VERSION ""

NS_ :

BS_:
BU_: AerodynamicControl AuxiliaryHeater1 AuxiliaryHeater2 AuxiliaryValveControl AxleDrive1 AxleDrive2 AxleSteering BodyController BrakesDriveAxle1 BrakesDriveAxle2 BrakesSteerAxle BrakesSystemController CabController1 CabController2 CabDisplay1 ChassisController1 ChassisController2 ClimateControl1 ClimateControl2 ClutchUnit CommunicationUnitCellular CommunicationUnitRadio CommunicationUnitSatellite CruiseControl ElectricalChargingSystem ElectricalSystem EnduranceBrakingSystem Engine1 Engine2 EngineValveControl ExhaustEmissionController FanDriveController FileServer FuelSystem HeadwayController HitchControl HydraulicPumpController IgnitionController1 IgnitionController2 InformationSystem1 InstrumentCluster LightingOperatorControl ManagementComputer Node_0 Node_1 Node_10 Node_11 Node_12 Node_129 Node_13 Node_130 Node_133 Node_14 Node_15 Node_16 Node_17 Node_18 Node_19 Node_2 Node_20 Node_21 Node_22 Node_23 Node_24 Node_248 Node_249 Node_25 Node_250 Node_251 Node_26 Node_27 Node_28 Node_29 Node_3 Node_30 Node_31 Node_32 Node_33 Node_34 Node_35 Node_36 Node_37 Node_38 Node_39 Node_4 Node_40 Node_41 Node_42 Node_43 Node_44 Node_45 Node_46 Node_47 Node_48 Node_49 Node_5 Node_50 Node_51 Node_52 Node_53 Node_54 Node_55 Node_56 Node_57 Node_58 Node_59 Node_6 Node_60 Node_61 Node_62 Node_63 Node_64 Node_65 Node_66 Node_67 Node_68 Node_69 Node_7 Node_70 Node_71 Node_72 Node_73 Node_74 Node_75 Node_76 Node_77 Node_78 Node_79 Node_8 Node_80 Node_9 OffBoardDiagnosticTool1 OffBoardDiagnosticTool2 OffVehicleGateway OilSensor OnBoardDataLogger OnBoardDiagnosticUnit ParkingBrakeController PneumaticSystemController PowerTakeOff PowerTakeOffFront PropulsionBatteryCharger RampControl RearAxleSteeringController RetarderDriveline RetarderEngine RetarderExhaustEngine1 RetarderExhaustEngine2 SeatControl2 SeatController1 ShiftConsolePrimary ShiftConsoleSecondary StarterSystem SteeringColumnUnit SteeringController SuspensionDriveAxle1 SuspensionDriveAxle2 SuspensionSteerAxle SuspensionSystemController1 SuspensionSystemController2 TirePressureController TractorTrailerBridge1 Transmission1 Transmission2 TransmissionDisplay1 TransmissionDisplay2 TripRecorder Turbocharger VehicleDynamicStability VehicleNavigation VehicleSecurity VirtualTerminal WaterPumpController

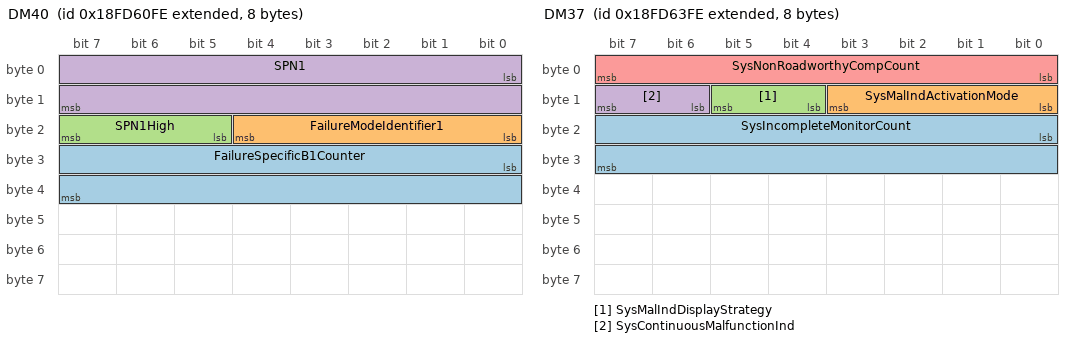
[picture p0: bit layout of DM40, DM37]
BO_ 2566742270 DM40: 8 Vector__XXX
   SG_ FailureSpecificB1Counter : 24|16@1+ (0.1,0) [0|6425.5] "hr" Vector__XXX
   SG_ FailureModeIdentifier1 : 16|5@1+ (1,0) [0|0] "" Vector__XXX
   SG_ SPN1High : 21|3@1+ (1,0) [0|7] "" Vector__XXX
   SG_ SPN1 : 0|16@1+ (1,0) [0|65536] "" Vector__XXX

BO_ 2566742526 DM39: 8 Vector__XXX
   SG_ SysGreatestB1Counter : 32|16@1+ (0.1,0) [0|6425.5] "hr" Vector__XXX
   SG_ SysCumulativeContinuousMITime : 0|32@1+ (0.05,0) [0|2.10554e+08] "hr" Vector__XXX

BO_ 2566742782 DM38: 8 Vector__XXX
   SG_ RegulationDescription : 0|8@1+ (1,0) [0|255] "" Vector__XXX

BO_ 2566743038 DM37: 8 Vector__XXX
   SG_ SysIncompleteMonitorCount : 16|16@1+ (1,0) [0|64512] "" Vector__XXX
   SG_ SysMalIndActivationMode : 8|4@1+ (1,0) [0|15] "" Vector__XXX
   SG_ SysMalIndDisplayStrategy : 12|2@1+ (1,0) [0|3] "" Vector__XXX
   SG_ SysContinuousMalfunctionInd : 14|2@1+ (1,0) [0|3] "" Vector__XXX
   SG_ SysNonRoadworthyCompCount : 0|8@1+ (1,0) [0|250] "" Vector__XXX

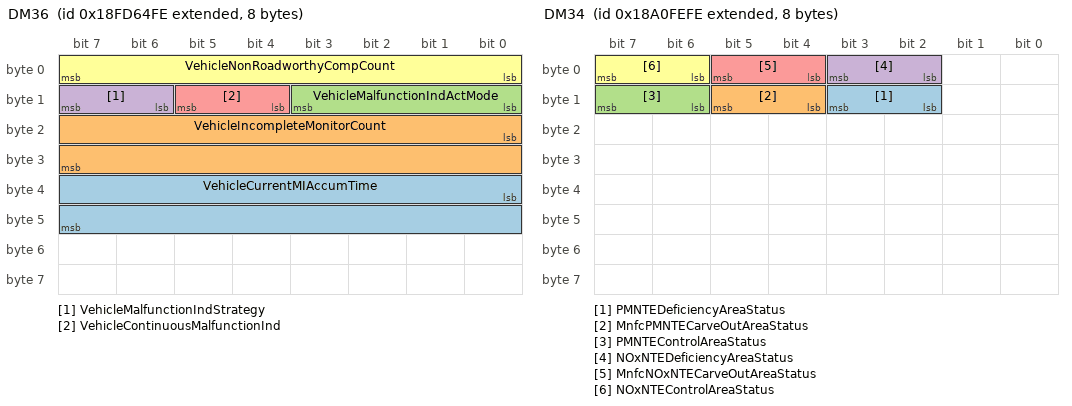
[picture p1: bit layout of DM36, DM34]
BO_ 2566743294 DM36: 8 Vector__XXX
   SG_ VehicleCurrentMIAccumTime : 32|16@1+ (1,0) [0|64255] "min" Vector__XXX
   SG_ VehicleIncompleteMonitorCount : 16|16@1+ (1,0) [0|64255] "" Vector__XXX
   SG_ VehicleMalfunctionIndActMode : 8|4@1+ (1,0) [0|15] "" Vector__XXX
   SG_ VehicleMalfunctionIndStrategy : 14|2@1+ (1,0) [0|3] "" Vector__XXX
   SG_ VehicleContinuousMalfunctionInd : 12|2@1+ (1,0) [0|3] "" Vector__XXX
   SG_ VehicleNonRoadworthyCompCount : 0|8@1+ (1,0) [0|250] "" Vector__XXX

BO_ 2560687870 DM34: 8 Vector__XXX
   SG_ PMNTEDeficiencyAreaStatus : 10|2@1+ (1,0) [0|3] "" Vector__XXX
   SG_ MnfcPMNTECarveOutAreaStatus : 12|2@1+ (1,0) [0|3] "" Vector__XXX
   SG_ PMNTEControlAreaStatus : 14|2@1+ (1,0) [0|3] "" Vector__XXX
   SG_ NOxNTEDeficiencyAreaStatus : 2|2@1+ (1,0) [0|3] "" Vector__XXX
   SG_ MnfcNOxNTECarveOutAreaStatus : 4|2@1+ (1,0) [0|3] "" Vector__XXX
   SG_ NOxNTEControlAreaStatus : 6|2@1+ (1,0) [0|3] "" Vector__XXX

BO_ 2292317950 DM33: 9 Vector__XXX
   SG_ AECDEngineHours1Timer2 : 40|32@1+ (1,0) [0|4.29497e+09] "min" Vector__XXX
   SG_ AECDEngineHours1Timer1 : 8|32@1+ (1,0) [0|4.29497e+09] "min" Vector__XXX
   SG_ AECDNumber1 : 0|8@1+ (1,0) [0|250] "" Vector__XXX

BO_ 2566809342 BM: 8 Vector__XXX
   SG_ BatteryMainSwitchHoldState : 0|2@1+ (1,0) [0|3] "" Vector__XXX

BO_ 2365446910 BJM3: 8 Vector__XXX
   SG_ Joystick3XAxisDetentPosStatus : 38|2@1+ (1,0) [0|3] "" Vector__XXX
   SG_ Joystick3Button9PressedStatus : 62|2@1+ (1,0) [0|3] "" Vector__XXX
   SG_ Joystick3Button10PressedStatus : 60|2@1+ (1,0) [0|3] "" Vector__XXX
   SG_ Joystick3Button11PressedStatus : 58|2@1+ (1,0) [0|3] "" Vector__XXX
   SG_ Joystick3Button12PressedStatus : 56|2@1+ (1,0) [0|3] "" Vector__XXX
   SG_ Joystick3YAxisDetentPosStatus : 36|2@1+ (1,0) [0|3] "" Vector__XXX
   SG_ Joystick3YAxisPos : 22|10@1+ (0.1,0) [0|102] "%" Vector__XXX
   SG_ Jystck3YAxsLvrFrwrdPstvPsStatus : 20|2@1+ (1,0) [0|3] "" Vector__XXX
   SG_ Jystck3YAxsLvrBckNgtvePosStatus : 18|2@1+ (1,0) [0|3] "" Vector__XXX
   SG_ Joystick3YAxisNeutralPosStatus : 16|2@1+ (1,0) [0|3] "" Vector__XXX
   SG_ Joystick3XAxisPos : 6|10@1+ (0.1,0) [0|102] "%" Vector__XXX
   SG_ Jystck3XAxsLvrRghtPstvPosStatus : 4|2@1+ (1,0) [0|3] "" Vector__XXX
   SG_ Jystck3XAxsLvrLftNgtvePosStatus : 2|2@1+ (1,0) [0|3] "" Vector__XXX
   SG_ Joystick3XAxisNeutralPosStatus : 0|2@1+ (1,0) [0|3] "" Vector__XXX
   SG_ Joystick3Button5PressedStatus : 54|2@1+ (1,0) [0|3] "" Vector__XXX
   SG_ Joystick3Button6PressedStatus : 52|2@1+ (1,0) [0|3] "" Vector__XXX
   SG_ Joystick3Button7PressedStatus : 50|2@1+ (1,0) [0|3] "" Vector__XXX
   SG_ Joystick3Button8PressedStatus : 48|2@1+ (1,0) [0|3] "" Vector__XXX
   SG_ Joystick3Button1PressedStatus : 46|2@1+ (1,0) [0|3] "" Vector__XXX
   SG_ Joystick3Button2PressedStatus : 44|2@1+ (1,0) [0|3] "" Vector__XXX
   SG_ Joystick3Button3PressedStatus : 42|2@1+ (1,0) [0|3] "" Vector__XXX
   SG_ Joystick3Button4PressedStatus : 40|2@1+ (1,0) [0|3] "" Vector__XXX

BO_ 2365446398 BJM2: 8 Vector__XXX
   SG_ Joystick2XAxisDetentPosStatus : 38|2@1+ (1,0) [0|3] "" Vector__XXX
   SG_ Joystick2YAxisDetentPosStatus : 36|2@1+ (1,0) [0|3] "" Vector__XXX
   SG_ Joystick2YAxisPos : 22|10@1+ (0.1,0) [0|102] "%" Vector__XXX
   SG_ Jystck2YAxsLvrFrwrdPstvPsStatus : 20|2@1+ (1,0) [0|3] "" Vector__XXX
   SG_ Jystck2YAxsLvrBckNgtvePosStatus : 18|2@1+ (1,0) [0|3] "" Vector__XXX
   SG_ Joystick2YAxisNeutralPosStatus : 16|2@1+ (1,0) [0|3] "" Vector__XXX
   SG_ Joystick2XAxisPos : 6|10@1+ (0.1,0) [0|102] "%" Vector__XXX
   SG_ Jystck2XAxsLvrRghtPstvPosStatus : 4|2@1+ (1,0) [0|3] "" Vector__XXX
   SG_ Jystck2XAxsLvrLftNgtvePosStatus : 2|2@1+ (1,0) [0|3] "" Vector__XXX
   SG_ Joystick2XAxisNeutralPosStatus : 0|2@1+ (1,0) [0|3] "" Vector__XXX
   SG_ Joystick2Button9PressedStatus : 62|2@1+ (1,0) [0|3] "" Vector__XXX
   SG_ Joystick2Button10PressedStatus : 60|2@1+ (1,0) [0|3] "" Vector__XXX
   SG_ Joystick2Button11PressedStatus : 58|2@1+ (1,0) [0|3] "" Vector__XXX
   SG_ Joystick2Button12PressedStatus : 56|2@1+ (1,0) [0|3] "" Vector__XXX
   SG_ Joystick2Button5PressedStatus : 54|2@1+ (1,0) [0|3] "" Vector__XXX
   SG_ Joystick2Button6PressedStatus : 52|2@1+ (1,0) [0|3] "" Vector__XXX
   SG_ Joystick2Button7PressedStatus : 50|2@1+ (1,0) [0|3] "" Vector__XXX
   SG_ Joystick2Button8PressedStatus : 48|2@1+ (1,0) [0|3] "" Vector__XXX
   SG_ Joystick2Button1PressedStatus : 46|2@1+ (1,0) [0|3] "" Vector__XXX
   SG_ Joystick2Button2PressedStatus : 44|2@1+ (1,0) [0|3] "" Vector__XXX
   SG_ Joystick2Button3PressedStatus : 42|2@1+ (1,0) [0|3] "" Vector__XXX
   SG_ Joystick2Button4PressedStatus : 40|2@1+ (1,0) [0|3] "" Vector__XXX

BO_ 2365445886 BJM1: 8 Vector__XXX
   SG_ Joystick1XAxisDetentPosStatus : 38|2@1+ (1,0) [0|3] "" Vector__XXX
   SG_ Joystick1YAxisDetentPosStatus : 36|2@1+ (1,0) [0|3] "" Vector__XXX
   SG_ Joystick1YAxisPos : 22|10@1+ (0.1,0) [0|102] "%" Vector__XXX
   SG_ Jystck1YAxsLvrFrwrdPstvPsStatus : 20|2@1+ (1,0) [0|3] "" Vector__XXX
   SG_ Jystck1YAxsLvrBckNgtvePosStatus : 18|2@1+ (1,0) [0|3] "" Vector__XXX
   SG_ Joystick1YAxisNeutralPosStatus : 16|2@1+ (1,0) [0|3] "" Vector__XXX
   SG_ Joystick1XAxisPos : 6|10@1+ (0.1,0) [0|102] "%" Vector__XXX
   SG_ Joystick1Button9PressedStatus : 62|2@1+ (1,0) [0|3] "" Vector__XXX
   SG_ Joystick1Button10PressedStatus : 60|2@1+ (1,0) [0|3] "" Vector__XXX
   SG_ Joystick1Button11PressedStatus : 58|2@1+ (1,0) [0|3] "" Vector__XXX
   SG_ Joystick1Button12PressedStatus : 56|2@1+ (1,0) [0|3] "" Vector__XXX
   SG_ Joystick1Button5PressedStatus : 54|2@1+ (1,0) [0|3] "" Vector__XXX
   SG_ Joystick1Button6PressedStatus : 52|2@1+ (1,0) [0|3] "" Vector__XXX
   SG_ Joystick1Button7PressedStatus : 50|2@1+ (1,0) [0|3] "" Vector__XXX
   SG_ Joystick1Button8PressedStatus : 48|2@1+ (1,0) [0|3] "" Vector__XXX
   SG_ Joystick1Button1PressedStatus : 46|2@1+ (1,0) [0|3] "" Vector__XXX
   SG_ Joystick1Button2PressedStatus : 44|2@1+ (1,0) [0|3] "" Vector__XXX
   SG_ Joystick1Button3PressedStatus : 42|2@1+ (1,0) [0|3] "" Vector__XXX
   SG_ Joystick1Button4PressedStatus : 40|2@1+ (1,0) [0|3] "" Vector__XXX
   SG_ Jystck1XAxsLvrRghtPstvPosStatus : 4|2@1+ (1,0) [0|3] "" Vector__XXX
   SG_ Jystck1XAxsLvrLftNgtvePosStatus : 2|2@1+ (1,0) [0|3] "" Vector__XXX
   SG_ Joystick1XAxisNeutralPosStatus : 0|2@1+ (1,0) [0|3] "" Vector__XXX

BO_ 2566847230 B: 8 Vector__XXX
   SG_ ParkingBrakeRedWarningSignal : 26|2@1+ (1,0) [0|3] "" Vector__XXX
   SG_ ParkBrakeReleaseInhibitStatus : 28|2@1+ (1,0) [0|3] "" Vector__XXX
   SG_ ParkingBrakeActuator : 24|2@1+ (1,0) [0|3] "" Vector__XXX
   SG_ BrakeSecondPress : 16|8@1+ (4,0) [0|1000] "kPa" Vector__XXX
   SG_ BrakePrimaryPress : 8|8@1+ (4,0) [0|1000] "kPa" Vector__XXX
   SG_ BrakeAppPress : 0|8@1+ (4,0) [0|1000] "kPa" Vector__XXX

BO_ 2566848254 AWPP: 8 Vector__XXX
   SG_ AuxPumpPress : 0|8@1+ (16,0) [0|4000] "kPa" Vector__XXX

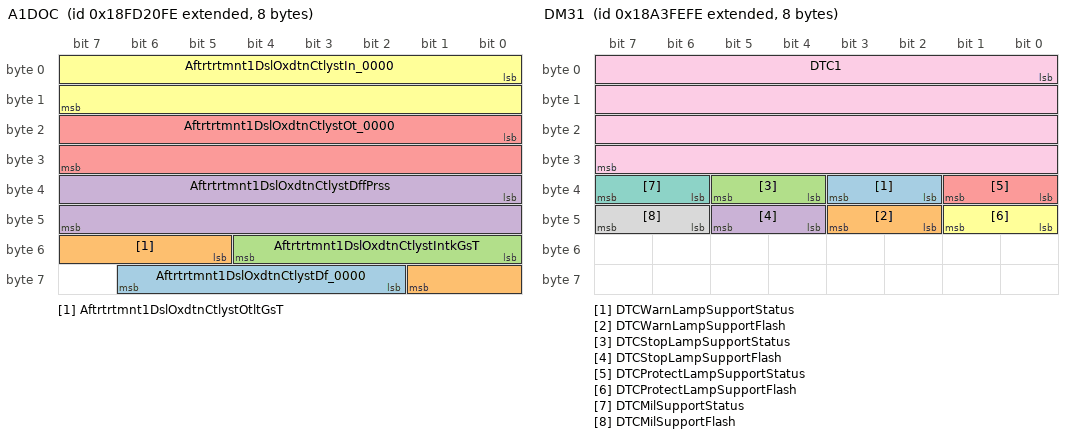
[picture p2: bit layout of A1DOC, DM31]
BO_ 2566725886 A1DOC: 8 Vector__XXX
   SG_ Aftrtrtmnt1DslOxdtnCtlystDf_0000 : 58|5@1+ (1,0) [0|31] "" Vector__XXX
   SG_ Aftrtrtmnt1DslOxdtnCtlystOtltGsT : 53|5@1+ (1,0) [0|31] "" Vector__XXX
   SG_ Aftrtrtmnt1DslOxdtnCtlystIntkGsT : 48|5@1+ (1,0) [0|31] "" Vector__XXX
   SG_ Aftrtrtmnt1DslOxdtnCtlystDffPrss : 32|16@1+ (0.1,0) [0|6425.5] "kPa" Vector__XXX
   SG_ Aftrtrtmnt1DslOxdtnCtlystOt_0000 : 16|16@1+ (0.03125,-273) [-273|1734.97] "deg C" Vector__XXX
   SG_ Aftrtrtmnt1DslOxdtnCtlystIn_0000 : 0|16@1+ (0.03125,-273) [-273|1734.97] "deg C" Vector__XXX

BO_ 2560884478 DM31: 8 Vector__XXX
   SG_ DTCWarnLampSupportStatus : 34|2@1+ (1,0) [0|3] "" Vector__XXX
   SG_ DTCWarnLampSupportFlash : 42|2@1+ (1,0) [0|3] "" Vector__XXX
   SG_ DTCStopLampSupportStatus : 36|2@1+ (1,0) [0|3] "" Vector__XXX
   SG_ DTCStopLampSupportFlash : 44|2@1+ (1,0) [0|3] "" Vector__XXX
   SG_ DTCProtectLampSupportStatus : 32|2@1+ (1,0) [0|3] "" Vector__XXX
   SG_ DTCProtectLampSupportFlash : 40|2@1+ (1,0) [0|3] "" Vector__XXX
   SG_ DTCMilSupportStatus : 38|2@1+ (1,0) [0|3] "" Vector__XXX
   SG_ DTCMilSupportFlash : 46|2@1+ (1,0) [0|3] "" Vector__XXX
   SG_ DTC1 : 0|32@1+ (1,0) [0|4.29497e+09] "" Vector__XXX

BO_ 2633844734 TML: 8 Vector__XXX

BO_ 2560360190 PMI: 8 Vector__XXX
   SG_ DataDictionaryMethod : 11|21@1+ (1,0) [0|2.09715e+06] "" Vector__XXX
   SG_ DataDictionaryManufacturerCode : 0|11@1+ (1,0) [0|2047] "" Vector__XXX

BO_ 2566736126 O2FT2: 8 Vector__XXX
   SG_ ShorttermFuelTrimBank2 : 16|16@1+ (0.1,-100) [-100|100] "%" Vector__XXX
   SG_ LongtermFuelTrimBank2 : 0|16@1+ (0.1,-100) [-100|100] "%" Vector__XXX
   SG_ EngExhstGsOxygnSnsrClsdLpOprtnBn : 32|4@1+ (1,0) [0|15] "" Vector__XXX

BO_ 2566736382 O2FT1: 8 Vector__XXX
   SG_ ShorttermFuelTrimBank1 : 16|16@1+ (0.1,-100) [-100|100] "%" Vector__XXX
   SG_ LongtermFuelTrimBank1 : 0|16@1+ (0.1,-100) [-100|100] "%" Vector__XXX
   SG_ EngExhstGsOxygnSnsrClsdLpOp_0000 : 32|4@1+ (1,0) [0|15] "" Vector__XXX

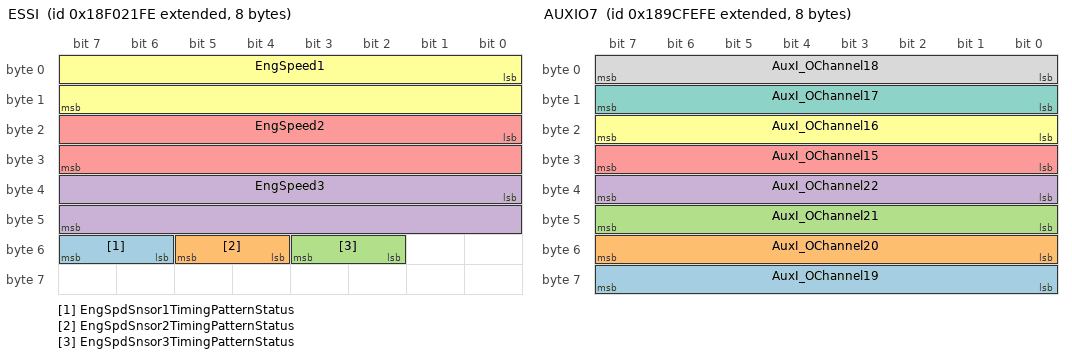
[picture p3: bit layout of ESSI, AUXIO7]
BO_ 2565874174 ESSI: 8 Vector__XXX
   SG_ EngSpdSnsor1TimingPatternStatus : 54|2@1+ (1,0) [0|3] "" Vector__XXX
   SG_ EngSpdSnsor2TimingPatternStatus : 52|2@1+ (1,0) [0|3] "" Vector__XXX
   SG_ EngSpdSnsor3TimingPatternStatus : 50|2@1+ (1,0) [0|3] "" Vector__XXX
   SG_ EngSpeed3 : 32|16@1+ (0.5,0) [0|32127.5] "rpm" Vector__XXX
   SG_ EngSpeed2 : 16|16@1+ (0.5,0) [0|32127.5] "rpm" Vector__XXX
   SG_ EngSpeed1 : 0|16@1+ (0.5,0) [0|32127.5] "rpm" Vector__XXX

BO_ 2432520958 ECCVC: 8 Vector__XXX
   SG_ DsrdEngCoolantThermostatOpening : 16|8@1+ (0.4,0) [0|100] "%" Vector__XXX
   SG_ DesiredEngCoolantPumpOutletTemp : 8|8@1+ (1,-40) [-40|210] "deg C" Vector__XXX
   SG_ EngCoolantThermostatMode : 0|2@1+ (1,0) [0|3] "" Vector__XXX

BO_ 2560425726 AUXIO7: 8 Vector__XXX
   SG_ AuxI_OChannel19 : 56|8@1+ (1,0) [0|250] "" Vector__XXX
   SG_ AuxI_OChannel20 : 48|8@1+ (1,0) [0|250] "" Vector__XXX
   SG_ AuxI_OChannel21 : 40|8@1+ (1,0) [0|250] "" Vector__XXX
   SG_ AuxI_OChannel22 : 32|8@1+ (1,0) [0|250] "" Vector__XXX
   SG_ AuxI_OChannel15 : 24|8@1+ (1,0) [0|250] "" Vector__XXX
   SG_ AuxI_OChannel16 : 16|8@1+ (1,0) [0|250] "" Vector__XXX
   SG_ AuxI_OChannel17 : 8|8@1+ (1,0) [0|250] "" Vector__XXX
   SG_ AuxI_OChannel18 : 0|8@1+ (1,0) [0|250] "" Vector__XXX

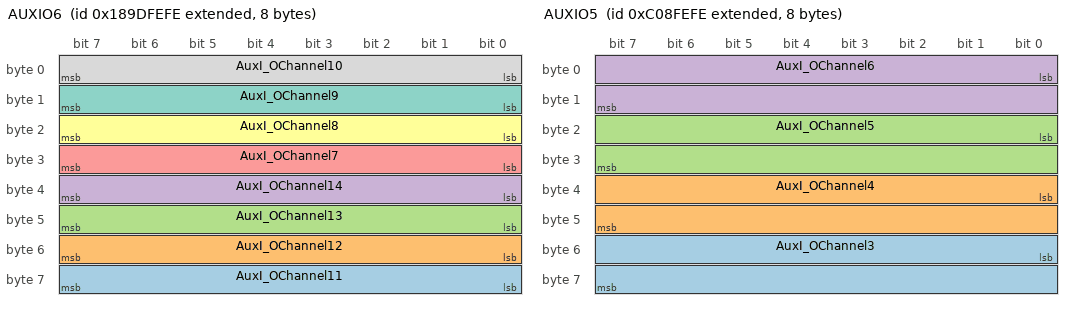
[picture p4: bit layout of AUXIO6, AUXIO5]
BO_ 2560491262 AUXIO6: 8 Vector__XXX
   SG_ AuxI_OChannel11 : 56|8@1+ (1,0) [0|250] "" Vector__XXX
   SG_ AuxI_OChannel12 : 48|8@1+ (1,0) [0|250] "" Vector__XXX
   SG_ AuxI_OChannel13 : 40|8@1+ (1,0) [0|250] "" Vector__XXX
   SG_ AuxI_OChannel14 : 32|8@1+ (1,0) [0|250] "" Vector__XXX
   SG_ AuxI_OChannel7 : 24|8@1+ (1,0) [0|250] "" Vector__XXX
   SG_ AuxI_OChannel8 : 16|8@1+ (1,0) [0|250] "" Vector__XXX
   SG_ AuxI_OChannel9 : 8|8@1+ (1,0) [0|250] "" Vector__XXX
   SG_ AuxI_OChannel10 : 0|8@1+ (1,0) [0|250] "" Vector__XXX

BO_ 2349399806 AUXIO5: 8 Vector__XXX
   SG_ AuxI_OChannel3 : 48|16@1+ (1,0) [0|64255] "counts" Vector__XXX
   SG_ AuxI_OChannel4 : 32|16@1+ (1,0) [0|64255] "counts" Vector__XXX
   SG_ AuxI_OChannel5 : 16|16@1+ (1,0) [0|64255] "counts" Vector__XXX
   SG_ AuxI_OChannel6 : 0|16@1+ (1,0) [0|64255] "counts" Vector__XXX

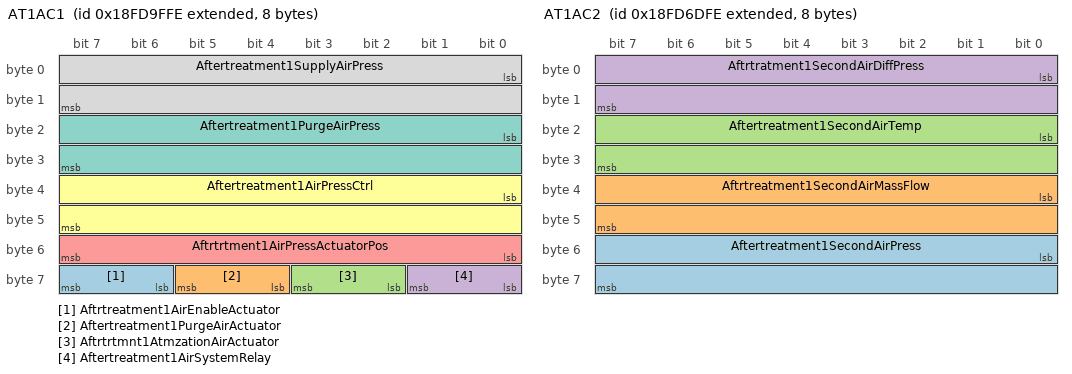
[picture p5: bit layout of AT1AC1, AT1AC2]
BO_ 2566758398 AT1AC1: 8 Vector__XXX
   SG_ Aftrtreatment1AirEnableActuator : 62|2@1+ (1,0) [0|3] "" Vector__XXX
   SG_ Aftertreatment1PurgeAirActuator : 60|2@1+ (1,0) [0|3] "" Vector__XXX
   SG_ Aftrtrtmnt1AtmzationAirActuator : 58|2@1+ (1,0) [0|3] "" Vector__XXX
   SG_ Aftertreatment1AirSystemRelay : 56|2@1+ (1,0) [0|3] "" Vector__XXX
   SG_ Aftrtrtment1AirPressActuatorPos : 48|8@1+ (0.4,0) [0|100] "%" Vector__XXX
   SG_ Aftertreatment1AirPressCtrl : 32|16@1+ (0.0025,0) [0|160.637] "%" Vector__XXX
   SG_ Aftertreatment1PurgeAirPress : 16|16@1+ (0.1,0) [0|6425.5] "kPa" Vector__XXX
   SG_ Aftertreatment1SupplyAirPress : 0|16@1+ (0.1,0) [0|6425.5] "kPa" Vector__XXX

BO_ 2566745598 AT1AC2: 8 Vector__XXX
   SG_ Aftertreatment1SecondAirPress : 48|16@1+ (0.1,0) [0|6425.5] "kPa" Vector__XXX
   SG_ Aftrtreatment1SecondAirMassFlow : 32|16@1+ (0.2,0) [0|12851] "kg/h" Vector__XXX
   SG_ Aftertreatment1SecondAirTemp : 16|16@1+ (0.03125,-273) [-273|1734.97] "deg C" Vector__XXX
   SG_ Aftrtratment1SecondAirDiffPress : 0|16@1+ (0.0078125,-250) [-250|251.99] "kPa" Vector__XXX

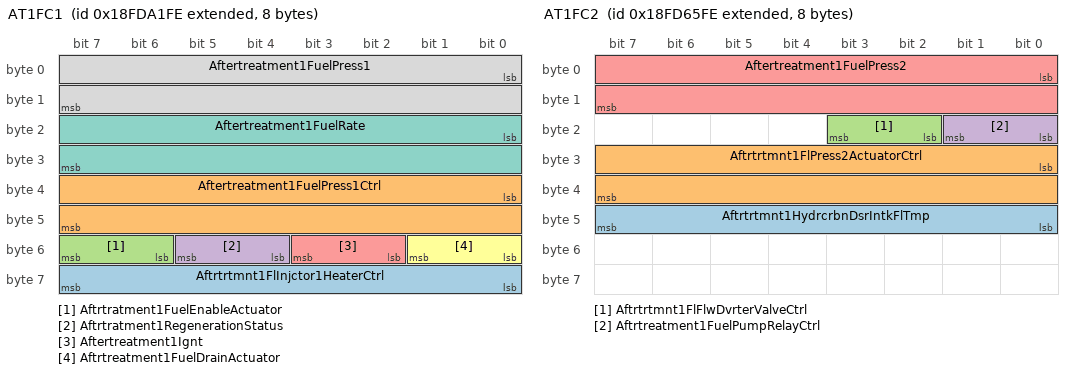
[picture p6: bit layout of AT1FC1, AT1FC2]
BO_ 2566758910 AT1FC1: 8 Vector__XXX
   SG_ Aftrtrtmnt1FlInjctor1HeaterCtrl : 56|8@1+ (0.4,0) [0|100] "%" Vector__XXX
   SG_ Aftertreatment1FuelPress1Ctrl : 32|16@1+ (0.0025,0) [0|160.637] "%" Vector__XXX
   SG_ Aftrtratment1FuelEnableActuator : 54|2@1+ (1,0) [0|3] "" Vector__XXX
   SG_ Aftrtratment1RegenerationStatus : 52|2@1+ (1,0) [0|3] "" Vector__XXX
   SG_ Aftertreatment1Ignt : 50|2@1+ (1,0) [0|3] "" Vector__XXX
   SG_ Aftrtreatment1FuelDrainActuator : 48|2@1+ (1,0) [0|3] "" Vector__XXX
   SG_ Aftertreatment1FuelRate : 16|16@1+ (0.05,0) [0|3212.75] "L/h" Vector__XXX
   SG_ Aftertreatment1FuelPress1 : 0|16@1+ (0.1,0) [0|6425.5] "kPa" Vector__XXX

BO_ 2566743550 AT1FC2: 8 Vector__XXX
   SG_ Aftrtrtmnt1HydrcrbnDsrIntkFlTmp : 40|8@1+ (1,-40) [-40|210] "deg C" Vector__XXX
   SG_ Aftrtrtmnt1FlPress2ActuatorCtrl : 24|16@1+ (0.0025,0) [0|160.637] "%" Vector__XXX
   SG_ Aftrtrtmnt1FlFlwDvrterValveCtrl : 18|2@1+ (1,0) [0|3] "" Vector__XXX
   SG_ Aftrtreatment1FuelPumpRelayCtrl : 16|2@1+ (1,0) [0|3] "" Vector__XXX
   SG_ Aftertreatment1FuelPress2 : 0|16@1+ (0.1,0) [0|6425.5] "kPa" Vector__XXX

BO_ 2566753534 AT1GP: 8 Vector__XXX
   SG_ DslPrticulateFilterOutletPress1 : 16|16@1+ (0.1,0) [0|6425.5] "kPa" Vector__XXX
   SG_ DslPrticulateFilterIntakePress1 : 0|16@1+ (0.1,0) [0|6425.5] "kPa" Vector__XXX

BO_ 2566756606 AT1HI: 36 Vector__XXX
   SG_ Aftrtrtmnt1TtlNmbrOfActvRgnrtnMn : 224|32@1+ (1,0) [0|4.29497e+09] "counts" Vector__XXX
   SG_ Aftrtrtmnt1TtlNmbrOfActvRgnrtnIn : 192|32@1+ (1,0) [0|4.29497e+09] "counts" Vector__XXX
   SG_ Aftrtrtmnt1AvrgTmBtwnActvRgnrtns : 256|32@1+ (1,0) [0|4.21108e+09] "s" Vector__XXX
   SG_ Aftrtrtmnt1TtlNmbrOfPssvRgnrtns : 160|32@1+ (1,0) [0|4.29497e+09] "counts" Vector__XXX
   SG_ Aftrtrtmnt1TtlPssvRgnrationTime : 128|32@1+ (1,0) [0|4.21108e+09] "s" Vector__XXX
   SG_ Aftrtrtmnt1TtlNmbrOfActvRgnrtns : 96|32@1+ (1,0) [0|4.29497e+09] "counts" Vector__XXX
   SG_ Aftrtreatment1TotalDisabledTime : 64|32@1+ (1,0) [0|4.21108e+09] "s" Vector__XXX
   SG_ Aftrtrtmnt1TtalRegenerationTime : 32|32@1+ (1,0) [0|4.21108e+09] "s" Vector__XXX
   SG_ Aftertreatment1TotalFuelUsed : 0|32@1+ (0.5,0) [0|2.10554e+09] "L" Vector__XXX

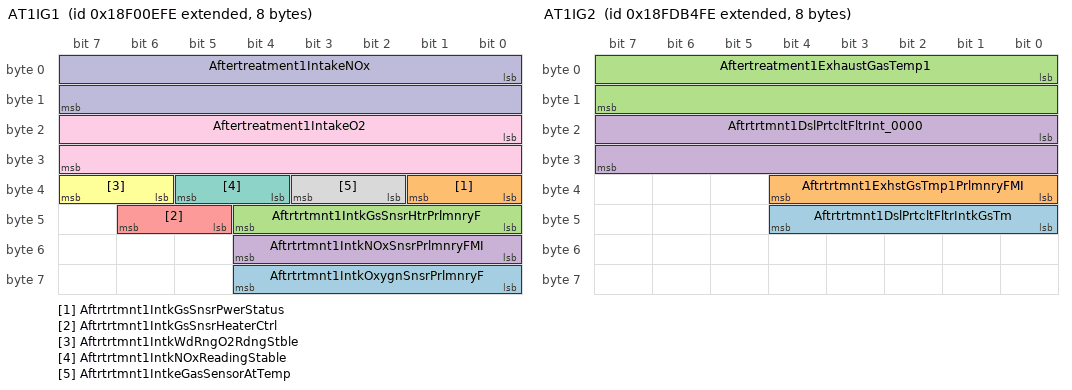
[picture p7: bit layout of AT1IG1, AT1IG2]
BO_ 2565869310 AT1IG1: 8 Vector__XXX
   SG_ Aftrtrtmnt1IntkOxygnSnsrPrlmnryF : 56|5@1+ (1,0) [0|31] "" Vector__XXX
   SG_ Aftrtrtmnt1IntkGsSnsrPwerStatus : 32|2@1+ (1,0) [0|3] "" Vector__XXX
   SG_ Aftrtrtmnt1IntkGsSnsrHtrPrlmnryF : 40|5@1+ (1,0) [0|31] "" Vector__XXX
   SG_ Aftrtrtmnt1IntkNOxSnsrPrlmnryFMI : 48|5@1+ (1,0) [0|31] "" Vector__XXX
   SG_ Aftrtrtmnt1IntkGsSnsrHeaterCtrl : 45|2@1+ (1,0) [0|3] "" Vector__XXX
   SG_ Aftrtrtmnt1IntkWdRngO2RdngStble : 38|2@1+ (1,0) [0|3] "" Vector__XXX
   SG_ Aftrtrtmnt1IntkNOxReadingStable : 36|2@1+ (1,0) [0|3] "" Vector__XXX
   SG_ Aftrtrtmnt1IntkeGasSensorAtTemp : 34|2@1+ (1,0) [0|3] "" Vector__XXX
   SG_ Aftertreatment1IntakeO2 : 16|16@1+ (0.000514,-12) [-12|21] "%" Vector__XXX
   SG_ Aftertreatment1IntakeNOx : 0|16@1+ (0.05,-200) [-200|3012.75] "ppm" Vector__XXX

BO_ 2566763774 AT1IG2: 8 Vector__XXX
   SG_ Aftrtrtmnt1DslPrtcltFltrIntkGsTm : 40|5@1+ (1,0) [0|31] "" Vector__XXX
   SG_ Aftrtrtmnt1ExhstGsTmp1PrlmnryFMI : 32|5@1+ (1,0) [0|31] "" Vector__XXX
   SG_ Aftertreatment1ExhaustGasTemp1 : 0|16@1+ (0.03125,-273) [-273|1734.97] "deg C" Vector__XXX
   SG_ Aftrtrtmnt1DslPrtcltFltrInt_0000 : 16|16@1+ (0.03125,-273) [-273|1734.97] "deg C" Vector__XXX

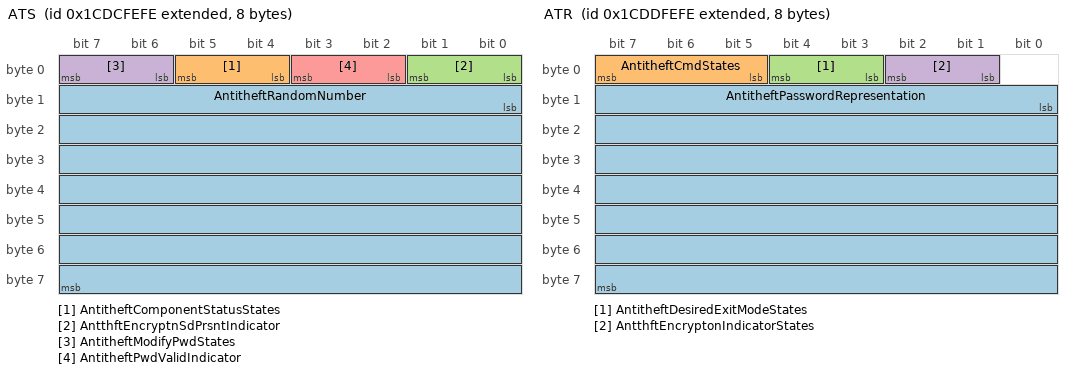
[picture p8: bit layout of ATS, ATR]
BO_ 2631728894 ATS: 8 Vector__XXX
   SG_ AntitheftRandomNumber : 8|56@1+ (1,0) [0|255] "" Vector__XXX
   SG_ AntitheftComponentStatusStates : 4|2@1+ (1,0) [0|3] "" Vector__XXX
   SG_ AntthftEncryptnSdPrsntIndicator : 0|2@1+ (1,0) [0|3] "" Vector__XXX
   SG_ AntitheftModifyPwdStates : 6|2@1+ (1,0) [0|3] "" Vector__XXX
   SG_ AntitheftPwdValidIndicator : 2|2@1+ (1,0) [0|3] "" Vector__XXX

BO_ 2631794430 ATR: 8 Vector__XXX
   SG_ AntitheftPasswordRepresentation : 8|56@1+ (1,0) [0|255] "" Vector__XXX
   SG_ AntitheftCmdStates : 5|3@1+ (1,0) [0|7] "" Vector__XXX
   SG_ AntitheftDesiredExitModeStates : 3|2@1+ (1,0) [0|3] "" Vector__XXX
   SG_ AntthftEncryptonIndicatorStates : 1|2@1+ (1,0) [0|3] "" Vector__XXX

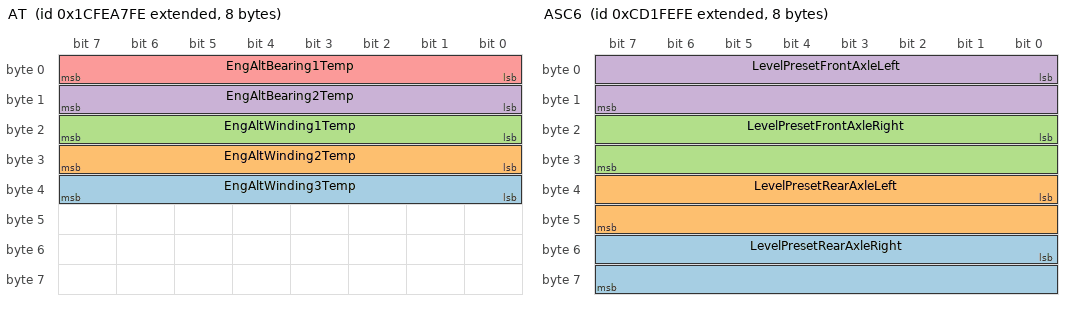
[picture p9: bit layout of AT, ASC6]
BO_ 2633934846 AT: 8 Vector__XXX
   SG_ EngAltWinding3Temp : 32|8@1+ (1,-40) [-40|210] "deg C" Vector__XXX
   SG_ EngAltWinding2Temp : 24|8@1+ (1,-40) [-40|210] "deg C" Vector__XXX
   SG_ EngAltWinding1Temp : 16|8@1+ (1,-40) [-40|210] "deg C" Vector__XXX
   SG_ EngAltBearing2Temp : 8|8@1+ (1,-40) [-40|210] "deg C" Vector__XXX
   SG_ EngAltBearing1Temp : 0|8@1+ (1,-40) [-40|210] "deg C" Vector__XXX

BO_ 2362572542 ASC6: 8 Vector__XXX
   SG_ LevelPresetRearAxleRight : 48|16@1+ (0.1,-3200) [-3200|3225.5] "mm" Vector__XXX
   SG_ LevelPresetRearAxleLeft : 32|16@1+ (0.1,-3200) [-3200|3225.5] "mm" Vector__XXX
   SG_ LevelPresetFrontAxleRight : 16|16@1+ (0.1,-3200) [-3200|3225.5] "mm" Vector__XXX
   SG_ LevelPresetFrontAxleLeft : 0|16@1+ (0.1,-3200) [-3200|3225.5] "mm" Vector__XXX

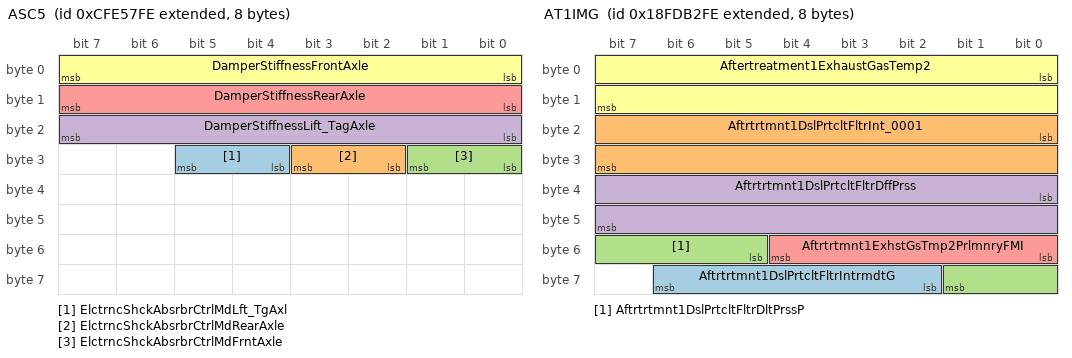
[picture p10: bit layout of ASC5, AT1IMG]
BO_ 2365478910 ASC5: 8 Vector__XXX
   SG_ ElctrncShckAbsrbrCtrlMdLft_TgAxl : 28|2@1+ (1,0) [0|3] "" Vector__XXX
   SG_ ElctrncShckAbsrbrCtrlMdRearAxle : 26|2@1+ (1,0) [0|3] "" Vector__XXX
   SG_ ElctrncShckAbsrbrCtrlMdFrntAxle : 24|2@1+ (1,0) [0|3] "" Vector__XXX
   SG_ DamperStiffnessLift_TagAxle : 16|8@1+ (0.4,0) [0|100] "%" Vector__XXX
   SG_ DamperStiffnessRearAxle : 8|8@1+ (0.4,0) [0|100] "%" Vector__XXX
   SG_ DamperStiffnessFrontAxle : 0|8@1+ (0.4,0) [0|100] "%" Vector__XXX

BO_ 2560950014 DM30: 12 Vector__XXX
   SG_ TestLimitMinimum : 80|16@1+ (1,0) [0|64255] "" Vector__XXX
   SG_ TestLimitMaximum : 64|16@1+ (1,0) [0|64255] "" Vector__XXX
   SG_ TestValue : 48|16@1+ (1,0) [0|64255] "" Vector__XXX
   SG_ SlotId : 32|16@1+ (1,0) [0|64255] "" Vector__XXX
   SG_ TestIdentifier : 0|8@1+ (1,0) [0|255] "" Vector__XXX
   SG_ FailureModeIdentifier1 : 24|5@1+ (1,0) [0|0] "" Vector__XXX
   SG_ SPN1High : 29|3@1+ (1,0) [0|7] "" Vector__XXX
   SG_ SPN1 : 8|16@1+ (1,0) [0|65536] "" Vector__XXX

BO_ 2566763262 AT1IMG: 8 Vector__XXX
   SG_ Aftrtrtmnt1DslPrtcltFltrIntrmdtG : 58|5@1+ (1,0) [0|31] "" Vector__XXX
   SG_ Aftrtrtmnt1DslPrtcltFltrInt_0001 : 16|16@1+ (0.03125,-273) [-273|1734.97] "deg C" Vector__XXX
   SG_ Aftrtrtmnt1DslPrtcltFltrDltPrssP : 53|5@1+ (1,0) [0|31] "" Vector__XXX
   SG_ Aftrtrtmnt1DslPrtcltFltrDffPrss : 32|16@1+ (0.1,0) [0|6425.5] "kPa" Vector__XXX
   SG_ Aftrtrtmnt1ExhstGsTmp2PrlmnryFMI : 48|5@1+ (1,0) [0|31] "" Vector__XXX
   SG_ Aftertreatment1ExhaustGasTemp2 : 0|16@1+ (0.03125,-273) [-273|1734.97] "deg C" Vector__XXX

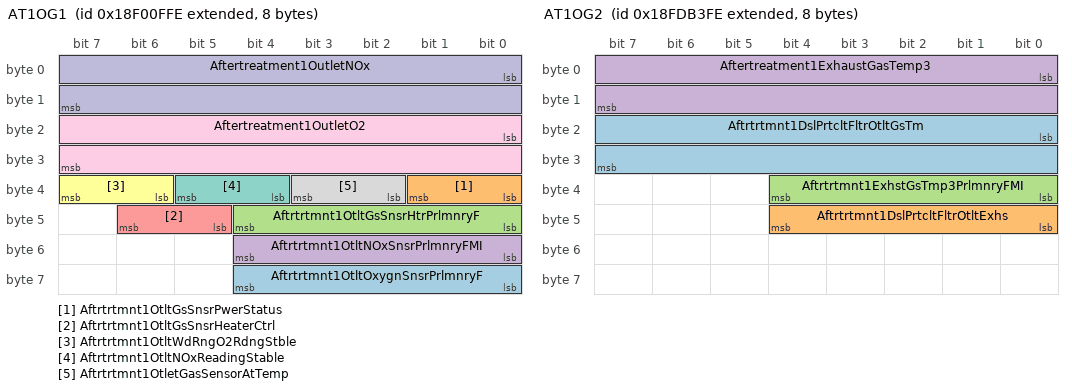
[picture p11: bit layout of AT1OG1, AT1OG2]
BO_ 2565869566 AT1OG1: 8 Vector__XXX
   SG_ Aftrtrtmnt1OtltOxygnSnsrPrlmnryF : 56|5@1+ (1,0) [0|31] "" Vector__XXX
   SG_ Aftrtrtmnt1OtltGsSnsrPwerStatus : 32|2@1+ (1,0) [0|3] "" Vector__XXX
   SG_ Aftrtrtmnt1OtltGsSnsrHtrPrlmnryF : 40|5@1+ (1,0) [0|31] "" Vector__XXX
   SG_ Aftrtrtmnt1OtltNOxSnsrPrlmnryFMI : 48|5@1+ (1,0) [0|31] "" Vector__XXX
   SG_ Aftrtrtmnt1OtltGsSnsrHeaterCtrl : 45|2@1+ (1,0) [0|3] "" Vector__XXX
   SG_ Aftrtrtmnt1OtltWdRngO2RdngStble : 38|2@1+ (1,0) [0|3] "" Vector__XXX
   SG_ Aftrtrtmnt1OtltNOxReadingStable : 36|2@1+ (1,0) [0|3] "" Vector__XXX
   SG_ Aftrtrtmnt1OtletGasSensorAtTemp : 34|2@1+ (1,0) [0|3] "" Vector__XXX
   SG_ Aftertreatment1OutletO2 : 16|16@1+ (0.000514,-12) [-12|21] "%" Vector__XXX
   SG_ Aftertreatment1OutletNOx : 0|16@1+ (0.05,-200) [-200|3012.75] "ppm" Vector__XXX

BO_ 2566763518 AT1OG2: 8 Vector__XXX
   SG_ Aftrtrtmnt1DslPrtcltFltrOtltGsTm : 16|16@1+ (0.03125,-273) [-273|1734.97] "deg C" Vector__XXX
   SG_ Aftrtrtmnt1DslPrtcltFltrOtltExhs : 40|5@1+ (1,0) [0|31] "" Vector__XXX
   SG_ Aftrtrtmnt1ExhstGsTmp3PrlmnryFMI : 32|5@1+ (1,0) [0|31] "" Vector__XXX
   SG_ Aftertreatment1ExhaustGasTemp3 : 0|16@1+ (0.03125,-273) [-273|1734.97] "deg C" Vector__XXX

BO_ 2566749182 AT1S: 8 Vector__XXX
   SG_ DslPrtclteFilter1AshLoadPercent : 8|8@1+ (1,0) [0|250] "%" Vector__XXX
   SG_ DslPrtcltFltr1TmSncLstActvRgnrtn : 16|32@1+ (1,0) [0|4.21108e+09] "s" Vector__XXX
   SG_ DslPrtcltFilter1SootLoadPercent : 0|8@1+ (1,0) [0|250] "%" Vector__XXX
   SG_ Aftrtrtmnt1DslPrtcltFltrStLdRgnr : 48|16@1+ (0.0025,0) [0|160.637] "%" Vector__XXX

BO_ 2566748670 AT1TI: 32 Vector__XXX
   SG_ Aftrtrtmnt1TrpNmbrOfActvRgnrtnMn : 224|32@1+ (1,0) [0|4.29497e+09] "counts" Vector__XXX
   SG_ Aftrtrtmnt1TrpNmbrOfActvRgnrtnIn : 192|32@1+ (1,0) [0|4.29497e+09] "counts" Vector__XXX
   SG_ Aftrtrtmnt1TrpNmbrOfPssvRgnrtns : 160|32@1+ (1,0) [0|4.29497e+09] "counts" Vector__XXX
   SG_ Aftrtrtmnt1TrpPssvRgnrationTime : 128|32@1+ (1,0) [0|4.21108e+09] "s" Vector__XXX
   SG_ Aftrtrtmnt1TrpNmbrOfActvRgnrtns : 96|32@1+ (1,0) [0|4.29497e+09] "counts" Vector__XXX
   SG_ Aftertreatment1TripDisabledTime : 64|32@1+ (1,0) [0|4.21108e+09] "s" Vector__XXX
   SG_ Aftrtrtmnt1TrpActvRgnrationTime : 32|32@1+ (1,0) [0|4.21108e+09] "s" Vector__XXX
   SG_ Aftertreatment1TripFuelUsed : 0|32@1+ (0.5,0) [0|2.10554e+09] "L" Vector__XXX

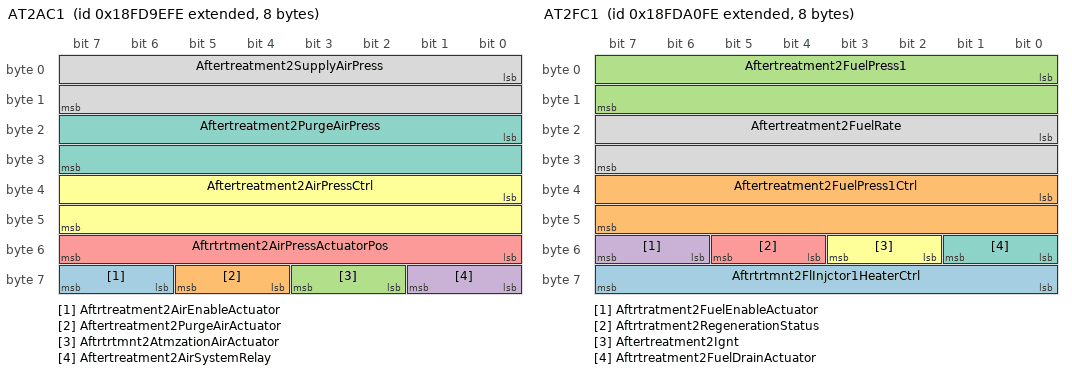
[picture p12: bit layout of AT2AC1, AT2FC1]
BO_ 2566758142 AT2AC1: 8 Vector__XXX
   SG_ Aftrtreatment2AirEnableActuator : 62|2@1+ (1,0) [0|3] "" Vector__XXX
   SG_ Aftertreatment2PurgeAirActuator : 60|2@1+ (1,0) [0|3] "" Vector__XXX
   SG_ Aftrtrtmnt2AtmzationAirActuator : 58|2@1+ (1,0) [0|3] "" Vector__XXX
   SG_ Aftertreatment2AirSystemRelay : 56|2@1+ (1,0) [0|3] "" Vector__XXX
   SG_ Aftrtrtment2AirPressActuatorPos : 48|8@1+ (0.4,0) [0|100] "%" Vector__XXX
   SG_ Aftertreatment2AirPressCtrl : 32|16@1+ (0.0025,0) [0|160.637] "%" Vector__XXX
   SG_ Aftertreatment2PurgeAirPress : 16|16@1+ (0.1,0) [0|6425.5] "kPa" Vector__XXX
   SG_ Aftertreatment2SupplyAirPress : 0|16@1+ (0.1,0) [0|6425.5] "kPa" Vector__XXX

BO_ 2566745342 AT2AC2: 8 Vector__XXX
   SG_ Aftertreatment2SecondAirPress : 48|16@1+ (0.1,0) [0|6425.5] "kPa" Vector__XXX
   SG_ Aftrtreatment2SecondAirMassFlow : 32|16@1+ (0.2,0) [0|12851] "kg/h" Vector__XXX
   SG_ Aftertreatment2SecondAirTemp : 16|16@1+ (0.03125,-273) [-273|1734.97] "deg C" Vector__XXX
   SG_ Aftrtratment2SecondAirDiffPress : 0|16@1+ (0.0078125,-250) [-250|251.99] "kPa" Vector__XXX

BO_ 2566758654 AT2FC1: 8 Vector__XXX
   SG_ Aftrtrtmnt2FlInjctor1HeaterCtrl : 56|8@1+ (0.4,0) [0|100] "%" Vector__XXX
   SG_ Aftertreatment2FuelPress1Ctrl : 32|16@1+ (0.0025,0) [0|160.637] "%" Vector__XXX
   SG_ Aftertreatment2FuelPress1 : 0|16@1+ (0.1,0) [0|6425.5] "kPa" Vector__XXX
   SG_ Aftrtratment2FuelEnableActuator : 54|2@1+ (1,0) [0|3] "" Vector__XXX
   SG_ Aftrtratment2RegenerationStatus : 52|2@1+ (1,0) [0|3] "" Vector__XXX
   SG_ Aftertreatment2Ignt : 50|2@1+ (1,0) [0|3] "" Vector__XXX
   SG_ Aftrtreatment2FuelDrainActuator : 48|2@1+ (1,0) [0|3] "" Vector__XXX
   SG_ Aftertreatment2FuelRate : 16|16@1+ (0.05,0) [0|3212.75] "L/h" Vector__XXX

BO_ 2566753278 AT2GP: 8 Vector__XXX
   SG_ DslPrticulateFilterOutletPress2 : 16|16@1+ (0.1,0) [0|6425.5] "kPa" Vector__XXX
   SG_ DslPrticulateFilterIntakePress2 : 0|16@1+ (0.1,0) [0|6425.5] "kPa" Vector__XXX

BO_ 2566756862 AT2HI: 36 Vector__XXX
   SG_ Aftrtrtmnt2TtlNmbrOfActvRgnrtnMn : 224|32@1+ (1,0) [0|4.29497e+09] "counts" Vector__XXX
   SG_ Aftrtrtmnt2TtlNmbrOfActvRgnrtnIn : 192|32@1+ (1,0) [0|4.29497e+09] "counts" Vector__XXX
   SG_ Aftrtrtmnt2AvrgTmBtwnActvRgnrtns : 256|32@1+ (1,0) [0|4.21108e+09] "s" Vector__XXX
   SG_ Aftrtrtmnt2TtlNmbrOfPssvRgnrtns : 160|32@1+ (1,0) [0|4.29497e+09] "counts" Vector__XXX
   SG_ Aftrtrtmnt2TtlPssvRgnrationTime : 128|32@1+ (1,0) [0|4.21108e+09] "s" Vector__XXX
   SG_ Aftrtrtmnt2TtlNmbrOfActvRgnrtns : 96|32@1+ (1,0) [0|4.29497e+09] "counts" Vector__XXX
   SG_ Aftrtreatment2TotalDisabledTime : 64|32@1+ (1,0) [0|4.21108e+09] "s" Vector__XXX
   SG_ Aftrtrtmnt2TtalRegenerationTime : 32|32@1+ (1,0) [0|4.21108e+09] "s" Vector__XXX
   SG_ Aftertreatment2TotalFuelUsed : 0|32@1+ (0.5,0) [0|2.10554e+09] "L" Vector__XXX

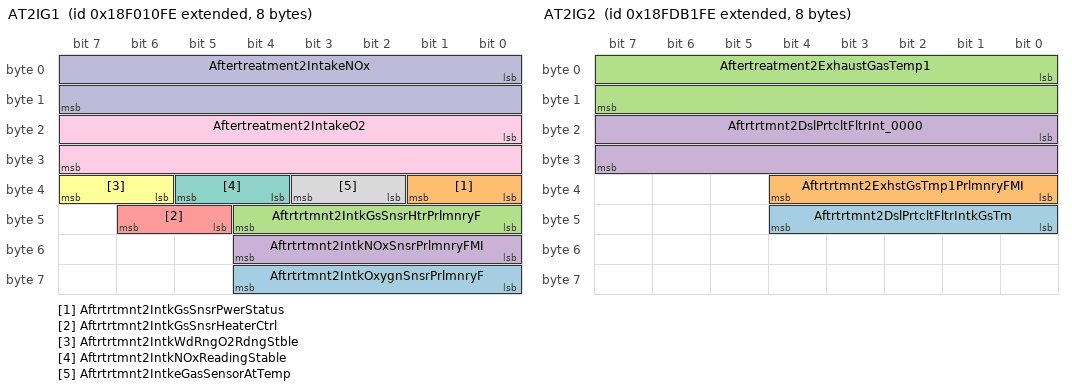
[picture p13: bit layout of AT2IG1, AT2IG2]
BO_ 2565869822 AT2IG1: 8 Vector__XXX
   SG_ Aftrtrtmnt2IntkOxygnSnsrPrlmnryF : 56|5@1+ (1,0) [0|31] "" Vector__XXX
   SG_ Aftrtrtmnt2IntkGsSnsrPwerStatus : 32|2@1+ (1,0) [0|3] "" Vector__XXX
   SG_ Aftrtrtmnt2IntkGsSnsrHtrPrlmnryF : 40|5@1+ (1,0) [0|31] "" Vector__XXX
   SG_ Aftrtrtmnt2IntkNOxSnsrPrlmnryFMI : 48|5@1+ (1,0) [0|31] "" Vector__XXX
   SG_ Aftrtrtmnt2IntkGsSnsrHeaterCtrl : 45|2@1+ (1,0) [0|3] "" Vector__XXX
   SG_ Aftrtrtmnt2IntkWdRngO2RdngStble : 38|2@1+ (1,0) [0|3] "" Vector__XXX
   SG_ Aftrtrtmnt2IntkNOxReadingStable : 36|2@1+ (1,0) [0|3] "" Vector__XXX
   SG_ Aftrtrtmnt2IntkeGasSensorAtTemp : 34|2@1+ (1,0) [0|3] "" Vector__XXX
   SG_ Aftertreatment2IntakeO2 : 16|16@1+ (0.000514,-12) [-12|21] "%" Vector__XXX
   SG_ Aftertreatment2IntakeNOx : 0|16@1+ (0.05,-200) [-200|3012.75] "ppm" Vector__XXX

BO_ 2566763006 AT2IG2: 8 Vector__XXX
   SG_ Aftrtrtmnt2DslPrtcltFltrIntkGsTm : 40|5@1+ (1,0) [0|31] "" Vector__XXX
   SG_ Aftrtrtmnt2ExhstGsTmp1PrlmnryFMI : 32|5@1+ (1,0) [0|31] "" Vector__XXX
   SG_ Aftertreatment2ExhaustGasTemp1 : 0|16@1+ (0.03125,-273) [-273|1734.97] "deg C" Vector__XXX
   SG_ Aftrtrtmnt2DslPrtcltFltrInt_0000 : 16|16@1+ (0.03125,-273) [-273|1734.97] "deg C" Vector__XXX

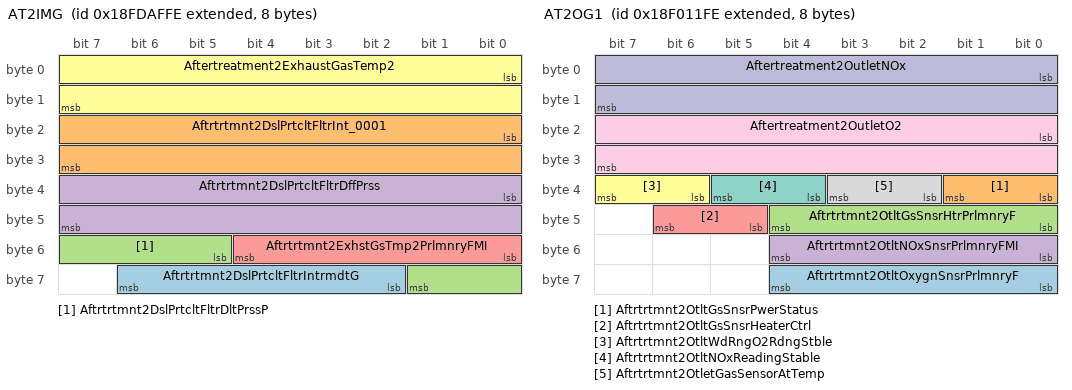
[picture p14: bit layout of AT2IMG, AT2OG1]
BO_ 2566762494 AT2IMG: 8 Vector__XXX
   SG_ Aftrtrtmnt2DslPrtcltFltrIntrmdtG : 58|5@1+ (1,0) [0|31] "" Vector__XXX
   SG_ Aftrtrtmnt2DslPrtcltFltrInt_0001 : 16|16@1+ (0.03125,-273) [-273|1734.97] "deg C" Vector__XXX
   SG_ Aftrtrtmnt2DslPrtcltFltrDltPrssP : 53|5@1+ (1,0) [0|31] "" Vector__XXX
   SG_ Aftrtrtmnt2DslPrtcltFltrDffPrss : 32|16@1+ (0.1,0) [0|6425.5] "kPa" Vector__XXX
   SG_ Aftrtrtmnt2ExhstGsTmp2PrlmnryFMI : 48|5@1+ (1,0) [0|31] "" Vector__XXX
   SG_ Aftertreatment2ExhaustGasTemp2 : 0|16@1+ (0.03125,-273) [-273|1734.97] "deg C" Vector__XXX

BO_ 2565870078 AT2OG1: 8 Vector__XXX
   SG_ Aftrtrtmnt2OtltOxygnSnsrPrlmnryF : 56|5@1+ (1,0) [0|31] "" Vector__XXX
   SG_ Aftrtrtmnt2OtltGsSnsrPwerStatus : 32|2@1+ (1,0) [0|3] "" Vector__XXX
   SG_ Aftrtrtmnt2OtltGsSnsrHtrPrlmnryF : 40|5@1+ (1,0) [0|31] "" Vector__XXX
   SG_ Aftrtrtmnt2OtltNOxSnsrPrlmnryFMI : 48|5@1+ (1,0) [0|31] "" Vector__XXX
   SG_ Aftrtrtmnt2OtltGsSnsrHeaterCtrl : 45|2@1+ (1,0) [0|3] "" Vector__XXX
   SG_ Aftrtrtmnt2OtltWdRngO2RdngStble : 38|2@1+ (1,0) [0|3] "" Vector__XXX
   SG_ Aftrtrtmnt2OtltNOxReadingStable : 36|2@1+ (1,0) [0|3] "" Vector__XXX
   SG_ Aftrtrtmnt2OtletGasSensorAtTemp : 34|2@1+ (1,0) [0|3] "" Vector__XXX
   SG_ Aftertreatment2OutletO2 : 16|16@1+ (0.000514,-12) [-12|21] "%" Vector__XXX
   SG_ Aftertreatment2OutletNOx : 0|16@1+ (0.05,-200) [-200|3012.75] "ppm" Vector__XXX

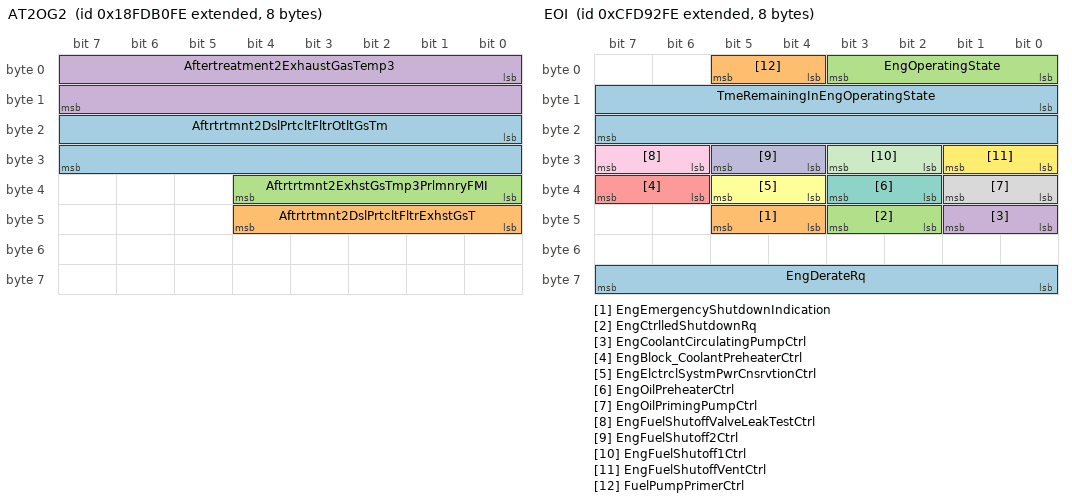
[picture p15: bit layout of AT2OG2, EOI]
BO_ 2566762750 AT2OG2: 8 Vector__XXX
   SG_ Aftrtrtmnt2DslPrtcltFltrOtltGsTm : 16|16@1+ (0.03125,-273) [-273|1734.97] "deg C" Vector__XXX
   SG_ Aftrtrtmnt2DslPrtcltFltrExhstGsT : 40|5@1+ (1,0) [0|31] "" Vector__XXX
   SG_ Aftrtrtmnt2ExhstGsTmp3PrlmnryFMI : 32|5@1+ (1,0) [0|31] "" Vector__XXX
   SG_ Aftertreatment2ExhaustGasTemp3 : 0|16@1+ (0.03125,-273) [-273|1734.97] "deg C" Vector__XXX

BO_ 2566748926 AT2S: 8 Vector__XXX
   SG_ DslPrtclteFilter2AshLoadPercent : 8|8@1+ (1,0) [0|250] "%" Vector__XXX
   SG_ DslPrtcltFltr2TmSncLstActvRgnrtn : 16|32@1+ (1,0) [0|4.21108e+09] "s" Vector__XXX
   SG_ DslPrtcltFilter2SootLoadPercent : 0|8@1+ (1,0) [0|250] "%" Vector__XXX
   SG_ Aftrtrtmnt2DslPrtcltFltrStLdRgnr : 48|16@1+ (0.0025,0) [0|160.637] "%" Vector__XXX

BO_ 2566748414 AT2TI: 32 Vector__XXX
   SG_ Aftrtrtmnt2TrpNmbrOfActvRgnrtnMn : 224|32@1+ (1,0) [0|4.29497e+09] "counts" Vector__XXX
   SG_ Aftrtrtmnt2TrpNmbrOfActvRgnrtnIn : 192|32@1+ (1,0) [0|4.29497e+09] "counts" Vector__XXX
   SG_ Aftrtrtmnt2TrpNmbrOfPssvRgnrtns : 160|32@1+ (1,0) [0|4.29497e+09] "counts" Vector__XXX
   SG_ Aftrtrtmnt2TrpPssvRgnrationTime : 128|32@1+ (1,0) [0|4.21108e+09] "s" Vector__XXX
   SG_ Aftrtrtmnt2TrpNmbrOfActvRgnrtns : 96|32@1+ (1,0) [0|4.29497e+09] "counts" Vector__XXX
   SG_ Aftertreatment2TripDisabledTime : 64|32@1+ (1,0) [0|4.21108e+09] "s" Vector__XXX
   SG_ Aftrtrtmnt2TrpActvRgnrationTime : 32|32@1+ (1,0) [0|4.21108e+09] "s" Vector__XXX
   SG_ Aftertreatment2TripFuelUsed : 0|32@1+ (0.5,0) [0|2.10554e+09] "L" Vector__XXX

BO_ 2365428478 EOI: 8 Vector__XXX
   SG_ EngDerateRq : 56|8@1+ (0.4,0) [0|100] "%" Vector__XXX
   SG_ EngEmergencyShutdownIndication : 44|2@1+ (1,0) [0|3] "" Vector__XXX
   SG_ EngCtrlledShutdownRq : 42|2@1+ (1,0) [0|3] "" Vector__XXX
   SG_ EngCoolantCirculatingPumpCtrl : 40|2@1+ (1,0) [0|3] "" Vector__XXX
   SG_ EngBlock_CoolantPreheaterCtrl : 38|2@1+ (1,0) [0|3] "" Vector__XXX
   SG_ EngElctrclSystmPwrCnsrvtionCtrl : 36|2@1+ (1,0) [0|3] "" Vector__XXX
   SG_ EngOilPreheaterCtrl : 34|2@1+ (1,0) [0|3] "" Vector__XXX
   SG_ EngOilPrimingPumpCtrl : 32|2@1+ (1,0) [0|3] "" Vector__XXX
   SG_ EngFuelShutoffValveLeakTestCtrl : 30|2@1+ (1,0) [0|3] "" Vector__XXX
   SG_ EngFuelShutoff2Ctrl : 28|2@1+ (1,0) [0|3] "" Vector__XXX
   SG_ EngFuelShutoff1Ctrl : 26|2@1+ (1,0) [0|3] "" Vector__XXX
   SG_ EngFuelShutoffVentCtrl : 24|2@1+ (1,0) [0|3] "" Vector__XXX
   SG_ TmeRemainingInEngOperatingState : 8|16@1+ (1,0) [0|64255] "s" Vector__XXX
   SG_ FuelPumpPrimerCtrl : 4|2@1+ (1,0) [0|3] "" Vector__XXX
   SG_ EngOperatingState : 0|4@1+ (1,0) [0|15] "" Vector__XXX

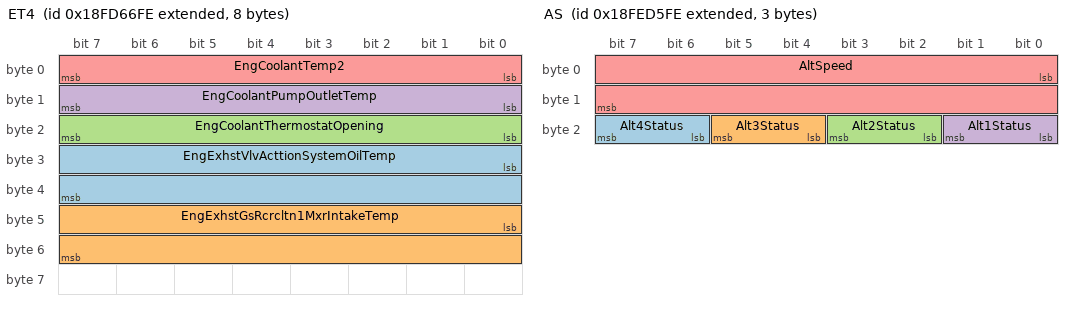
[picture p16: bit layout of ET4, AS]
BO_ 2566743806 ET4: 8 Vector__XXX
   SG_ EngExhstVlvActtionSystemOilTemp : 24|16@1+ (0.03125,-273) [-273|1734.97] "deg C" Vector__XXX
   SG_ EngExhstGsRcrcltn1MxrIntakeTemp : 40|16@1+ (0.03125,-273) [-273|1734.97] "deg C" Vector__XXX
   SG_ EngCoolantThermostatOpening : 16|8@1+ (0.4,0) [0|100] "%" Vector__XXX
   SG_ EngCoolantPumpOutletTemp : 8|8@1+ (1,-40) [-40|210] "deg C" Vector__XXX
   SG_ EngCoolantTemp2 : 0|8@1+ (1,-40) [-40|210] "deg C" Vector__XXX

BO_ 2499635454 GCVW: 8 Vector__XXX
   SG_ NetVehicleWeightChange : 24|24@1+ (2,-1.64495e+07) [-1.64495e+07|1.64495e+07] "kg" Vector__XXX
   SG_ GrossCombinationWeight : 0|24@1+ (2,0) [0|3.28991e+07] "kg" Vector__XXX

BO_ 2550660862 GPV4: 8 Vector__XXX
   SG_ ValveAssemblySupplyPress : 40|16@1+ (5,0) [0|321275] "kPa" Vector__XXX
   SG_ ValveAssemblyLoadSensePress : 24|16@1+ (5,0) [0|321275] "kPa" Vector__XXX
   SG_ ValvePilotPress : 16|8@1+ (16,0) [0|4000] "kPa" Vector__XXX
   SG_ ValveLoadSensePress : 0|16@1+ (5,0) [0|321275] "kPa" Vector__XXX

BO_ 2566805758 ASC4: 8 Vector__XXX
   SG_ BellowPressRearAxleRight : 48|16@1+ (0.1,0) [0|6425.5] "kPa" Vector__XXX
   SG_ BellowPressRearAxleLeft : 32|16@1+ (0.1,0) [0|6425.5] "kPa" Vector__XXX
   SG_ BellowPressFrontAxleRight : 16|16@1+ (0.1,0) [0|6425.5] "kPa" Vector__XXX
   SG_ BellowPressFrontAxleLeft : 0|16@1+ (0.1,0) [0|6425.5] "kPa" Vector__XXX

BO_ 2566806014 ASC3: 8 Vector__XXX
   SG_ RelativeLevelRearAxleRight : 48|16@1+ (0.1,-3200) [-3200|3225.5] "mm" Vector__XXX
   SG_ RelativeLevelRearAxleLeft : 32|16@1+ (0.1,-3200) [-3200|3225.5] "mm" Vector__XXX
   SG_ RelativeLevelFrontAxleRight : 16|16@1+ (0.1,-3200) [-3200|3225.5] "mm" Vector__XXX
   SG_ RelativeLevelFrontAxleLeft : 0|16@1+ (0.1,-3200) [-3200|3225.5] "mm" Vector__XXX

BO_ 2362638078 ASC2: 8 Vector__XXX
   SG_ SpeedDependentLevelCtrlRq : 56|2@1+ (1,0) [0|3] "" Vector__XXX
   SG_ PrhbtAutomaticAirSuspensionCtrl : 58|2@1+ (1,0) [0|3] "" Vector__XXX
   SG_ MemoryLevelRq : 60|4@1+ (1,0) [0|15] "" Vector__XXX
   SG_ AllowLevelCtrlDuringBrakingCmd : 54|2@1+ (1,0) [0|3] "" Vector__XXX
   SG_ ProhibitAirSuspensionCtrl : 52|2@1+ (1,0) [0|3] "" Vector__XXX
   SG_ KneelingCmdRearAxle : 50|2@1+ (1,0) [0|3] "" Vector__XXX
   SG_ KneelingCmdFrontAxle : 48|2@1+ (1,0) [0|3] "" Vector__XXX
   SG_ DamperStiffnessRqLift_TagAxle : 40|8@1+ (0.4,0) [0|100] "%" Vector__XXX
   SG_ DamperStiffnessRqRearAxle : 32|8@1+ (0.4,0) [0|100] "%" Vector__XXX
   SG_ DamperStiffnessRqFrontAxle : 24|8@1+ (0.4,0) [0|100] "%" Vector__XXX
   SG_ LevelCtrlModeRq : 16|4@1+ (1,0) [0|15] "" Vector__XXX
   SG_ NominalLevelRqRearAxle : 12|4@1+ (1,0) [0|15] "" Vector__XXX
   SG_ NominalLevelRqFrontAxle : 8|4@1+ (1,0) [0|15] "" Vector__XXX
   SG_ KneelingCtrlModeRq : 6|2@1+ (1,0) [0|3] "" Vector__XXX
   SG_ KneelingRqRightSide : 4|2@1+ (1,0) [0|3] "" Vector__XXX
   SG_ KneelingRqLeftSide : 2|2@1+ (1,0) [0|3] "" Vector__XXX
   SG_ AutomaticTractionHelp : 0|2@1+ (1,0) [0|3] "" Vector__XXX
   SG_ LiftAxle2PosCmd : 22|2@1+ (1,0) [0|3] "" Vector__XXX
   SG_ LiftAxle1PosCmd : 20|2@1+ (1,0) [0|3] "" Vector__XXX

BO_ 2365479678 ASC1: 8 Vector__XXX
   SG_ SpeedDependantLevelCtrlStatus : 54|2@1+ (1,0) [0|3] "" Vector__XXX
   SG_ MemoryLevel : 60|4@1+ (1,0) [0|15] "" Vector__XXX
   SG_ AllwLvelCtrlDuringBrakingStatus : 52|2@1+ (1,0) [0|3] "" Vector__XXX
   SG_ SspensionCtrlRefusalInformation : 56|4@1+ (1,0) [0|15] "" Vector__XXX
   SG_ SuspensionRemoteCtrl2 : 50|2@1+ (1,0) [0|3] "" Vector__XXX
   SG_ SuspensionRemoteCtrl1 : 48|2@1+ (1,0) [0|3] "" Vector__XXX
   SG_ RearAxleInBumperRange : 42|2@1+ (1,0) [0|3] "" Vector__XXX
   SG_ FrontAxleInBumperRange : 40|2@1+ (1,0) [0|3] "" Vector__XXX
   SG_ DoorRelease : 36|2@1+ (1,0) [0|3] "" Vector__XXX
   SG_ VehicleMotionInhibit : 34|2@1+ (1,0) [0|3] "" Vector__XXX
   SG_ SecurityDevice : 32|2@1+ (1,0) [0|3] "" Vector__XXX
   SG_ LevelCtrlMode : 28|4@1+ (1,0) [0|15] "" Vector__XXX
   SG_ KneelingInformation : 24|4@1+ (1,0) [0|15] "" Vector__XXX
   SG_ LiftingCtrlModeRearAxle : 22|2@1+ (1,0) [0|3] "" Vector__XXX
   SG_ LiftingCtrlModeFrontAxle : 20|2@1+ (1,0) [0|3] "" Vector__XXX
   SG_ LoweringCtrlModeRearAxle : 18|2@1+ (1,0) [0|3] "" Vector__XXX
   SG_ LoweringCtrlModeFrontAxle : 16|2@1+ (1,0) [0|3] "" Vector__XXX
   SG_ AboveNominalLevelRearAxle : 14|2@1+ (1,0) [0|3] "" Vector__XXX
   SG_ AboveNominalLevelFrontAxle : 12|2@1+ (1,0) [0|3] "" Vector__XXX
   SG_ BelowNominalLevelRearAxle : 10|2@1+ (1,0) [0|3] "" Vector__XXX
   SG_ BelowNominalLevelFrontAxle : 8|2@1+ (1,0) [0|3] "" Vector__XXX
   SG_ NominalLevelRearAxle : 4|4@1+ (1,0) [0|15] "" Vector__XXX
   SG_ NominalLevelFrontAxle : 0|4@1+ (1,0) [0|15] "" Vector__XXX
   SG_ LiftAxle2Pos : 46|2@1+ (1,0) [0|3] "" Vector__XXX
   SG_ LiftAxle1Pos : 38|2@1+ (1,0) [0|3] "" Vector__XXX

BO_ 2566837758 AS: 3 Vector__XXX
   SG_ Alt4Status : 22|2@1+ (1,0) [0|3] "" Vector__XXX
   SG_ Alt3Status : 20|2@1+ (1,0) [0|3] "" Vector__XXX
   SG_ Alt2Status : 18|2@1+ (1,0) [0|3] "" Vector__XXX
   SG_ Alt1Status : 16|2@1+ (1,0) [0|3] "" Vector__XXX
   SG_ AltSpeed : 0|16@1+ (0.5,0) [0|32127.5] "rpm" Vector__XXX

BO_ 2633922558 AP: 8 Vector__XXX
   SG_ AuxAbsPressReading : 32|16@1+ (0.5,0) [0|32127.5] "kPa" Vector__XXX
   SG_ AuxGagePressReading1 : 16|16@1+ (0.5,0) [0|32127.5] "kPa" Vector__XXX
   SG_ AuxVacuumPressReading : 0|16@1+ (0.5,0) [0|32127.5] "kPa" Vector__XXX

BO_ 2566775038 AMB2: 8 Vector__XXX
   SG_ SpecificHumidity : 16|16@1+ (0.01,0) [0|642.55] "g/kg" Vector__XXX
   SG_ SolarSensorMax : 8|8@1+ (0.4,0) [0|100] "mW/cm/cm" Vector__XXX
   SG_ SolarIntensityPercent : 0|8@1+ (0.4,0) [0|100] "%" Vector__XXX

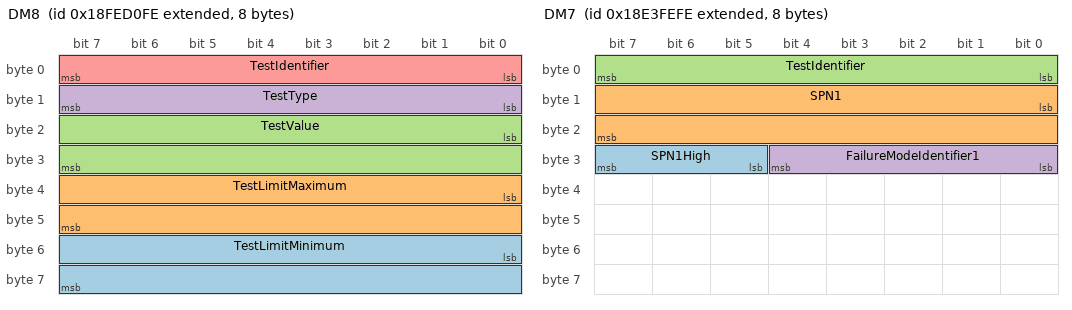
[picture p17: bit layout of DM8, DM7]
BO_ 2566836478 DM8: 8 Vector__XXX
   SG_ TestLimitMinimum : 48|16@1+ (1,0) [0|64255] "" Vector__XXX
   SG_ TestLimitMaximum : 32|16@1+ (1,0) [0|64255] "" Vector__XXX
   SG_ TestValue : 16|16@1+ (1,0) [0|64255] "" Vector__XXX
   SG_ TestType : 8|8@1+ (1,0) [1|64] "" Vector__XXX
   SG_ TestIdentifier : 0|8@1+ (1,0) [1|64] "" Vector__XXX

BO_ 2565078782 DM7: 8 Vector__XXX
   SG_ SPN1High : 29|3@1+ (1,0) [0|7] "" Vector__XXX
   SG_ SPN1 : 8|16@1+ (1,0) [0|65536] "" Vector__XXX
   SG_ TestIdentifier : 0|8@1+ (1,0) [1|64] "" Vector__XXX
   SG_ FailureModeIdentifier1 : 24|5@1+ (1,0) [0|0] "" Vector__XXX

BO_ 2566836222 DM6: 22 Vector__XXX
   SG_ FlashRedStopLamp : 12|2@1+ (1,0) [0|3] "" Vector__XXX
   SG_ FlashProtectLamp : 8|2@1+ (1,0) [0|3] "" Vector__XXX
   SG_ FlashMalfuncIndicatorLamp : 14|2@1+ (1,0) [0|3] "" Vector__XXX
   SG_ FlashAmberWarningLamp : 10|2@1+ (1,0) [0|3] "" Vector__XXX
   SG_ MalfunctionIndicatorLampStatus : 6|2@1+ (1,0) [0|3] "" Vector__XXX
   SG_ RedStopLampState : 4|2@1+ (1,0) [0|3] "" Vector__XXX
   SG_ AmberWarningLampStatus : 2|2@1+ (1,0) [0|3] "" Vector__XXX
   SG_ ProtectLampStatus : 0|2@1+ (1,0) [0|3] "" Vector__XXX
   SG_ DTC5 : 144|32@1+ (1,0) [0|4.29497e+09] "" Vector__XXX
   SG_ DTC4 : 112|32@1+ (1,0) [0|4.29497e+09] "" Vector__XXX
   SG_ DTC3 : 80|32@1+ (1,0) [0|4.29497e+09] "" Vector__XXX
   SG_ DTC2 : 48|32@1+ (1,0) [0|4.29497e+09] "" Vector__XXX
   SG_ DTC1 : 16|32@1+ (1,0) [0|4.29497e+09] "" Vector__XXX

BO_ 2566835966 DM5: 8 Vector__XXX
   SG_ BoostPressureControlSystemStatus : 57|1@1- (1,0) [0|0] "" Vector__XXX
   SG_ DieselParticulateFilterStatus : 58|1@1- (1,0) [0|0] "" Vector__XXX
   SG_ NOxConvertingCatalystAdsorberSta : 59|1@1- (1,0) [0|0] "" Vector__XXX
   SG_ NMHCConvertingCatalystStatus : 60|1@1- (1,0) [0|0] "" Vector__XXX
   SG_ BoostPressureControlSystemSuppor : 41|1@1- (1,0) [0|0] "" Vector__XXX
   SG_ DieselParticulateFilterSupport : 42|1@1- (1,0) [0|0] "" Vector__XXX
   SG_ NOxConvertingCatalystAdsorberSup : 43|1@1- (1,0) [0|0] "" Vector__XXX
   SG_ NMHCConvertingCatalystSupport : 44|1@1- (1,0) [0|0] "" Vector__XXX
   SG_ MisfireMonitoringSupport : 24|1@1+ (1,0) [0|0] "" Vector__XXX
   SG_ OBDCompliance : 16|8@1+ (1,0) [0|240] "" Vector__XXX
   SG_ PreviouslyActiveTroubleCodes : 8|8@1+ (1,0) [0|240] "" Vector__XXX
   SG_ ActiveTroubleCodes : 0|8@1+ (1,0) [0|240] "" Vector__XXX
   SG_ SecondAirSystemMonStatus : 51|1@1+ (1,0) [0|1] "" Vector__XXX
   SG_ EvaporativeSystemMonStatus : 50|1@1+ (1,0) [0|1] "" Vector__XXX
   SG_ ACSystemRefrigerantMonStatus : 52|1@1+ (1,0) [0|1] "" Vector__XXX
   SG_ OxygenSensorHeaterMonStatus : 54|1@1+ (1,0) [0|1] "" Vector__XXX
   SG_ OxygenSensorMonStatus : 53|1@1+ (1,0) [0|1] "" Vector__XXX
   SG_ EGRSystemMonitoringStatus : 55|1@1+ (1,0) [0|1] "" Vector__XXX
   SG_ CatalystMonStatus : 48|1@1+ (1,0) [0|1] "" Vector__XXX
   SG_ ColdStartAidSystemMonStatus : 56|1@1+ (1,0) [0|1] "" Vector__XXX
   SG_ HeatedCatalystMonStatus : 49|1@1+ (1,0) [0|0] "" Vector__XXX
   SG_ CatalystMonSupp : 32|1@1+ (1,0) [0|1] "" Vector__XXX
   SG_ ColdStartAidSystemMonSupp : 40|1@1+ (1,0) [0|1] "" Vector__XXX
   SG_ HeatedCatalystMonSupp : 33|1@1+ (1,0) [0|0] "" Vector__XXX
   SG_ EvaporativeSystemMonSupp : 34|1@1+ (1,0) [0|1] "" Vector__XXX
   SG_ SecondAirSystemMonSupp : 35|1@1+ (1,0) [0|1] "" Vector__XXX
   SG_ ACSystemRefrigerantMonSupp : 36|1@1+ (1,0) [0|1] "" Vector__XXX
   SG_ OxygenSensorMonSupp : 37|1@1+ (1,0) [0|1] "" Vector__XXX
   SG_ OxygenSensorHeaterMonSupp : 38|1@1+ (1,0) [0|1] "" Vector__XXX
   SG_ EGRSystemMonitoringSupp : 39|1@1+ (1,0) [0|1] "" Vector__XXX
   SG_ MisfireMonitoringStatus : 28|1@1+ (1,0) [0|0] "" Vector__XXX
   SG_ ComprehensiveCompMonStatus : 30|1@1+ (1,0) [0|1] "" Vector__XXX
   SG_ FuelSystemMonitoringStatus : 29|1@1+ (1,0) [0|1] "" Vector__XXX
   SG_ ComprehensiveComponentMonSupp : 26|1@1+ (1,0) [0|0] "" Vector__XXX
   SG_ FuelSystemMonitoringSupport : 25|1@1+ (1,0) [0|1] "" Vector__XXX

BO_ 2566835710 DM4: 13 Vector__XXX
   SG_ EngIntakeManifold1Press : 48|8@1+ (2,0) [0|500] "kPa" Vector__XXX
   SG_ FreezeFrameLength : 0|8@1+ (1,0) [0|255] "Byte" Vector__XXX
   SG_ EngSpeed : 56|16@1+ (0.125,0) [0|8031.88] "rpm" Vector__XXX
   SG_ EngTorqueMode : 40|4@1+ (1,0) [0|15] "" Vector__XXX
   SG_ WheelBasedVehicleSpeed : 88|16@1+ (0.00390625,0) [0|250.996] "km/h" Vector__XXX
   SG_ EngPercentLoadAtCurrentSpeed : 72|8@1+ (1,0) [0|250] "%" Vector__XXX
   SG_ EngineCoolantTemperature : 80|8@1+ (1,-40) [-40|210] "deg C" Vector__XXX
   SG_ DTC1 : 8|32@1+ (1,0) [0|4.29497e+09] "" Vector__XXX

BO_ 2566835454 DM3: 0 Vector__XXX

BO_ 2566764542 DM25: 13 Vector__XXX
   SG_ ExpandedFreezeFrameLength : 0|8@1+ (1,0) [0|255] "Byte" Vector__XXX
   SG_ DTC1 : 8|32@1+ (1,0) [0|4.29497e+09] "" Vector__XXX

BO_ 2566764286 DM24: 12 Vector__XXX
   SG_ SPNSupported1High : 21|3@1+ (1,0) [0|7] "" Vector__XXX
   SG_ SPNSupportTypeSTR3 : 82|1@1+ (1,0) [0|1] "" Vector__XXX
   SG_ SPNSupportTypeSTR2 : 81|1@1+ (1,0) [0|1] "" Vector__XXX
   SG_ SPNSupportTypeEFF3 : 80|1@1+ (1,0) [0|1] "" Vector__XXX
   SG_ SPNSupportTypeEFF2 : 48|1@1+ (1,0) [0|1] "" Vector__XXX
   SG_ SPNSupportTypeDS3 : 50|1@1+ (1,0) [0|1] "" Vector__XXX
   SG_ SPNSupportTypeDS2 : 49|1@1+ (1,0) [0|1] "" Vector__XXX
   SG_ SPNSupported3High : 85|3@1+ (1,0) [0|7] "" Vector__XXX
   SG_ SPNSupported2High : 53|3@1+ (1,0) [0|7] "" Vector__XXX
   SG_ SPNSupported3 : 64|16@1+ (1,0) [0|65535] "" Vector__XXX
   SG_ SPNSupported2 : 32|16@1+ (1,0) [0|65535] "" Vector__XXX
   SG_ SPNDataLength3 : 88|8@1+ (1,0) [0|240] "" Vector__XXX
   SG_ SPNSupportTypeSTR1 : 18|1@1+ (1,0) [0|1] "" Vector__XXX
   SG_ SPNSupportTypeDS1 : 17|1@1+ (1,0) [0|1] "" Vector__XXX
   SG_ SPNSupportTypeEFF1 : 16|1@1+ (1,0) [0|1] "" Vector__XXX
   SG_ SPNDataLength2 : 56|8@1+ (1,0) [0|240] "" Vector__XXX
   SG_ SPNDataLength1 : 24|8@1+ (1,0) [0|240] "" Vector__XXX
   SG_ SPNSupported1 : 0|16@1+ (1,0) [0|65535] "" Vector__XXX

BO_ 2566764030 DM23: 22 Vector__XXX
   SG_ FlashRedStopLamp : 12|2@1+ (1,0) [0|3] "" Vector__XXX
   SG_ FlashProtectLamp : 8|2@1+ (1,0) [0|3] "" Vector__XXX
   SG_ FlashMalfuncIndicatorLamp : 14|2@1+ (1,0) [0|3] "" Vector__XXX
   SG_ FlashAmberWarningLamp : 10|2@1+ (1,0) [0|3] "" Vector__XXX
   SG_ MalfunctionIndicatorLampStatus : 6|2@1+ (1,0) [0|3] "" Vector__XXX
   SG_ RedStopLampState : 4|2@1+ (1,0) [0|3] "" Vector__XXX
   SG_ AmberWarningLampStatus : 2|2@1+ (1,0) [0|3] "" Vector__XXX
   SG_ ProtectLampStatus : 0|2@1+ (1,0) [0|3] "" Vector__XXX
   SG_ DTC5 : 144|32@1+ (1,0) [0|4.29497e+09] "" Vector__XXX
   SG_ DTC4 : 112|32@1+ (1,0) [0|4.29497e+09] "" Vector__XXX
   SG_ DTC3 : 80|32@1+ (1,0) [0|4.29497e+09] "" Vector__XXX
   SG_ DTC2 : 48|32@1+ (1,0) [0|4.29497e+09] "" Vector__XXX
   SG_ DTC1 : 16|32@1+ (1,0) [0|4.29497e+09] "" Vector__XXX

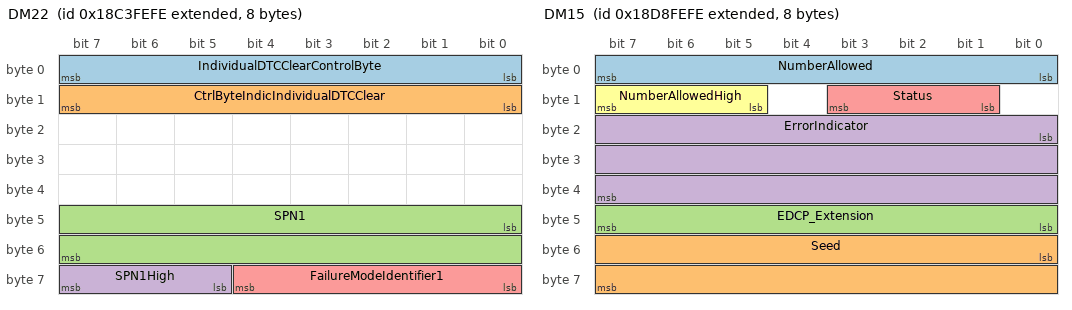
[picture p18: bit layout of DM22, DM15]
BO_ 2562981630 DM22: 8 Vector__XXX
   SG_ IndividualDTCClearControlByte : 0|8@1+ (1,0) [0|255] "" Vector__XXX
   SG_ CtrlByteIndicIndividualDTCClear : 8|8@1+ (1,0) [0|255] "" Vector__XXX
   SG_ SPN1 : 40|16@1+ (1,0) [0|65536] "" Vector__XXX
   SG_ SPN1High : 61|3@1+ (1,0) [0|7] "" Vector__XXX
   SG_ FailureModeIdentifier1 : 56|5@1+ (1,0) [0|0] "" Vector__XXX

BO_ 2562850558 DM21: 8 Vector__XXX
   SG_ TimeSinceDTCsCleared : 48|16@1+ (1,0) [0|64255] "mins" Vector__XXX
   SG_ MinutesRunByEngineMILActivated : 32|16@1+ (1,0) [0|64255] "mins" Vector__XXX
   SG_ DistanceSinceDTCsCleared : 16|16@1+ (1,0) [0|64255] "km" Vector__XXX
   SG_ DistanceWhileMILisActivated : 0|16@1+ (1,0) [0|64255] "km" Vector__XXX

BO_ 2562916094 DM20: 11 Vector__XXX
   SG_ ApplSysMonitorDenominator : 72|16@1+ (1,0) [0|65535] "" Vector__XXX
   SG_ ApplSysMonitorNumerator : 56|16@1+ (1,0) [0|65535] "" Vector__XXX
   SG_ SPNofApplSysMonitor : 32|24@1+ (1,0) [0|524287] "" Vector__XXX
   SG_ OBDMonitoringCondEncountered : 16|16@1+ (1,0) [0|65535] "" Vector__XXX
   SG_ IgnitionCycleCounter : 0|16@1+ (1,0) [0|65535] "" Vector__XXX

BO_ 2566835198 DM2: 22 Vector__XXX
   SG_ MalfunctionIndicatorLampStatus : 6|2@1+ (1,0) [0|3] "" Vector__XXX
   SG_ RedStopLampState : 4|2@1+ (1,0) [0|3] "" Vector__XXX
   SG_ AmberWarningLampStatus : 2|2@1+ (1,0) [0|3] "" Vector__XXX
   SG_ ProtectLampStatus : 0|2@1+ (1,0) [0|3] "" Vector__XXX
   SG_ FlashRedStopLamp : 12|2@1+ (1,0) [0|3] "" Vector__XXX
   SG_ FlashProtectLamp : 8|2@1+ (1,0) [0|3] "" Vector__XXX
   SG_ FlashMalfuncIndicatorLamp : 14|2@1+ (1,0) [0|3] "" Vector__XXX
   SG_ FlashAmberWarningLamp : 10|2@1+ (1,0) [0|3] "" Vector__XXX
   SG_ DTC5 : 144|32@1+ (1,0) [0|4.29497e+09] "" Vector__XXX
   SG_ DTC4 : 112|32@1+ (1,0) [0|4.29497e+09] "" Vector__XXX
   SG_ DTC3 : 80|32@1+ (1,0) [0|4.29497e+09] "" Vector__XXX
   SG_ DTC2 : 48|32@1+ (1,0) [0|4.29497e+09] "" Vector__XXX
   SG_ DTC1 : 16|32@1+ (1,0) [0|4.29497e+09] "" Vector__XXX

BO_ 2564030206 DM19: 20 Vector__XXX
   SG_ CalibrationID4 : 128|32@1+ (1,0) [0|4.29497e+09] "" Vector__XXX
   SG_ CalibrationID3 : 96|32@1+ (1,0) [0|4.29497e+09] "" Vector__XXX
   SG_ CalibrationID2 : 64|32@1+ (1,0) [0|4.29497e+09] "" Vector__XXX
   SG_ CalibrationID1 : 32|32@1+ (1,0) [0|4.29497e+09] "" Vector__XXX
   SG_ CalibrationVerificationNumber : 0|32@1+ (1,0) [0|4.29497e+09] "" Vector__XXX

BO_ 2564226814 DM17: 1 Vector__XXX
   SG_ BootLoadData : 0|8@1- (1,0) [0|0] "" Vector__XXX

BO_ 2564292350 DM16: 2 Vector__XXX
   SG_ RawBinaryData : 8|8@1- (1,0) [0|0] "" Vector__XXX
   SG_ NumberOfOccurance : 0|8@1+ (1,0) [0|0] "" Vector__XXX

BO_ 2564357886 DM15: 8 Vector__XXX
   SG_ NumberAllowed : 0|8@1+ (1,0) [0|2047] "" Vector__XXX
   SG_ Seed : 48|16@1+ (1,0) [0|65535] "" Vector__XXX
   SG_ EDCP_Extension : 40|8@1+ (1,0) [0|255] "" Vector__XXX
   SG_ ErrorIndicator : 16|24@1+ (1,0) [0|1.67772e+07] "" Vector__XXX
   SG_ Status : 9|3@1+ (1,0) [0|7] "" Vector__XXX
   SG_ NumberAllowedHigh : 13|3@1+ (1,0) [0|7] "" Vector__XXX

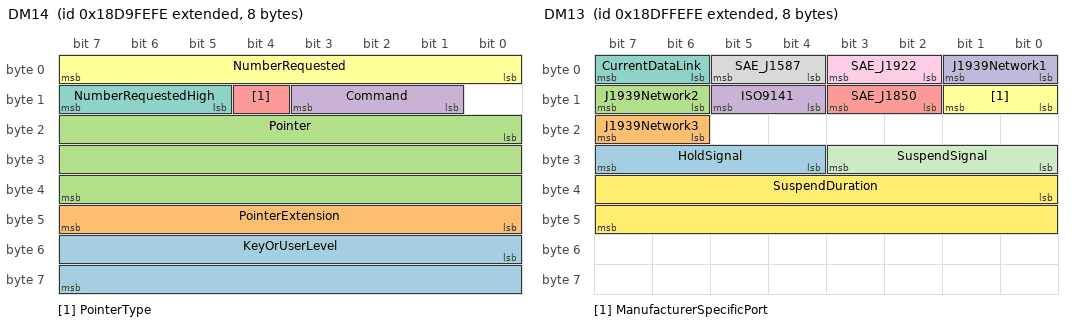
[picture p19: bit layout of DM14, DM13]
BO_ 2564423422 DM14: 8 Vector__XXX
   SG_ KeyOrUserLevel : 48|16@1+ (1,0) [0|65535] "" Vector__XXX
   SG_ PointerExtension : 40|8@1+ (1,0) [0|255] "" Vector__XXX
   SG_ Pointer : 16|24@1+ (1,0) [0|1.67772e+07] "" Vector__XXX
   SG_ Command : 9|3@1+ (1,0) [0|7] "" Vector__XXX
   SG_ PointerType : 12|1@1+ (1,0) [0|1] "" Vector__XXX
   SG_ NumberRequested : 0|8@1+ (1,0) [0|2047] "" Vector__XXX
   SG_ NumberRequestedHigh : 13|3@1+ (1,0) [0|7] "" Vector__XXX

BO_ 2564816638 DM13: 8 Vector__XXX
   SG_ HoldSignal : 28|4@1+ (1,0) [0|15] "" Vector__XXX
   SG_ J1939Network3 : 22|2@1+ (1,0) [0|3] "" Vector__XXX
   SG_ J1939Network2 : 14|2@1+ (1,0) [0|3] "" Vector__XXX
   SG_ ISO9141 : 12|2@1+ (1,0) [0|3] "" Vector__XXX
   SG_ SAE_J1850 : 10|2@1+ (1,0) [0|3] "" Vector__XXX
   SG_ ManufacturerSpecificPort : 8|2@1+ (1,0) [0|3] "" Vector__XXX
   SG_ CurrentDataLink : 6|2@1+ (1,0) [0|3] "" Vector__XXX
   SG_ SAE_J1587 : 4|2@1+ (1,0) [0|3] "" Vector__XXX
   SG_ SAE_J1922 : 2|2@1+ (1,0) [0|3] "" Vector__XXX
   SG_ J1939Network1 : 0|2@1+ (1,0) [0|3] "" Vector__XXX
   SG_ SuspendSignal : 24|4@1+ (1,0) [0|15] "" Vector__XXX
   SG_ SuspendDuration : 32|16@1+ (1,0) [0|64255] "sec" Vector__XXX

BO_ 2566837502 DM12: 22 Vector__XXX
   SG_ FlashRedStopLamp : 12|2@1+ (1,0) [0|3] "" Vector__XXX
   SG_ FlashProtectLamp : 8|2@1+ (1,0) [0|3] "" Vector__XXX
   SG_ MalfunctionIndicatorLampStatus : 6|2@1+ (1,0) [0|3] "" Vector__XXX
   SG_ RedStopLampState : 4|2@1+ (1,0) [0|3] "" Vector__XXX
   SG_ AmberWarningLampStatus : 2|2@1+ (1,0) [0|3] "" Vector__XXX
   SG_ ProtectLampStatus : 0|2@1+ (1,0) [0|3] "" Vector__XXX
   SG_ FlashMalfuncIndicatorLamp : 14|2@1+ (1,0) [0|3] "" Vector__XXX
   SG_ FlashAmberWarningLamp : 10|2@1+ (1,0) [0|3] "" Vector__XXX
   SG_ DTC5 : 144|32@1+ (1,0) [0|4.29497e+09] "" Vector__XXX
   SG_ DTC4 : 112|32@1+ (1,0) [0|4.29497e+09] "" Vector__XXX
   SG_ DTC3 : 80|32@1+ (1,0) [0|4.29497e+09] "" Vector__XXX
   SG_ DTC2 : 48|32@1+ (1,0) [0|4.29497e+09] "" Vector__XXX
   SG_ DTC1 : 16|32@1+ (1,0) [0|4.29497e+09] "" Vector__XXX

BO_ 2566837246 DM11: 0 Vector__XXX

BO_ 2566836990 DM10: 8 Vector__XXX
   SG_ TestIdentifierSupported : 0|64@1+ (1,0) [1|1.84467e+19] "" Vector__XXX

BO_ 2566834942 DM1: 22 Vector__XXX
   SG_ FlashRedStopLamp : 12|2@1+ (1,0) [0|3] "" Vector__XXX
   SG_ FlashProtectLamp : 8|2@1+ (1,0) [0|3] "" Vector__XXX
   SG_ FlashMalfuncIndicatorLamp : 14|2@1+ (1,0) [0|3] "" Vector__XXX
   SG_ FlashAmberWarningLamp : 10|2@1+ (1,0) [0|3] "" Vector__XXX
   SG_ MalfunctionIndicatorLampStatus : 6|2@1+ (1,0) [0|3] "" Vector__XXX
   SG_ AmberWarningLampStatus : 2|2@1+ (1,0) [0|3] "" Vector__XXX
   SG_ RedStopLampState : 4|2@1+ (1,0) [0|3] "" Vector__XXX
   SG_ ProtectLampStatus : 0|2@1+ (1,0) [0|3] "" Vector__XXX
   SG_ DTC5 : 144|32@1+ (1,0) [0|4.29497e+09] "" Vector__XXX
   SG_ DTC4 : 112|32@1+ (1,0) [0|4.29497e+09] "" Vector__XXX
   SG_ DTC3 : 80|32@1+ (1,0) [0|4.29497e+09] "" Vector__XXX
   SG_ DTC2 : 48|32@1+ (1,0) [0|4.29497e+09] "" Vector__XXX
   SG_ DTC1 : 16|32@1+ (1,0) [0|4.29497e+09] "" Vector__XXX

BO_ 2566780926 UTACR: 8 Vector__XXX
   SG_ UtlityOverallPowerFactorLagging : 48|2@1+ (1,0) [0|3] "" Vector__XXX
   SG_ UtilityOverallPowerFactor : 32|16@1+ (1,-1) [-1|2.92181] "" Vector__XXX
   SG_ UtilityTotalReactivePower : 0|32@1+ (1,-2e+09) [-2e+09|2.21108e+09] "VAr" Vector__XXX

BO_ 2566781182 UTACP: 8 Vector__XXX
   SG_ UtilityTotalApparentPower : 32|32@1+ (1,-2e+09) [-2e+09|2.21108e+09] "VA" Vector__XXX
   SG_ UtilityTotalRealPower : 0|32@1+ (1,-2e+09) [-2e+09|2.21108e+09] "W" Vector__XXX

BO_ 2566778366 UTACE: 8 Vector__XXX
   SG_ UtilityTotalKWHoursImport : 32|32@1+ (1,0) [0|4.21108e+09] "kWh" Vector__XXX
   SG_ UtilityTotalKWHoursExport : 0|32@1+ (1,0) [0|4.21108e+09] "kWh" Vector__XXX

BO_ 2566778622 UPCACR: 8 Vector__XXX
   SG_ UtilityPhaseCPowerFactorLagging : 48|2@1+ (1,0) [0|3] "" Vector__XXX
   SG_ UtilityPhaseCPowerFactor : 32|16@1+ (1,-1) [-1|2.92181] "" Vector__XXX
   SG_ UtilityPhaseCReactivePower : 0|32@1+ (1,-2e+09) [-2e+09|2.21108e+09] "VAr" Vector__XXX

BO_ 2566778878 UPCACP: 8 Vector__XXX
   SG_ UtilityPhaseCApparentPower : 32|32@1+ (1,-2e+09) [-2e+09|2.21108e+09] "VA" Vector__XXX
   SG_ UtilityPhaseCRealPower : 0|32@1+ (1,-2e+09) [-2e+09|2.21108e+09] "W" Vector__XXX

BO_ 2566779134 UPCAC: 8 Vector__XXX
   SG_ UtilityPhaseCACRMSCurrent : 48|16@1+ (1,0) [0|64255] "A" Vector__XXX
   SG_ UtilityPhaseCACFrequency : 32|16@1+ (1,0) [0|501.992] "Hz" Vector__XXX
   SG_ UtltyPhsCLneNeutralACRMSVoltage : 16|16@1+ (1,0) [0|64255] "V" Vector__XXX
   SG_ UtltyPhseCALineLineACRMSVoltage : 0|16@1+ (1,0) [0|64255] "V" Vector__XXX

BO_ 2566779390 UPBACR: 8 Vector__XXX
   SG_ UtilityPhaseBPowerFactorLagging : 48|2@1+ (1,0) [0|3] "" Vector__XXX
   SG_ UtilityPhaseBPowerFactor : 32|16@1+ (1,-1) [-1|2.92181] "" Vector__XXX
   SG_ UtilityPhaseBReactivePower : 0|32@1+ (1,-2e+09) [-2e+09|2.21108e+09] "VAr" Vector__XXX

BO_ 2566779646 UPBACP: 8 Vector__XXX
   SG_ UtilityPhaseBApparentPower : 32|32@1+ (1,-2e+09) [-2e+09|2.21108e+09] "VA" Vector__XXX
   SG_ UtilityPhaseBRealPower : 0|32@1+ (1,-2e+09) [-2e+09|2.21108e+09] "W" Vector__XXX

BO_ 2566779902 UPBAC: 8 Vector__XXX
   SG_ UtilityPhaseBACRMSCurrent : 48|16@1+ (1,0) [0|64255] "A" Vector__XXX
   SG_ UtilityPhaseBACFrequency : 32|16@1+ (1,0) [0|501.992] "Hz" Vector__XXX
   SG_ UtltyPhsBLneNeutralACRMSVoltage : 16|16@1+ (1,0) [0|64255] "V" Vector__XXX
   SG_ UtltyPhseBCLineLineACRMSVoltage : 0|16@1+ (1,0) [0|64255] "V" Vector__XXX

BO_ 2566780158 UPACCR: 8 Vector__XXX
   SG_ UtilityPhaseAPowerFactorLagging : 48|2@1+ (1,0) [0|3] "" Vector__XXX
   SG_ UtilityPhaseAPowerFactor : 32|16@1+ (1,-1) [-1|2.92181] "" Vector__XXX
   SG_ UtilityPhaseAReactivePower : 0|32@1+ (1,-2e+09) [-2e+09|2.21108e+09] "VAr" Vector__XXX

BO_ 2566780414 UPAACP: 8 Vector__XXX
   SG_ UtilityPhaseAApparentPower : 32|32@1+ (1,-2e+09) [-2e+09|2.21108e+09] "VA" Vector__XXX
   SG_ UtilityPhaseARealPower : 0|32@1+ (1,-2e+09) [-2e+09|2.21108e+09] "W" Vector__XXX

BO_ 2566780670 UPAAC: 8 Vector__XXX
   SG_ UtilityPhaseAACRMSCurrent : 48|16@1+ (1,0) [0|64255] "A" Vector__XXX
   SG_ UtilityPhaseAACFrequency : 32|16@1+ (1,0) [0|501.992] "Hz" Vector__XXX
   SG_ UtltyPhsALneNeutralACRMSVoltage : 16|16@1+ (1,0) [0|64255] "V" Vector__XXX
   SG_ UtltyPhseABLineLineACRMSVoltage : 0|16@1+ (1,0) [0|64255] "V" Vector__XXX

BO_ 2566781438 UAAC: 8 Vector__XXX
   SG_ UtilityAverageACRMSCurrent : 48|16@1+ (1,0) [0|64255] "A" Vector__XXX
   SG_ UtilityAverageACFrequency : 32|16@1+ (1,0) [0|501.992] "Hz" Vector__XXX
   SG_ UtltyAvrgLneNeutralACRMSVoltage : 16|16@1+ (1,0) [0|64255] "V" Vector__XXX
   SG_ UtltyAvrageLineLineACRMSVoltage : 0|16@1+ (1,0) [0|64255] "V" Vector__XXX

BO_ 2566784254 GTACR: 8 Vector__XXX
   SG_ GnrtorOverallPowerFactorLagging : 48|2@1+ (1,0) [0|3] "" Vector__XXX
   SG_ GeneratorOverallPowerFactor : 32|16@1+ (1,-1) [-1|2.92181] "" Vector__XXX
   SG_ GeneratorTotalReactivePower : 0|32@1+ (1,-2e+09) [-2e+09|2.21108e+09] "VAr" Vector__XXX

BO_ 2566784510 GTACP: 8 Vector__XXX
   SG_ GeneratorTotalApparentPower : 32|32@1+ (1,-2e+09) [-2e+09|2.21108e+09] "VA" Vector__XXX
   SG_ GeneratorTotalRealPower : 0|32@1+ (1,-2e+09) [-2e+09|2.21108e+09] "W" Vector__XXX

BO_ 2566781694 GTACE: 8 Vector__XXX
   SG_ GeneratorTotalKWHoursImport : 32|32@1+ (1,0) [0|4.21108e+09] "kWh" Vector__XXX
   SG_ GeneratorTotalKWHoursExport : 0|32@1+ (1,0) [0|4.21108e+09] "kWh" Vector__XXX

BO_ 2566781950 GPCACR: 8 Vector__XXX
   SG_ GnratorPhaseCPowerFactorLagging : 48|2@1+ (1,0) [0|3] "" Vector__XXX
   SG_ GeneratorPhaseCPowerFactor : 32|16@1+ (1,-1) [-1|2.92181] "" Vector__XXX
   SG_ GeneratorPhaseCReactivePower : 0|32@1+ (1,-2e+09) [-2e+09|2.21108e+09] "VAr" Vector__XXX

BO_ 2566782206 GPCACP: 8 Vector__XXX
   SG_ GeneratorPhaseCApparentPower : 32|32@1+ (1,-2e+09) [-2e+09|2.21108e+09] "VA" Vector__XXX
   SG_ GeneratorPhaseCRealPower : 0|32@1+ (1,-2e+09) [-2e+09|2.21108e+09] "W" Vector__XXX

BO_ 2566782462 GPCAC: 8 Vector__XXX
   SG_ GeneratorPhaseCACRMSCurrent : 48|16@1+ (1,0) [0|64255] "A" Vector__XXX
   SG_ GeneratorPhaseCACFrequency : 32|16@1+ (1,0) [0|501.992] "Hz" Vector__XXX
   SG_ GnrtrPhsCLneNeutralACRMSVoltage : 16|16@1+ (1,0) [0|64255] "V" Vector__XXX
   SG_ GnrtrPhseCALineLineACRMSVoltage : 0|16@1+ (1,0) [0|64255] "V" Vector__XXX

BO_ 2566782718 GPBACRP: 8 Vector__XXX
   SG_ GnratorPhaseBPowerFactorLagging : 48|2@1+ (1,0) [0|3] "" Vector__XXX
   SG_ GeneratorPhaseBPowerFactor : 32|16@1+ (1,-1) [-1|2.92181] "" Vector__XXX
   SG_ GeneratorPhaseBReactivePower : 0|32@1+ (1,-2e+09) [-2e+09|2.21108e+09] "VAr" Vector__XXX

BO_ 2566782974 GPBACP: 8 Vector__XXX
   SG_ GeneratorPhaseBApparentPower : 32|32@1+ (1,-2e+09) [-2e+09|2.21108e+09] "VA" Vector__XXX
   SG_ GeneratorPhaseBRealPower : 0|32@1+ (1,-2e+09) [-2e+09|2.21108e+09] "W" Vector__XXX

BO_ 2566783230 GPBAC: 8 Vector__XXX
   SG_ GeneratorPhaseBACRMSCurrent : 48|16@1+ (1,0) [0|64255] "A" Vector__XXX
   SG_ GeneratorPhaseBACFrequency : 32|16@1+ (1,0) [0|501.992] "Hz" Vector__XXX
   SG_ GnrtrPhsBLneNeutralACRMSVoltage : 16|16@1+ (1,0) [0|64255] "V" Vector__XXX
   SG_ GnrtrPhseBCLineLineACRMSVoltage : 0|16@1+ (1,0) [0|64255] "V" Vector__XXX

CM_ BO_ 2566742270 "HB1C provides the system specific individual B1 failure counters";
CM_ SG_ 2566742270 FailureSpecificB1Counter "The Failure Specific B1 Counter provides an individual B1 counter";
CM_ SG_ 2566742270 FailureModeIdentifier1 "The FMI defines the type of failure detected in the subsystem identified by an SPN.";
CM_ SG_ 2566742270 SPN1High "SPN #1 (Conversion Version 4)";
CM_ SG_ 2566742270 SPN1 "SPN #1 (Conversion Version 4)";
CM_ BO_ 2566742526 "Cumulative Continuous MI-System";
CM_ SG_ 2566742526 SysGreatestB1Counter "System Greatest B1 Counter";
CM_ SG_ 2566742526 SysCumulativeContinuousMITime "System Cumulative Continuous MI Time";
CM_ BO_ 2566742782 "Harmonized Global Regulation Description";
CM_ SG_ 2566742782 RegulationDescription "Global Technical Regulation Description";
CM_ BO_ 2566743038 "Harmonized Roadworthiness";
CM_ SG_ 2566743038 SysIncompleteMonitorCount "System Incomplete Monitor Count";
CM_ SG_ 2566743038 SysMalIndActivationMode "System Malfunction Indicator Status";
CM_ SG_ 2566743038 SysMalIndDisplayStrategy "System Malfunction Indicator Display";
CM_ SG_ 2566743038 SysContinuousMalfunctionInd "System Continuous Malfunction Indicator";
CM_ SG_ 2566743038 SysNonRoadworthyCompCount "System Non-Roadworthy Component Count";
CM_ BO_ 2566743294 "Harmonized Roadworthiness ";
CM_ SG_ 2566743294 VehicleCurrentMIAccumTime "Vehicle Current MI Accumulated Time";
CM_ SG_ 2566743294 VehicleIncompleteMonitorCount "Vehicle Incomplete Monitor Count";
CM_ SG_ 2566743294 VehicleMalfunctionIndActMode "Vehicle Malfunction Indicator Status ";
CM_ SG_ 2566743294 VehicleMalfunctionIndStrategy "Vehicle Malfunction Indicator Display Strategy ";
CM_ SG_ 2566743294 VehicleContinuousMalfunctionInd "Vehicle Continuous Malfunction Indicator";
CM_ SG_ 2566743294 VehicleNonRoadworthyCompCount "Vehicle Non-Roadworthy Component Count";
CM_ BO_ 2560687870 "The status of engine operating in the NTE control areas for given pollutants, such as NOx and PM";
CM_ SG_ 2560687870 PMNTEDeficiencyAreaStatus "Status of engine operation within the PM NTE Deficiency Area";
CM_ SG_ 2560687870 MnfcPMNTECarveOutAreaStatus "Status of engine operation within the manufacturer specific PM NTE carve out area";
CM_ SG_ 2560687870 PMNTEControlAreaStatus "Status of engine operation within the bounded region of the engine's torque and speed map.";
CM_ SG_ 2560687870 NOxNTEDeficiencyAreaStatus "Status of engine operation within the NOx NTE Deficiency Area";
CM_ SG_ 2560687870 MnfcNOxNTECarveOutAreaStatus "Status of engine operation within the bounded region of the engine's torque and speed map.";
CM_ SG_ 2560687870 NOxNTEControlAreaStatus "Status of engine operation within the bounded region of the engine's torque and speed map.";
CM_ BO_ 2292317950 "The total engine run time while each of the Emission Increasing Auxiliary Emission Control Devices is active";
CM_ SG_ 2292317950 AECDEngineHours1Timer2 "The total engine running hours recorded in the second timer for the EI-AECD";
CM_ SG_ 2292317950 AECDEngineHours1Timer1 "The total engine running hours recorded in the first timer for the EI-AECD";
CM_ SG_ 2292317950 AECDNumber1 "The manufacturer assigned number for the specific EI-AECD";
CM_ BO_ 2566809342 "Battery Main Switch Information";
CM_ SG_ 2566809342 BatteryMainSwitchHoldState "Parameter indicating whether the battery main switch is held due to an external request or not.";
CM_ BO_ 2365446910 "Basic Joystick Message 3";
CM_ SG_ 2365446910 Joystick3XAxisDetentPosStatus "Reports when the current joystick position is in the detent position for that axis of travel.";
CM_ SG_ 2365446910 Joystick3Button9PressedStatus "Reports when the joystick button has been pressed.";
CM_ SG_ 2365446910 Joystick3Button10PressedStatus "Reports when the joystick button has been pressed.";
CM_ SG_ 2365446910 Joystick3Button11PressedStatus "Reports when the joystick button has been pressed.";
CM_ SG_ 2365446910 Joystick3Button12PressedStatus "Reports when the joystick button has been pressed.";
CM_ SG_ 2365446910 Joystick3YAxisDetentPosStatus "Reports when the current joystick position is in the detent position for that axis of travel.";
CM_ SG_ 2365446910 Joystick3YAxisPos "The position of the joystick in the relative motion of travel from the neutral position.";
CM_ SG_ 2365446910 Jystck3YAxsLvrFrwrdPstvPsStatus "Reports when the current joystick position is on the positive travel side (forward, right, clockwise, up) relative to the";
CM_ SG_ 2365446910 Jystck3YAxsLvrBckNgtvePosStatus "Reports when the current joystick position is on the negative travel side (back, left, counterclockwise, down) relative to the";
CM_ SG_ 2365446910 Joystick3YAxisNeutralPosStatus "Reports when the current joystick position is in the neutral position for that axis of travel.";
CM_ SG_ 2365446910 Joystick3XAxisPos "The position of the joystick in the relative motion of travel from the neutral position.";
CM_ SG_ 2365446910 Jystck3XAxsLvrRghtPstvPosStatus "Reports when the current joystick position is on the positive travel side (forward, right, clockwise, up) relative to the";
CM_ SG_ 2365446910 Jystck3XAxsLvrLftNgtvePosStatus "Reports when the current joystick position is on the negative travel side (back, left, counterclockwise, down) relative to the";
CM_ SG_ 2365446910 Joystick3XAxisNeutralPosStatus "Reports when the current joystick position is in the neutral position for that axis of travel.";
CM_ SG_ 2365446910 Joystick3Button5PressedStatus "Reports when the joystick button has been pressed.";
CM_ SG_ 2365446910 Joystick3Button6PressedStatus "Reports when the joystick button has been pressed.";
CM_ SG_ 2365446910 Joystick3Button7PressedStatus "Reports when the joystick button has been pressed.";
CM_ SG_ 2365446910 Joystick3Button8PressedStatus "Reports when the joystick button has been pressed.";
CM_ SG_ 2365446910 Joystick3Button1PressedStatus "Reports when the joystick button has been pressed.";
CM_ SG_ 2365446910 Joystick3Button2PressedStatus "Reports when the joystick button has been pressed.";
CM_ SG_ 2365446910 Joystick3Button3PressedStatus "Reports when the joystick button has been pressed.";
CM_ SG_ 2365446910 Joystick3Button4PressedStatus "Reports when the joystick button has been pressed.";
CM_ BO_ 2365446398 "Basic Joystick Message 2";
CM_ SG_ 2365446398 Joystick2XAxisDetentPosStatus "Reports when the current joystick position is in the detent position for that axis of travel.";
CM_ SG_ 2365446398 Joystick2YAxisDetentPosStatus "Reports when the current joystick position is in the detent position for that axis of travel.";
CM_ SG_ 2365446398 Joystick2YAxisPos "The position of the joystick in the relative motion of travel from the neutral position.";
CM_ SG_ 2365446398 Jystck2YAxsLvrFrwrdPstvPsStatus "Reports when the current joystick position is on the positive travel side (forward, right, clockwise, up) relative to the";
CM_ SG_ 2365446398 Jystck2YAxsLvrBckNgtvePosStatus "Reports when the current joystick position is on the negative travel side (back, left, counterclockwise, down) relative to the";
CM_ SG_ 2365446398 Joystick2YAxisNeutralPosStatus "Reports when the current joystick position is in the neutral position for that axis of travel.";
CM_ SG_ 2365446398 Joystick2XAxisPos "The position of the joystick in the relative motion of travel from the neutral position.";
CM_ SG_ 2365446398 Jystck2XAxsLvrRghtPstvPosStatus "Reports when the current joystick position is on the positive travel side (forward, right, clockwise, up) relative to the";
CM_ SG_ 2365446398 Jystck2XAxsLvrLftNgtvePosStatus "Reports when the current joystick position is on the negative travel side (back, left, counterclockwise, down) relative to the";
CM_ SG_ 2365446398 Joystick2XAxisNeutralPosStatus "Reports when the current joystick position is in the neutral position for that axis of travel.";
CM_ SG_ 2365446398 Joystick2Button9PressedStatus "Reports when the joystick button has been pressed.";
CM_ SG_ 2365446398 Joystick2Button10PressedStatus "Reports when the joystick button has been pressed.";
CM_ SG_ 2365446398 Joystick2Button11PressedStatus "Reports when the joystick button has been pressed.";
CM_ SG_ 2365446398 Joystick2Button12PressedStatus "Reports when the joystick button has been pressed.";
CM_ SG_ 2365446398 Joystick2Button5PressedStatus "Reports when the joystick button has been pressed.";
CM_ SG_ 2365446398 Joystick2Button6PressedStatus "Reports when the joystick button has been pressed.";
CM_ SG_ 2365446398 Joystick2Button7PressedStatus "Reports when the joystick button has been pressed.";
CM_ SG_ 2365446398 Joystick2Button8PressedStatus "Reports when the joystick button has been pressed.";
CM_ SG_ 2365446398 Joystick2Button1PressedStatus "Reports when the joystick button has been pressed.";
CM_ SG_ 2365446398 Joystick2Button2PressedStatus "Reports when the joystick button has been pressed.";
CM_ SG_ 2365446398 Joystick2Button3PressedStatus "Reports when the joystick button has been pressed.";
CM_ SG_ 2365446398 Joystick2Button4PressedStatus "Reports when the joystick button has been pressed.";
CM_ BO_ 2365445886 "Basic Joystick Message 1";
CM_ SG_ 2365445886 Joystick1XAxisDetentPosStatus "Reports when the current joystick position is in the detent position for that axis of travel.";
CM_ SG_ 2365445886 Joystick1YAxisDetentPosStatus "Reports when the current joystick position is in the detent position for that axis of travel.";
CM_ SG_ 2365445886 Joystick1YAxisPos "The position of the joystick in the relative motion of travel from the neutral position.";
CM_ SG_ 2365445886 Jystck1YAxsLvrFrwrdPstvPsStatus "Reports when the current joystick position is on the positive travel side (forward, right, clockwise, up) relative to the";
CM_ SG_ 2365445886 Jystck1YAxsLvrBckNgtvePosStatus "Reports when the current joystick position is on the negative travel side (back, left, counterclockwise, down) relative to the";
CM_ SG_ 2365445886 Joystick1YAxisNeutralPosStatus "Reports when the current joystick position is in the neutral position for that axis of travel.";
CM_ SG_ 2365445886 Joystick1XAxisPos "The position of the joystick in the relative motion of travel from the neutral position.";
CM_ SG_ 2365445886 Joystick1Button9PressedStatus "Reports when the joystick button has been pressed.";
CM_ SG_ 2365445886 Joystick1Button10PressedStatus "Reports when the joystick button has been pressed.";
CM_ SG_ 2365445886 Joystick1Button11PressedStatus "Reports when the joystick button has been pressed.";
CM_ SG_ 2365445886 Joystick1Button12PressedStatus "Reports when the joystick button has been pressed.";
CM_ SG_ 2365445886 Joystick1Button5PressedStatus "Reports when the joystick button has been pressed.";
CM_ SG_ 2365445886 Joystick1Button6PressedStatus "Reports when the joystick button has been pressed.";
CM_ SG_ 2365445886 Joystick1Button7PressedStatus "Reports when the joystick button has been pressed.";
CM_ SG_ 2365445886 Joystick1Button8PressedStatus "Reports when the joystick button has been pressed.";
CM_ SG_ 2365445886 Joystick1Button1PressedStatus "Reports when the joystick button has been pressed.";
CM_ SG_ 2365445886 Joystick1Button2PressedStatus "Reports when the joystick button has been pressed.";
CM_ SG_ 2365445886 Joystick1Button3PressedStatus "Reports when the joystick button has been pressed.";
CM_ SG_ 2365445886 Joystick1Button4PressedStatus "Reports when the joystick button has been pressed.";
CM_ SG_ 2365445886 Jystck1XAxsLvrRghtPstvPosStatus "Reports when the current joystick position is on the positive travel side (forward, right, clockwise, up) relative to the";
CM_ SG_ 2365445886 Jystck1XAxsLvrLftNgtvePosStatus "Reports when the current joystick position is on the negative travel side (back, left, counterclockwise, down) relative to the";
CM_ SG_ 2365445886 Joystick1XAxisNeutralPosStatus "Reports when the current joystick position is in the neutral position for that axis of travel.";
CM_ BO_ 2566847230 "Brakes";
CM_ SG_ 2566847230 ParkingBrakeRedWarningSignal "This parameter commands the Parking Brake red optical warning signal.";
CM_ SG_ 2566847230 ParkBrakeReleaseInhibitStatus "This parameter provides reports on the status of the Park Brake Release Inhibit function.";
CM_ SG_ 2566847230 ParkingBrakeActuator "Signal which indicates the current state of the actuator(s) that control the parking brake (see also SPN 70).";
CM_ SG_ 2566847230 BrakeSecondPress "Gage pressure of air in the secondary, or service side, of the air brake system.";
CM_ SG_ 2566847230 BrakePrimaryPress "Gage pressure of air in the primary, or supply side, of the air brake system.";
CM_ SG_ 2566847230 BrakeAppPress "Gage pressure of compressed air or fluid in vehicle braking system measured at the brake chamber when brake shoe (or";
CM_ BO_ 2566848254 "Auxiliary Water Pump Pressure";
CM_ SG_ 2566848254 AuxPumpPress "Gage pressure of auxiliary water pump driven as a PTO device.";
CM_ BO_ 2566725886 "Aftertreatment 1 Diesel Oxidation Catalyst";
CM_ SG_ 2566725886 Aftrtrtmnt1DslOxdtnCtlystDf_0000 "Used to identify the applicable J1939-73 FMI detected in the diesel oxidation catalyst differential pressure sensor by the";
CM_ SG_ 2566725886 Aftrtrtmnt1DslOxdtnCtlystOtltGsT "Used to identify the applicable J1939-73 FMI detected in the diesel oxidation catalyst outlet gas temperature sensor by";
CM_ SG_ 2566725886 Aftrtrtmnt1DslOxdtnCtlystIntkGsT "Used to identify the applicable J1939-73 FMI detected in the diesel oxidation catalyst intake gas temperature sensor by";
CM_ SG_ 2566725886 Aftrtrtmnt1DslOxdtnCtlystDffPrss "Exhaust differential pressure measured between the intake and exhaust of a diesel oxidation catalyst in exhaust bank 1.";
CM_ SG_ 2566725886 Aftrtrtmnt1DslOxdtnCtlystOt_0000 "Temperature of engine combustion byproducts leaving the diesel oxidation catalyst exhaust in exhaust bank 1.";
CM_ SG_ 2566725886 Aftrtrtmnt1DslOxdtnCtlystIn_0000 "Temperature of engine combustion byproducts entering the diesel oxidation catalyst in exhaust bank 1.";
CM_ BO_ 2560884478 "This message shall provide the applicable lamp for each individual DTC";
CM_ SG_ 2560884478 DTCWarnLampSupportStatus "Lamp support status";
CM_ SG_ 2560884478 DTCWarnLampSupportFlash "Lamp support status";
CM_ SG_ 2560884478 DTCStopLampSupportStatus "Lamp support status";
CM_ SG_ 2560884478 DTCStopLampSupportFlash "Lamp support status";
CM_ SG_ 2560884478 DTCProtectLampSupportStatus "Lamp support status";
CM_ SG_ 2560884478 DTCProtectLampSupportFlash "Lamp support status";
CM_ SG_ 2560884478 DTCMilSupportStatus "Lamp support status";
CM_ SG_ 2560884478 DTCMilSupportFlash "Lamp support status";
CM_ SG_ 2560884478 DTC1 "Diagnostic Trouble Code";
CM_ BO_ 2633844734 "Transmission Mode Labels";
CM_ BO_ 2560360190 "Proprietary Method Identification";
CM_ SG_ 2560360190 DataDictionaryMethod "A manufacturer defined code to define the proprietary communications method.";
CM_ SG_ 2560360190 DataDictionaryManufacturerCode "The J1939 Manufacturer Code (see J1939 Table B10) associated with the manufacturer who defined the proprietary";
CM_ BO_ 2566736126 "Engine Exhaust Bank 2 O2 Fuel Trim";
CM_ SG_ 2566736126 ShorttermFuelTrimBank2 "This parameter is the short-term percent change in fueling based on the O2 sensor feedback for cylinder bank 2, based";
CM_ SG_ 2566736126 LongtermFuelTrimBank2 "This parameter is the long-term percent change in fueling based on the O2 sensor feedback for cylinder bank 2, based on";
CM_ SG_ 2566736126 EngExhstGsOxygnSnsrClsdLpOprtnBn "This parameter indicates the status of the bank 2 O2 sensor feedback closed loop operation";
CM_ BO_ 2566736382 "Engine Exhaust Bank 1 O2 Fuel Trim";
CM_ SG_ 2566736382 ShorttermFuelTrimBank1 "This parameter is the short-term percent change in fueling based on the O2 sensor feedback for cylinder bank 1, based";
CM_ SG_ 2566736382 LongtermFuelTrimBank1 "This parameter is the long-term percent change in fueling based on the O2 sensor feedback for cylinder bank 1, based on";
CM_ SG_ 2566736382 EngExhstGsOxygnSnsrClsdLpOp_0000 "This parameter indicates the status of the bank 1 O2 sensor feedback closed loop operation";
CM_ BO_ 2565874174 "Engine Speed Sensor Information";
CM_ SG_ 2565874174 EngSpdSnsor1TimingPatternStatus "This is the timing pattern status of the engine speed sensor signal for sensor 1.";
CM_ SG_ 2565874174 EngSpdSnsor2TimingPatternStatus "This is the timing pattern status of the engine speed sensor signal for sensor 2.";
CM_ SG_ 2565874174 EngSpdSnsor3TimingPatternStatus "This is the timing pattern status of the engine speed sensor signal for sensor 3.";
CM_ SG_ 2565874174 EngSpeed3 "The engine speed as measured by speed sensor 3.";
CM_ SG_ 2565874174 EngSpeed2 "The engine speed as measured by speed sensor 2";
CM_ SG_ 2565874174 EngSpeed1 "The engine speed as measured by speed sensor 1.";
CM_ BO_ 2432520958 "Engine Coolant Control Valve Command";
CM_ SG_ 2432520958 DsrdEngCoolantThermostatOpening "Indicates the desired position of the engine coolant control valve.";
CM_ SG_ 2432520958 DesiredEngCoolantPumpOutletTemp "Desired engine coolant temperature of the engine to an electronic thermostat.";
CM_ SG_ 2432520958 EngCoolantThermostatMode "Specifies if the engine coolant thermostat valve will operate in temperature control mode or position control mode.";
CM_ BO_ 2560425726 "Auxiliary Input/Output Status 7";
CM_ SG_ 2560425726 AuxI_OChannel19 "Identifies the current value of auxiliary input/output channels that are configured uniquely per application.";
CM_ SG_ 2560425726 AuxI_OChannel20 "Identifies the current value of auxiliary input/output channels that are configured uniquely per application.";
CM_ SG_ 2560425726 AuxI_OChannel21 "Identifies the current value of auxiliary input/output channels that are configured uniquely per application.";
CM_ SG_ 2560425726 AuxI_OChannel22 "Identifies the current value of auxiliary input/output channels that are configured uniquely per application.";
CM_ SG_ 2560425726 AuxI_OChannel15 "Identifies the current value of auxiliary input/output channels that are configured uniquely per application.";
CM_ SG_ 2560425726 AuxI_OChannel16 "Identifies the current value of auxiliary input/output channels that are configured uniquely per application.";
CM_ SG_ 2560425726 AuxI_OChannel17 "Identifies the current value of auxiliary input/output channels that are configured uniquely per application.";
CM_ SG_ 2560425726 AuxI_OChannel18 "Identifies the current value of auxiliary input/output channels that are configured uniquely per application.";
CM_ BO_ 2560491262 "Auxiliary Input/Output Status 6";
CM_ SG_ 2560491262 AuxI_OChannel11 "Identifies the current value of auxiliary input/output channels that are configured uniquely per application.";
CM_ SG_ 2560491262 AuxI_OChannel12 "Identifies the current value of auxiliary input/output channels that are configured uniquely per application.";
CM_ SG_ 2560491262 AuxI_OChannel13 "Identifies the current value of auxiliary input/output channels that are configured uniquely per application.";
CM_ SG_ 2560491262 AuxI_OChannel14 "Identifies the current value of auxiliary input/output channels that are configured uniquely per application.";
CM_ SG_ 2560491262 AuxI_OChannel7 "Identifies the current value of auxiliary input/output channels that are configured uniquely per application.";
CM_ SG_ 2560491262 AuxI_OChannel8 "Identifies the current value of auxiliary input/output channels that are configured uniquely per application.";
CM_ SG_ 2560491262 AuxI_OChannel9 "Identifies the current value of auxiliary input/output channels that are configured uniquely per application.";
CM_ SG_ 2560491262 AuxI_OChannel10 "Identifies the current value of auxiliary input/output channels that are configured uniquely per application.";
CM_ BO_ 2349399806 "Auxiliary Input/Output Status 5";
CM_ SG_ 2349399806 AuxI_OChannel3 "Identifies the current value of auxiliary input/output channels that are configured uniquely per application.";
CM_ SG_ 2349399806 AuxI_OChannel4 "Identifies the current value of auxiliary input/output channels that are configured uniquely per application.";
CM_ SG_ 2349399806 AuxI_OChannel5 "Identifies the current value of auxiliary input/output channels that are configured uniquely per application.";
CM_ SG_ 2349399806 AuxI_OChannel6 "Identifies the current value of auxiliary input/output channels that are configured uniquely per application.";
CM_ BO_ 2566758398 "Aftertreatment 1 Air Control 1";
CM_ SG_ 2566758398 Aftrtreatment1AirEnableActuator "Indicates whether aftertreatment 1 air enable actuator is on or off";
CM_ SG_ 2566758398 Aftertreatment1PurgeAirActuator "Indicates whether aftertreatment 1 purge air actuator is on or off";
CM_ SG_ 2566758398 Aftrtrtmnt1AtmzationAirActuator "Indicates whether aftertreatment 1 atomization air actuator is on or off";
CM_ SG_ 2566758398 Aftertreatment1AirSystemRelay "Indicates whether aftertreatment 1 air system relay is on or off";
CM_ SG_ 2566758398 Aftrtrtment1AirPressActuatorPos "Position of the aftertreatment 1 air pressure actuator as measured by a position feedback sensor.";
CM_ SG_ 2566758398 Aftertreatment1AirPressCtrl "Position that the controller is commanding the aftertreatment 1 air pressure control to maintain.";
CM_ SG_ 2566758398 Aftertreatment1PurgeAirPress "Pressure of the purge air supply for aftertreatment 1";
CM_ SG_ 2566758398 Aftertreatment1SupplyAirPress "Pressure of the supply air for aftertreatment 1.";
CM_ BO_ 2566745598 "Aftertreatment 1 Air Control 2";
CM_ SG_ 2566745598 Aftertreatment1SecondAirPress "Pressure of the secondary air for aftertreatment 1.";
CM_ SG_ 2566745598 Aftrtreatment1SecondAirMassFlow "Indicates the secondary air mass flow for aftertreatment 1.";
CM_ SG_ 2566745598 Aftertreatment1SecondAirTemp "Indicates the secondary air temperature for aftertreatment 1.";
CM_ SG_ 2566745598 Aftrtratment1SecondAirDiffPress "Indicates the secondary air differential pressure for aftertreatment 1.";
CM_ BO_ 2566758910 "Aftertreatment 1 Fuel Control 1";
CM_ SG_ 2566758910 Aftrtrtmnt1FlInjctor1HeaterCtrl "Heating level that the controller is commanding the aftertreatment 1 fuel injector 1 heater control to maintain.";
CM_ SG_ 2566758910 Aftertreatment1FuelPress1Ctrl "Position that the controller is commanding the aftertreatment 1 fuel pressure control to maintain.";
CM_ SG_ 2566758910 Aftrtratment1FuelEnableActuator "Indicates whether aftertreatment 1 fuel enable actuator is on or off";
CM_ SG_ 2566758910 Aftrtratment1RegenerationStatus "Indicates whether regeneration is active or inactive in aftertreatment 1.";
CM_ SG_ 2566758910 Aftertreatment1Ignt "Indicates whether aftertreatment 1 ignition circuit is energized by the ECM.";
CM_ SG_ 2566758910 Aftrtreatment1FuelDrainActuator "Indicates whether aftertreatment 1 fuel drain actuator is on or off";
CM_ SG_ 2566758910 Aftertreatment1FuelRate "Rate of fuel being delivered to aftertreatment 1 for regeneration";
CM_ SG_ 2566758910 Aftertreatment1FuelPress1 "First fuel pressure measurement for the aftertreatment 1 system";
CM_ BO_ 2566743550 "Aftertreatment 1 Fuel Control 2";
CM_ SG_ 2566743550 Aftrtrtmnt1HydrcrbnDsrIntkFlTmp "Measured temperature of the intake fuel to the hydrocarbon dosing device";
CM_ SG_ 2566743550 Aftrtrtmnt1FlPress2ActuatorCtrl "Indicates how the device is controlling the aftertreatment 1 fuel pressure 2 regulating control valve.";
CM_ SG_ 2566743550 Aftrtrtmnt1FlFlwDvrterValveCtrl "Indicates how the device is controlling the aftertreatment 1 fuel flow diverter valve.";
CM_ SG_ 2566743550 Aftrtreatment1FuelPumpRelayCtrl "Indicates how the device is controlling the aftertreatment 1 fuel pump relay.";
CM_ SG_ 2566743550 Aftertreatment1FuelPress2 "Second fuel pressure measurement for the aftertreatment 1 system";
CM_ BO_ 2566753534 "Aftertreatment 1 Gas Parameters";
CM_ SG_ 2566753534 DslPrticulateFilterOutletPress1 "This parameter indicates the diesel particulate filter outlet gage pressure 1 (bank 1).";
CM_ SG_ 2566753534 DslPrticulateFilterIntakePress1 "This parameter indicates the diesel particulate filter intake gage pressure 1 (bank 1).";
CM_ BO_ 2566756606 "Aftertreatment 1 Historical Information";
CM_ SG_ 2566756606 Aftrtrtmnt1TtlNmbrOfActvRgnrtnMn "Total number of aftertreatment device 1 active regeneration manual requests by the operator over the lifetime of the";
CM_ SG_ 2566756606 Aftrtrtmnt1TtlNmbrOfActvRgnrtnIn "Total number of aftertreatment device 1 active regeneration inhibit requests by the operator over the lifetime of the device.";
CM_ SG_ 2566756606 Aftrtrtmnt1AvrgTmBtwnActvRgnrtns "Indicates the average time since last reset between active regenerations, that have not been forced to occur by manual";
CM_ SG_ 2566756606 Aftrtrtmnt1TtlNmbrOfPssvRgnrtns "Total number of passive regenerations by aftertreatment device 1 over the lifetime of the device.";
CM_ SG_ 2566756606 Aftrtrtmnt1TtlPssvRgnrationTime "Total amount of time that aftertreatment device 1 has been in passive regeneration over the lifetime of the device.";
CM_ SG_ 2566756606 Aftrtrtmnt1TtlNmbrOfActvRgnrtns "Total number of active regenerations by aftertreatment device 1 over the lifetime of the device.";
CM_ SG_ 2566756606 Aftrtreatment1TotalDisabledTime "Total amount of time that aftertreatment 1 regeneration has been manually disabled.";
CM_ SG_ 2566756606 Aftrtrtmnt1TtalRegenerationTime "Total amount of time that aftertreatment device 1 has been regenerating over the lifetime of the device.";
CM_ SG_ 2566756606 Aftertreatment1TotalFuelUsed "Total amount of fuel used by aftertreatment device 1 over the lifetime of the device.";
CM_ BO_ 2565869310 "Aftertreatment 1 Intake Gas 1";
CM_ SG_ 2565869310 Aftrtrtmnt1IntkOxygnSnsrPrlmnryF "Used to identify the applicable J1939-73 FMI detected in the aftertreatment intake oxygen sensor by the manufacturer's";
CM_ SG_ 2565869310 Aftrtrtmnt1IntkGsSnsrPwerStatus "Indicates that the power supplied to the aftertreatment intake gas sensor, either NOx or O2, is within the manufacturer's";
CM_ SG_ 2565869310 Aftrtrtmnt1IntkGsSnsrHtrPrlmnryF "Used to identify the applicable J1939-73 FMI detected in the heater of the intake exhaust gas sensor, either NOx or O2,";
CM_ SG_ 2565869310 Aftrtrtmnt1IntkNOxSnsrPrlmnryFMI "Used to identify the applicable J1939-73 FMI detected in the aftertreatment intake NOx sensor by the manufacturer's";
CM_ SG_ 2565869310 Aftrtrtmnt1IntkGsSnsrHeaterCtrl "Indicates the heater status in the warm-up process.";
CM_ SG_ 2565869310 Aftrtrtmnt1IntkWdRngO2RdngStble "Indicates that the %O2 reading of the aftertreatment intake gas sensor, either NOx or O2, is stable as determined by the";
CM_ SG_ 2565869310 Aftrtrtmnt1IntkNOxReadingStable "Indicates that the NOx reading of the aftertreatment intake NOx sensor is stable as determined by the manufacturer's";
CM_ SG_ 2565869310 Aftrtrtmnt1IntkeGasSensorAtTemp "Indicates that the heater element of the aftertreatment intake gas sensor, either NOx or O2, is within the manufacturer's";
CM_ SG_ 2565869310 Aftertreatment1IntakeO2 "The actual oxidation factor (%O2) of the gas within the exhaust stream.";
CM_ SG_ 2565869310 Aftertreatment1IntakeNOx "The amount of combined NO and NO2 in the exhaust entering the aftertreatment system measured by a NOx sensor at";
CM_ BO_ 2566763774 "Aftertreatment 1 Intake Gas 2";
CM_ SG_ 2566763774 Aftrtrtmnt1DslPrtcltFltrIntkGsTm "Used to identify the applicable J1939-73 FMI detected in the diesel particulate filter intake gas temperature sensor by the";
CM_ SG_ 2566763774 Aftrtrtmnt1ExhstGsTmp1PrlmnryFMI "Used to identify the applicable J1939-73 FMI detected in the exhaust gas temperature 1 sensor by the manufacturer's";
CM_ SG_ 2566763774 Aftertreatment1ExhaustGasTemp1 "The reading from the exhaust gas temperature sensor located farthest upstream in the aftertreatment system in exhaust bank 1.";
CM_ SG_ 2566763774 Aftrtrtmnt1DslPrtcltFltrInt_0000 "Temperature of engine combustion byproducts entering the diesel particulate filter in exhaust bank 1.";
CM_ BO_ 2631728894 "Anti-theft Status";
CM_ SG_ 2631728894 AntitheftRandomNumber "A seven byte random numeric code provided by the component in response to an anti-theft request.";
CM_ SG_ 2631728894 AntitheftComponentStatusStates "Indicates whether or not the component can be started.";
CM_ SG_ 2631728894 AntthftEncryptnSdPrsntIndicator "Indicates the presence of the encryption seed random number.";
CM_ SG_ 2631728894 AntitheftModifyPwdStates "This parameter is used to indicate whether a password request was successfully performed, or if the request could not be";
CM_ SG_ 2631728894 AntitheftPwdValidIndicator "Indicates the presence of a validated password.";
CM_ BO_ 2631794430 "Anti-theft Request";
CM_ SG_ 2631794430 AntitheftPasswordRepresentation "This parameter is the seven byte numeric code (i.";
CM_ SG_ 2631794430 AntitheftCmdStates "This parameter is used to identify the specific requests being sent to the component.";
CM_ SG_ 2631794430 AntitheftDesiredExitModeStates "This parameter is used to specify the desired triggers that are to be used by the component in deciding when to transition";
CM_ SG_ 2631794430 AntthftEncryptonIndicatorStates "This parameter is used to indicate if a random number seed is being requested, or if an encrypted password is being";
CM_ BO_ 2633934846 "Alternator Temperature";
CM_ SG_ 2633934846 EngAltWinding3Temp "Temperature of the windings inside the alternator.";
CM_ SG_ 2633934846 EngAltWinding2Temp "Temperature of the windings inside the alternator.";
CM_ SG_ 2633934846 EngAltWinding1Temp "Temperature of the windings inside the alternator.";
CM_ SG_ 2633934846 EngAltBearing2Temp "Temperature of the bearing inside the alternator.";
CM_ SG_ 2633934846 EngAltBearing1Temp "Temperature of the bearing inside the alternator.";
CM_ BO_ 2362572542 "Air Suspension Control 6";
CM_ SG_ 2362572542 LevelPresetRearAxleRight "Set value for nominal level 'preset level' at the right side of the rear axle.";
CM_ SG_ 2362572542 LevelPresetRearAxleLeft "Set value for nominal level 'preset level' at the left side of the rear axle.";
CM_ SG_ 2362572542 LevelPresetFrontAxleRight "Set value for nominal level 'preset level' at the right side of the front axle.";
CM_ SG_ 2362572542 LevelPresetFrontAxleLeft "Set value for nominal level 'preset level' at the left side of the front axle.";
CM_ BO_ 2365478910 "Air Suspension Control 5";
CM_ SG_ 2365478910 ElctrncShckAbsrbrCtrlMdLft_TgAxl "Signal which indicates the current mode of operation of the electronic shock absorber control at the lift/tag axle.";
CM_ SG_ 2365478910 ElctrncShckAbsrbrCtrlMdRearAxle "Signal which indicates the current mode of operation of the electronic shock absorber control at the rear axle.";
CM_ SG_ 2365478910 ElctrncShckAbsrbrCtrlMdFrntAxle "Signal which indicates the current mode of operation of the electronic shock absorber control at the front axle.";
CM_ SG_ 2365478910 DamperStiffnessLift_TagAxle "Damper stiffness information of the shock absorber control at the lift of tag axle";
CM_ SG_ 2365478910 DamperStiffnessRearAxle "Damper stiffness information of the shock absorber control at the rear axle";
CM_ SG_ 2365478910 DamperStiffnessFrontAxle "Damper stiffness information of the shock absorber control at the front axle";
CM_ BO_ 2560950014 "This message conveys the scaled test results for the applicable test requested in DM7.";
CM_ SG_ 2560950014 TestLimitMinimum "The test value must be greater than or equal to Test Limit Minimum in order for the test to pass";
CM_ SG_ 2560950014 TestLimitMaximum "The test value must be less than or equal to Test Limit Maximum in order for the test to pass.";
CM_ SG_ 2560950014 TestValue "The test value collected during the test.";
CM_ SG_ 2560950014 SlotId "The SLOT Identifer is used to determine the multiplier and offset to be used to scale the test value.";
CM_ SG_ 2560950014 TestIdentifier "Test Identifier";
CM_ SG_ 2560950014 FailureModeIdentifier1 "The FMI defines the type of failure detected in the subsystem identified by an SPN.";
CM_ SG_ 2560950014 SPN1High "SPN #1 (Conversion Version 4)";
CM_ SG_ 2560950014 SPN1 "SPN #1 (Conversion Version 4)";
CM_ BO_ 2566763262 "Aftertreatment 1 Intermediate Gas";
CM_ SG_ 2566763262 Aftrtrtmnt1DslPrtcltFltrIntrmdtG "Used to identify the applicable J1939-73 FMI detected in the diesel particulate filter intermediate gas temperature sensor";
CM_ SG_ 2566763262 Aftrtrtmnt1DslPrtcltFltrInt_0001 "Temperature of engine combustion byproducts at a mid-point in the diesel particulate filter in exhaust bank 1.";
CM_ SG_ 2566763262 Aftrtrtmnt1DslPrtcltFltrDltPrssP "Used to identify the applicable J1939-73 FMI detected in the diesel particulate filter differential pressure sensor by the";
CM_ SG_ 2566763262 Aftrtrtmnt1DslPrtcltFltrDffPrss "Exhaust differential pressure measured between the intake and exhaust of a diesel particulate filter in exhaust bank 1.";
CM_ SG_ 2566763262 Aftrtrtmnt1ExhstGsTmp2PrlmnryFMI "Used to identify the applicable J1939-73 FMI detected in the exhaust gas temperature 2 sensor by the manufacturer's sensor";
CM_ SG_ 2566763262 Aftertreatment1ExhaustGasTemp2 "The reading from the exhaust gas temperature sensor located midstream of the other two temperature sensors in the";
CM_ BO_ 2565869566 "Aftertreatment 1 Outlet Gas 1";
CM_ SG_ 2565869566 Aftrtrtmnt1OtltOxygnSnsrPrlmnryF "Used to identify the applicable J1939-73 FMI detected in the aftertreatment outlet oxygen sensor by the manufacturer's";
CM_ SG_ 2565869566 Aftrtrtmnt1OtltGsSnsrPwerStatus "Indicates that the power supplied to the aftertreatment outlet gas sensor, either NOx or O2, is within the manufacturer's";
CM_ SG_ 2565869566 Aftrtrtmnt1OtltGsSnsrHtrPrlmnryF "Used to identify the applicable J1939-73 FMI detected in the heater of the outlet exhaust gas sensor, either NOx or O2, by";
CM_ SG_ 2565869566 Aftrtrtmnt1OtltNOxSnsrPrlmnryFMI "Used to identify the applicable J1939-73 FMI detected in the aftertreatment outlet NOx sensor by the manufacturer's";
CM_ SG_ 2565869566 Aftrtrtmnt1OtltGsSnsrHeaterCtrl "Indicates the heater status in the warm-up process.";
CM_ SG_ 2565869566 Aftrtrtmnt1OtltWdRngO2RdngStble "Indicates that the %O2 reading of the aftertreatment outlet gas sensor, either NOx or O2, is stable as determined by the";
CM_ SG_ 2565869566 Aftrtrtmnt1OtltNOxReadingStable "Indicates that the NOx reading of the aftertreatment outlet NOx sensor is stable as determined by the manufacturer's";
CM_ SG_ 2565869566 Aftrtrtmnt1OtletGasSensorAtTemp "Indicates that the heater element of the aftertreatment outlet gas sensor, either NOx or O2, is within the manufacturer's";
CM_ SG_ 2565869566 Aftertreatment1OutletO2 "The actual oxidation factor (%O2) of the gas within the exhaust stream.";
CM_ SG_ 2565869566 Aftertreatment1OutletNOx "The amount of combined NO and NO2 in the exhaust entering the aftertreatment system measured by a NOx sensor at";
CM_ BO_ 2566763518 "Aftertreatment 1 Outlet Gas 2";
CM_ SG_ 2566763518 Aftrtrtmnt1DslPrtcltFltrOtltGsTm "Temperature of engine combustion byproducts leaving the diesel particulate filter exhaust in exhaust bank 1.";
CM_ SG_ 2566763518 Aftrtrtmnt1DslPrtcltFltrOtltExhs "Used to identify the applicable J1939-73 FMI detected in the diesel particulate filter outlet gas temperature sensor by the";
CM_ SG_ 2566763518 Aftrtrtmnt1ExhstGsTmp3PrlmnryFMI "Used to identify the applicable J1939-73 FMI detected in the exhaust gas temperature 3 sensor by the manufacturer's";
CM_ SG_ 2566763518 Aftertreatment1ExhaustGasTemp3 "The reading from the exhaust gas temperature sensor located farthest downstream in the aftertreatment system in";
CM_ BO_ 2566749182 "Aftertreatment 1 Service";
CM_ SG_ 2566749182 DslPrtclteFilter1AshLoadPercent "Indicates the ash load percent of diesel particulate filter 1.";
CM_ SG_ 2566749182 DslPrtcltFltr1TmSncLstActvRgnrtn "Indicates the time since the last active regeneration event of diesel particulate filter 1.";
CM_ SG_ 2566749182 DslPrtcltFilter1SootLoadPercent "Indicates the soot load percent of diesel particulate filter 1.";
CM_ SG_ 2566749182 Aftrtrtmnt1DslPrtcltFltrStLdRgnr "This parameter indicates the value that will first cause DPF regeneration in aftertreatment 1.";
CM_ BO_ 2566748670 "Aftertreatment 1 Trip Information";
CM_ SG_ 2566748670 Aftrtrtmnt1TrpNmbrOfActvRgnrtnMn "Total number of Aftertreatment device 1 active regeneration manual requests by the operator during the current trip";
CM_ SG_ 2566748670 Aftrtrtmnt1TrpNmbrOfActvRgnrtnIn "Total number of aftertreatment device 1 active regeneration inhibit requests by the operator during the current trip period.";
CM_ SG_ 2566748670 Aftrtrtmnt1TrpNmbrOfPssvRgnrtns "Total number of passive regenerations by Aftertreatment device 1 during the current trip period.";
CM_ SG_ 2566748670 Aftrtrtmnt1TrpPssvRgnrationTime "Total amount of time that aftertreatment device 1 has been in passive regeneration during the current trip period.";
CM_ SG_ 2566748670 Aftrtrtmnt1TrpNmbrOfActvRgnrtns "Total number of active regenerations by Aftertreatment device 1 during the current trip period.";
CM_ SG_ 2566748670 Aftertreatment1TripDisabledTime "Total amount of time that aftertreatment 1 regeneration has been manually disabled during the current trip period.";
CM_ SG_ 2566748670 Aftrtrtmnt1TrpActvRgnrationTime "Total amount of time that aftertreatment device 1 has been in active regeneration during the current trip period.";
CM_ SG_ 2566748670 Aftertreatment1TripFuelUsed "Total amount of fuel used by aftertreatment device 1 during the current trip period.";
CM_ BO_ 2566758142 "Aftertreatment 2 Air Control 1";
CM_ SG_ 2566758142 Aftrtreatment2AirEnableActuator "Indicates whether aftertreatment 2 air enable actuator is on or off";
CM_ SG_ 2566758142 Aftertreatment2PurgeAirActuator "Indicates whether aftertreatment 2 purge air actuator is on or off";
CM_ SG_ 2566758142 Aftrtrtmnt2AtmzationAirActuator "Indicates whether aftertreatment 2 atomization air actuator is on or off";
CM_ SG_ 2566758142 Aftertreatment2AirSystemRelay "Indicates whether aftertreatment 2 air system relay is on or off";
CM_ SG_ 2566758142 Aftrtrtment2AirPressActuatorPos "Position of the aftertreatment 2 air pressure actuator as measured by a position feedback sensor.";
CM_ SG_ 2566758142 Aftertreatment2AirPressCtrl "Position that the controller is commanding the aftertreatment 2 air pressure control to maintain.";
CM_ SG_ 2566758142 Aftertreatment2PurgeAirPress "Pressure of the purge air supply for aftertreatment 2";
CM_ SG_ 2566758142 Aftertreatment2SupplyAirPress "Pressure of the supply air for aftertreatment 2.";
CM_ BO_ 2566745342 "Aftertreatment 2 Air Control 2";
CM_ SG_ 2566745342 Aftertreatment2SecondAirPress "Pressure of the secondary air for aftertreatment 2.";
CM_ SG_ 2566745342 Aftrtreatment2SecondAirMassFlow "Indicates the secondary air mass flow for aftertreatment 2.";
CM_ SG_ 2566745342 Aftertreatment2SecondAirTemp "Indicates the secondary air temperature for aftertreatment 2.";
CM_ SG_ 2566745342 Aftrtratment2SecondAirDiffPress "Indicates the secondary air differential pressure for aftertreatment 2.";
CM_ BO_ 2566758654 "Aftertreatment 2 Fuel Control 1";
CM_ SG_ 2566758654 Aftrtrtmnt2FlInjctor1HeaterCtrl "Heating level that the controller is commanding the aftertreatment 2 fuel injector 1 heater control to maintain.";
CM_ SG_ 2566758654 Aftertreatment2FuelPress1Ctrl "Position that the controller is commanding the aftertreatment 2 fuel pressure control to maintain.";
CM_ SG_ 2566758654 Aftertreatment2FuelPress1 "Pressure of the fuel for Aftertreatment 2.";
CM_ SG_ 2566758654 Aftrtratment2FuelEnableActuator "Indicates whether aftertreatment 2 fuel enable actuator is on or off";
CM_ SG_ 2566758654 Aftrtratment2RegenerationStatus "Indicates whether regeneration is active or inactive in aftertreatment 2.";
CM_ SG_ 2566758654 Aftertreatment2Ignt "Indicates whether aftertreatment 2 ignition circuit is energized by the ECM.";
CM_ SG_ 2566758654 Aftrtreatment2FuelDrainActuator "Indicates whether aftertreatment 2 fuel drain actuator is on or off";
CM_ SG_ 2566758654 Aftertreatment2FuelRate "Rate of fuel being delivered to aftertreatment 2 for regeneration";
CM_ BO_ 2566753278 "Aftertreatment 2 Gas Parameters";
CM_ SG_ 2566753278 DslPrticulateFilterOutletPress2 "This parameter indicates the diesel particulate filter outlet gage pressure 2 (bank 2).";
CM_ SG_ 2566753278 DslPrticulateFilterIntakePress2 "This parameter indicates the diesel particulate filter intake gage pressure 2 (bank 2).";
CM_ BO_ 2566756862 "Aftertreatment 2 Historical information";
CM_ SG_ 2566756862 Aftrtrtmnt2TtlNmbrOfActvRgnrtnMn "Total number of Aftertreatment device 2 active regeneration manual requests by the operator over the lifetime of the";
CM_ SG_ 2566756862 Aftrtrtmnt2TtlNmbrOfActvRgnrtnIn "Total number of Aftertreatment device 2 active regeneration inhibit requests by the operator over the lifetime of the";
CM_ SG_ 2566756862 Aftrtrtmnt2AvrgTmBtwnActvRgnrtns "Indicates the average time since last reset between active regenerations, that have not been forced to occur by manual";
CM_ SG_ 2566756862 Aftrtrtmnt2TtlNmbrOfPssvRgnrtns "Total number of passive regenerations by Aftertreatment device 2 over the lifetime of the device.";
CM_ SG_ 2566756862 Aftrtrtmnt2TtlPssvRgnrationTime "Total amount of time that Aftertreatment device 2 has been in passive regeneration over the lifetime of the device.";
CM_ SG_ 2566756862 Aftrtrtmnt2TtlNmbrOfActvRgnrtns "Total number of active regenerations by aftertreatment device 2 over the lifetime of the device.";
CM_ SG_ 2566756862 Aftrtreatment2TotalDisabledTime "Total amount of time that aftertreatment 2 regeneration has been manually disabled.";
CM_ SG_ 2566756862 Aftrtrtmnt2TtalRegenerationTime "Total amount of time that aftertreatment device 2 has been regenerating over the lifetime of the device.";
CM_ SG_ 2566756862 Aftertreatment2TotalFuelUsed "Total amount of fuel used by aftertreatment device 2 over the lifetime of the device.";
CM_ BO_ 2565869822 "Aftertreatment 2 Intake Gas 1";
CM_ SG_ 2565869822 Aftrtrtmnt2IntkOxygnSnsrPrlmnryF "Used to identify the applicable J1939-73 FMI detected in the aftertreatment intake oxygen sensor by the manufacturer's";
CM_ SG_ 2565869822 Aftrtrtmnt2IntkGsSnsrPwerStatus "Indicates that the power supplied to the aftertreatment intake gas sensor, either NOx or O2, is within the manufacturer's";
CM_ SG_ 2565869822 Aftrtrtmnt2IntkGsSnsrHtrPrlmnryF "Used to identify the applicable J1939-73 FMI detected in the heater of the intake exhaust gas sensor, either NOx or O2,";
CM_ SG_ 2565869822 Aftrtrtmnt2IntkNOxSnsrPrlmnryFMI "Used to identify the applicable J1939-73 FMI detected in the aftertreatment intake NOx sensor by the manufacturer's";
CM_ SG_ 2565869822 Aftrtrtmnt2IntkGsSnsrHeaterCtrl "Indicates the heater status in the warm-up process.";
CM_ SG_ 2565869822 Aftrtrtmnt2IntkWdRngO2RdngStble "Indicates that the %O2 reading of the aftertreatment intake gas sensor, either NOx or O2, is stable as determined by the";
CM_ SG_ 2565869822 Aftrtrtmnt2IntkNOxReadingStable "Indicates that the NOx reading of the aftertreatment intake NOx sensor is stable as determined by the manufacturer's";
CM_ SG_ 2565869822 Aftrtrtmnt2IntkeGasSensorAtTemp "Indicates that the heater element of the aftertreatment intake gas sensor, either NOx or O2, is within the manufacturer's";
CM_ SG_ 2565869822 Aftertreatment2IntakeO2 "The actual oxidation factor (%O2) of the gas within the exhaust stream.";
CM_ SG_ 2565869822 Aftertreatment2IntakeNOx "The amount of combined NO and NO2 in the exhaust entering the aftertreatment system measured by a NOx sensor at";
CM_ BO_ 2566763006 "Aftertreatment 2 Intake Gas 2";
CM_ SG_ 2566763006 Aftrtrtmnt2DslPrtcltFltrIntkGsTm "Used to identify the applicable J1939-73 FMI detected in the diesel particulate filter intake gas temperature sensor by the";
CM_ SG_ 2566763006 Aftrtrtmnt2ExhstGsTmp1PrlmnryFMI "Used to identify the applicable J1939-73 FMI detected in the exhaust gas temperature 1 sensor by the manufacturer's";
CM_ SG_ 2566763006 Aftertreatment2ExhaustGasTemp1 "The reading from the exhaust gas temperature sensor located farthest upstream in the aftertreatment system in exhaust bank 2.";
CM_ SG_ 2566763006 Aftrtrtmnt2DslPrtcltFltrInt_0000 "Temperature of engine combustion byproducts entering the diesel particulate filter in exhaust bank 2.";
CM_ BO_ 2566762494 "Aftertreatment 2 Intermediate Gas";
CM_ SG_ 2566762494 Aftrtrtmnt2DslPrtcltFltrIntrmdtG "Used to identify the applicable J1939-73 FMI detected in the diesel particulate filter intermediate gas temperature sensor";
CM_ SG_ 2566762494 Aftrtrtmnt2DslPrtcltFltrInt_0001 "Temperature of engine combustion byproducts at a mid-point in the diesel particulate filter in exhaust bank 2.";
CM_ SG_ 2566762494 Aftrtrtmnt2DslPrtcltFltrDltPrssP "Used to identify the applicable J1939-73 FMI detected in the diesel particulate filter differential pressure sensor by the";
CM_ SG_ 2566762494 Aftrtrtmnt2DslPrtcltFltrDffPrss "Exhaust differential pressure measured between the intake and exhaust of a diesel particulate filter in exhaust bank 2.";
CM_ SG_ 2566762494 Aftrtrtmnt2ExhstGsTmp2PrlmnryFMI "Used to identify the applicable J1939-73 FMI detected in the exhaust gas temperature 2 sensor by the manufacturer's";
CM_ SG_ 2566762494 Aftertreatment2ExhaustGasTemp2 "The reading from the exhaust gas temperature sensor located midstream of the other two temperature sensors in the";
CM_ BO_ 2565870078 "Aftertreatment 2 Outlet Gas 1";
CM_ SG_ 2565870078 Aftrtrtmnt2OtltOxygnSnsrPrlmnryF "Used to identify the applicable J1939-73 FMI detected in the aftertreatment outlet oxygen sensor by the manufacturer's";
CM_ SG_ 2565870078 Aftrtrtmnt2OtltGsSnsrPwerStatus "Indicates that the power supplied to the aftertreatment outlet gas sensor, either NOx or O2, is within the manufacturer's";
CM_ SG_ 2565870078 Aftrtrtmnt2OtltGsSnsrHtrPrlmnryF "Used to identify the applicable J1939-73 FMI detected in the heater of the outlet exhaust gas sensor, either NOx or O2, by";
CM_ SG_ 2565870078 Aftrtrtmnt2OtltNOxSnsrPrlmnryFMI "Used to identify the applicable J1939-73 FMI detected in the aftertreatment outlet NOx sensor by the manufacturer's";
CM_ SG_ 2565870078 Aftrtrtmnt2OtltGsSnsrHeaterCtrl "Indicates the heater status in the warm-up process.";
CM_ SG_ 2565870078 Aftrtrtmnt2OtltWdRngO2RdngStble "Indicates that the %O2 reading of the aftertreatment outlet gas sensor, either NOx or O2, is stable as determined by the";
CM_ SG_ 2565870078 Aftrtrtmnt2OtltNOxReadingStable "Indicates that the NOx reading of the aftertreatment outlet NOx sensor is stable as determined by the manufacturer's";
CM_ SG_ 2565870078 Aftrtrtmnt2OtletGasSensorAtTemp "Indicates that the heater element of the aftertreatment outlet gas sensor, either NOx or O2, is within the manufacturer's";
CM_ SG_ 2565870078 Aftertreatment2OutletO2 "The actual oxidation factor (%O2) of the gas within the exhaust stream.";
CM_ SG_ 2565870078 Aftertreatment2OutletNOx "The amount of combined NO and NO2 in the exhaust entering the aftertreatment system measured by a NOx sensor at";
CM_ BO_ 2566762750 "Aftertreatment 2 Outlet Gas 2";
CM_ SG_ 2566762750 Aftrtrtmnt2DslPrtcltFltrOtltGsTm "Temperature of engine combustion byproducts leaving the diesel particulate filter exhaust in exhaust bank 2.";
CM_ SG_ 2566762750 Aftrtrtmnt2DslPrtcltFltrExhstGsT "Used to identify the applicable J1939-73 FMI detected in the diesel particulate filter outlet gas temperature sensor by the";
CM_ SG_ 2566762750 Aftrtrtmnt2ExhstGsTmp3PrlmnryFMI "Used to identify the applicable J1939-73 FMI detected in the exhaust gas temperature 3 sensor by the manufacturer's";
CM_ SG_ 2566762750 Aftertreatment2ExhaustGasTemp3 "The reading from the exhaust gas temperature sensor located farthest downstream in the aftertreatment system in";
CM_ BO_ 2566748926 "Aftertreatment 2 Service";
CM_ SG_ 2566748926 DslPrtclteFilter2AshLoadPercent "Indicates the ash load percent of diesel particulate filter 2.";
CM_ SG_ 2566748926 DslPrtcltFltr2TmSncLstActvRgnrtn "Indicates the time since the last active regeneration event of diesel particulate filter 2.";
CM_ SG_ 2566748926 DslPrtcltFilter2SootLoadPercent "Indicates the soot load percent of diesel particulate filter 2.";
CM_ SG_ 2566748926 Aftrtrtmnt2DslPrtcltFltrStLdRgnr "This parameter indicates the value that will first cause DPF regeneration in aftertreatment 2.";
CM_ BO_ 2566748414 "Aftertreatment 2 Trip Information";
CM_ SG_ 2566748414 Aftrtrtmnt2TrpNmbrOfActvRgnrtnMn "Total number of aftertreatment device 2 active regeneration manual requests by the operator during the current trip";
CM_ SG_ 2566748414 Aftrtrtmnt2TrpNmbrOfActvRgnrtnIn "Total number of aftertreatment device 2 active regeneration inhibit requests by the operator during the current trip period.";
CM_ SG_ 2566748414 Aftrtrtmnt2TrpNmbrOfPssvRgnrtns "Total number of passive regenerations by aftertreatment device 2 during the current trip period.";
CM_ SG_ 2566748414 Aftrtrtmnt2TrpPssvRgnrationTime "Total amount of time that aftertreatment device 2 has been in passive regeneration during the current trip period.";
CM_ SG_ 2566748414 Aftrtrtmnt2TrpNmbrOfActvRgnrtns "Total number of active regenerations by aftertreatment device 2 during the current trip period.";
CM_ SG_ 2566748414 Aftertreatment2TripDisabledTime "Total amount of time that aftertreatment 2 regeneration has been manually disabled during the current trip period.";
CM_ SG_ 2566748414 Aftrtrtmnt2TrpActvRgnrationTime "Total amount of time that aftertreatment device 2 has been in active regeneration during the current trip period.";
CM_ SG_ 2566748414 Aftertreatment2TripFuelUsed "Total amount of fuel used by aftertreatment device 2 during the current trip period.";
CM_ BO_ 2365428478 "Engine Operating Information";
CM_ SG_ 2365428478 EngDerateRq "This parameter is a derate request made from the engine control system to an external system, where the engine is";
CM_ SG_ 2365428478 EngEmergencyShutdownIndication "A signal issued by the engine control system to a user or external system indicating that it is immediately shutting the engine";
CM_ SG_ 2365428478 EngCtrlledShutdownRq "A signal issued by the engine control system to a user or external system requesting for a controlled shutdown.";
CM_ SG_ 2365428478 EngCoolantCirculatingPumpCtrl "Control setting for an electrically actuated engine coolant circulating pump.";
CM_ SG_ 2365428478 EngBlock_CoolantPreheaterCtrl "Control setting for an electrically actuated engine block or coolant pre-heating device.";
CM_ SG_ 2365428478 EngElctrclSystmPwrCnsrvtionCtrl "Control setting for cutting power to various devices when the engine is not in use.";
CM_ SG_ 2365428478 EngOilPreheaterCtrl "Control setting for an electrically actuated oil pre-heating device.";
CM_ SG_ 2365428478 EngOilPrimingPumpCtrl "This control is used to activate a pump that lubricates the engine, particularly prior to initial engine startup.";
CM_ SG_ 2365428478 EngFuelShutoffValveLeakTestCtrl "Control setting for fuel shutoff valve proving system test.";
CM_ SG_ 2365428478 EngFuelShutoff2Ctrl "Control setting for fuel shutoff 2.";
CM_ SG_ 2365428478 EngFuelShutoff1Ctrl "Control setting for fuel shutoff 1.";
CM_ SG_ 2365428478 EngFuelShutoffVentCtrl "Control setting for a fuel shutoff vent.";
CM_ SG_ 2365428478 TmeRemainingInEngOperatingState "This parameter is used to indicate the time remaining in the current engine operating state, based on the state defined in";
CM_ SG_ 2365428478 FuelPumpPrimerCtrl "Parameter used to activate or deactivate a priming system on the fuel transfer system.";
CM_ SG_ 2365428478 EngOperatingState "This parameter is used to indicate the current state, or mode, of operation by the engine.";
CM_ BO_ 2566743806 "Engine Temperature 4";
CM_ SG_ 2566743806 EngExhstVlvActtionSystemOilTemp "The temperature of the oil in the hydraulic system that powers the engine exhaust valve actuation system";
CM_ SG_ 2566743806 EngExhstGsRcrcltn1MxrIntakeTemp "The temperature of the EGR gas entering the intake mixer, measured after the intake throttle when provided.";
CM_ SG_ 2566743806 EngCoolantThermostatOpening "The current position of the Thermostat used to regulate the temperature of the engine coolant.";
CM_ SG_ 2566743806 EngCoolantPumpOutletTemp "The actual value of engine coolant temperature at the coolant pump outlet";
CM_ SG_ 2566743806 EngCoolantTemp2 "Second temperature of liquid found in the engine cooling system.";
CM_ BO_ 2499635454 "Gross Combination Vehicle Weight";
CM_ SG_ 2499635454 NetVehicleWeightChange "Identifies the net vehicle weight change from the time of last vehicle net weight zeroing.";
CM_ SG_ 2499635454 GrossCombinationWeight "Total weight of the truck and all the trailers with on-board scales.";
CM_ BO_ 2550660862 "General Purpose Valve Pressure";
CM_ SG_ 2550660862 ValveAssemblySupplyPress "Pressure of the hydraulic supply port to a valve assembly.";
CM_ SG_ 2550660862 ValveAssemblyLoadSensePress "The maximum pressure of a valve assembly's current collective load sense pressures where a valve assembly can";
CM_ SG_ 2550660862 ValvePilotPress "Pressure of a valve's pilot supply port.";
CM_ SG_ 2550660862 ValveLoadSensePress "The maximum of the currently measured pressures of a valve's work port A and work port B.";
CM_ BO_ 2566805758 "Air Suspension Control 4";
CM_ SG_ 2566805758 BellowPressRearAxleRight "Information of the pressure of the air suspension bellow at the right side of the rear axle";
CM_ SG_ 2566805758 BellowPressRearAxleLeft "Information of the pressure of the air suspension bellow at the left side of the rear axle";
CM_ SG_ 2566805758 BellowPressFrontAxleRight "Information of the pressure of the air suspension bellow at the right side of the front axle";
CM_ SG_ 2566805758 BellowPressFrontAxleLeft "Information of the pressure of the air suspension bellow at the left side of the front axle";
CM_ BO_ 2566806014 "Air Suspension Control 3";
CM_ SG_ 2566806014 RelativeLevelRearAxleRight "Information of the height at the left side of the rear axle referred to normal level 1.";
CM_ SG_ 2566806014 RelativeLevelRearAxleLeft "Information of the height at the left side of the rear axle referred to normal level 1.";
CM_ SG_ 2566806014 RelativeLevelFrontAxleRight "Information of the height at the right side of the front axle referred to normal level 1.";
CM_ SG_ 2566806014 RelativeLevelFrontAxleLeft "Information of the height at the left side of the front axle referred to normal level 1.";
CM_ BO_ 2362638078 "Air Suspension Control 2";
CM_ SG_ 2362638078 SpeedDependentLevelCtrlRq "This parameter activates speed dependent level control in suspension system.";
CM_ SG_ 2362638078 PrhbtAutomaticAirSuspensionCtrl "[Ed note - description needs to be reviewed and adjusted as necessary]";
CM_ SG_ 2362638078 MemoryLevelRq "Signal which indicates that the air suspension control requests a memory level or a memory level shall be stored.";
CM_ SG_ 2362638078 AllowLevelCtrlDuringBrakingCmd "This parameter overides the inhibit of level control during braking.";
CM_ SG_ 2362638078 ProhibitAirSuspensionCtrl "This parameter is an external request to the air suspension control system to prohibit all air suspension control.";
CM_ SG_ 2362638078 KneelingCmdRearAxle "Command signal to activate the kneeling functionality at the rear axle of the vehicle.";
CM_ SG_ 2362638078 KneelingCmdFrontAxle "Command signal to activate the kneeling functionality at the front axle of the vehicle";
CM_ SG_ 2362638078 DamperStiffnessRqLift_TagAxle "Demand value for the shock absorber control at the lift or tag axle";
CM_ SG_ 2362638078 DamperStiffnessRqRearAxle "Demand value for the shock absorber control at the rear axle.";
CM_ SG_ 2362638078 DamperStiffnessRqFrontAxle "Demand value for the shock absorber control at the front axle.";
CM_ SG_ 2362638078 LevelCtrlModeRq "Command signal to activate a level control mode";
CM_ SG_ 2362638078 NominalLevelRqRearAxle "Command signal to activate a level of the rear axle programmed and/or memorized in the ECU.";
CM_ SG_ 2362638078 NominalLevelRqFrontAxle "Command signal to activate a level of the front axle programmed and/or memorized in the ECU For explanations of";
CM_ SG_ 2362638078 KneelingCtrlModeRq "Command signal to select the kneeling functionality";
CM_ SG_ 2362638078 KneelingRqRightSide "Command signal to activate the kneeling functionality on the right side of the vehicle";
CM_ SG_ 2362638078 KneelingRqLeftSide "Command signal to activate the kneeling functionality on the left side of the vehicle";
CM_ SG_ 2362638078 AutomaticTractionHelp "This signal enables the traction help (load transfer) in case of an active ASR function";
CM_ SG_ 2362638078 LiftAxle2PosCmd "Signal to command the position / load condition of lift / tag axle #2.";
CM_ SG_ 2362638078 LiftAxle1PosCmd "Signal to command the position/load condition of lift/tag axle #1.";
CM_ BO_ 2365479678 "Air Suspension Control 1";
CM_ SG_ 2365479678 SpeedDependantLevelCtrlStatus "This parameter indicates if the function Speed Dependant Level Control is active.";
CM_ SG_ 2365479678 MemoryLevel "Signal which indicates that the air suspension control has memory levels selected or stored.";
CM_ SG_ 2365479678 AllwLvelCtrlDuringBrakingStatus "This parameter indicates if the function Allow Level Control During Braking is active.";
CM_ SG_ 2365479678 SspensionCtrlRefusalInformation "Signal which indicates that the air suspension control cannot perform a request due to the operating conditions.";
CM_ SG_ 2365479678 SuspensionRemoteCtrl2 "Signal which indicates that the suspension system is controlled by remote control #2.";
CM_ SG_ 2365479678 SuspensionRemoteCtrl1 "Signal which indicates that the suspension system is controlled by remote control #1.";
CM_ SG_ 2365479678 RearAxleInBumperRange "Signal which indicates that the vehicle height at the rear axle (SPNs 1723 and 1724) is within the bumper range.";
CM_ SG_ 2365479678 FrontAxleInBumperRange "Signal which indicates that the vehicle height at the front axle (SPNs 1721 and 1722) is within the bumper range.";
CM_ SG_ 2365479678 DoorRelease "Signal which indicates that the doors may be opened.";
CM_ SG_ 2365479678 VehicleMotionInhibit "Signal which indicates whether vehicle motion is inhibited.";
CM_ SG_ 2365479678 SecurityDevice "The signal which indicates the status of the security device.";
CM_ SG_ 2365479678 LevelCtrlMode "Signal which indicates the actual control mode of the air suspension system";
CM_ SG_ 2365479678 KneelingInformation "Signal which indicates the actual level change in case of kneeling function";
CM_ SG_ 2365479678 LiftingCtrlModeRearAxle "Signal which indicates the actual lifting level change at the rear axle";
CM_ SG_ 2365479678 LiftingCtrlModeFrontAxle "Signal which indicates the actual lifting level change at the front axle";
CM_ SG_ 2365479678 LoweringCtrlModeRearAxle "Signal which indicates the actual lowering level change at the rear axle";
CM_ SG_ 2365479678 LoweringCtrlModeFrontAxle "Signal which indicates the actual lowering level change at the front axle";
CM_ SG_ 2365479678 AboveNominalLevelRearAxle "Signal which indicates whether the actual height of the rear axle is above the nominal (desired) level of the rear axle.";
CM_ SG_ 2365479678 AboveNominalLevelFrontAxle "Signal which indicates whether the actual height of the front axle is above the nominal (desired) level of the front axle.";
CM_ SG_ 2365479678 BelowNominalLevelRearAxle "Signal which indicates whether the actual height of the rear axle is below the nominal (desired) level for the rear axle.";
CM_ SG_ 2365479678 BelowNominalLevelFrontAxle "Signal which indicates whether the actual height of the front axle is below the nominal (desired) level for the front axle.";
CM_ SG_ 2365479678 NominalLevelRearAxle "Signal which indicates the nominal (desired) height of the rear axle to be controlled by the suspension system.";
CM_ SG_ 2365479678 NominalLevelFrontAxle "Signal which indicates the nominal (desired) height of the front axle to be controlled by the suspension system.";
CM_ SG_ 2365479678 LiftAxle2Pos "Signal which indicates the position / load condition of lift axle / tag axle #2.";
CM_ SG_ 2365479678 LiftAxle1Pos "Signal which indicates the position / load condition of lift axle / tag axle #1.";
CM_ BO_ 2566837758 "Alternator Information";
CM_ SG_ 2566837758 Alt4Status "Alternator 4 operating status.";
CM_ SG_ 2566837758 Alt3Status "Alternator 3 operating status.";
CM_ SG_ 2566837758 Alt2Status "Alternator 2 operating status.";
CM_ SG_ 2566837758 Alt1Status "Alternator 1 operating status.";
CM_ SG_ 2566837758 AltSpeed "Actual rotation speed of the alternator.";
CM_ BO_ 2633922558 "Auxiliary Pressures";
CM_ SG_ 2633922558 AuxAbsPressReading "Identifies the current absolute pressure (relative to 0 pressure) that is configured uniquely per application.";
CM_ SG_ 2633922558 AuxGagePressReading1 "Identifies the current gage pressure (relative to atmosphere) that is configured uniquely per application.";
CM_ SG_ 2633922558 AuxVacuumPressReading "Identifies the current vacuum pressure (relative to atmosphere) that is configured uniquely per application.";
CM_ BO_ 2566775038 "Ambient Conditions 2";
CM_ SG_ 2566775038 SpecificHumidity "Specific humidity of the ambient intake air.";
CM_ SG_ 2566775038 SolarSensorMax "This is the maximum value which can be reported by the sensor for the solar intensity.";
CM_ SG_ 2566775038 SolarIntensityPercent "This is the solar radiation (power density) falling on the vehicle in percent of the maximum sensor value (SPN 2611).";
CM_ BO_ 2566836478 "Test results for non-continously monitored systems.";
CM_ SG_ 2566836478 TestLimitMinimum "The threshold which the test value must be above to pass the test.";
CM_ SG_ 2566836478 TestLimitMaximum "The threshold which the test value must be below to pass the test.";
CM_ SG_ 2566836478 TestValue "The test value collected during the test.";
CM_ SG_ 2566836478 TestType "Identifies the non-continously monitored component identifier that was tested.";
CM_ SG_ 2566836478 TestIdentifier "Designates the test to be run.";
CM_ BO_ 2565078782 "Command non-continously monitored test";
CM_ SG_ 2565078782 SPN1High "SPN #1 (Conversion Version 4)";
CM_ SG_ 2565078782 SPN1 "SPN #1 (Conversion Version 4)";
CM_ SG_ 2565078782 TestIdentifier "Designates the test to be run.";
CM_ SG_ 2565078782 FailureModeIdentifier1 "The FMI defines the type of failure detected in the subsystem identified by an SPN.";
CM_ BO_ 2566836222 "Pending DTCs";
CM_ SG_ 2566836222 FlashRedStopLamp "This parameter provides the capability to flash the RSL (SPN 3039).";
CM_ SG_ 2566836222 FlashProtectLamp "This parameter provides the capability to flash the engine protect lamp (SPN 3041).";
CM_ SG_ 2566836222 FlashMalfuncIndicatorLamp "This parameter provides the capability to flash the MIL (SPN 3038).";
CM_ SG_ 2566836222 FlashAmberWarningLamp "This parameter provides the capability to flash the AWL (SPN 3040). ";
CM_ SG_ 2566836222 MalfunctionIndicatorLampStatus "A lamp used to relay only emissions-related trouble code information.";
CM_ SG_ 2566836222 RedStopLampState "This lamp is uesed to relay trouble code information that is of a severe enought condition that it warrants stopping the vehicle.";
CM_ SG_ 2566836222 DTC5 "Diagnostic Trouble Code";
CM_ SG_ 2566836222 DTC4 "Diagnostic Trouble Code";
CM_ SG_ 2566836222 DTC3 "Diagnostic Trouble Code";
CM_ SG_ 2566836222 DTC2 "Diagnostic Trouble Code";
CM_ SG_ 2566836222 DTC1 "Diagnostic Trouble Code";
CM_ BO_ 2566835966 "Diagnostic readiness 1";
CM_ SG_ 2566835966 OBDCompliance "Identifies the OBD compliance capabilityof the responding controller.";
CM_ SG_ 2566835966 PreviouslyActiveTroubleCodes "Identifies the number of previously active trouble codes that are present in a specific controller.";
CM_ SG_ 2566835966 ActiveTroubleCodes "Identifies the number of active trouble codes that are present in a specific controller.";
CM_ BO_ 2566835710 "Freeze frame parameters";
CM_ SG_ 2566835710 EngIntakeManifold1Press "The gage pressure measurement of the air intake manifold.";
CM_ SG_ 2566835710 EngSpeed "Actual engine speed which is calculated over a minimum crankshaft angle of 720 degrees divided by the number of cylinders.";
CM_ SG_ 2566835710 EngTorqueMode "State signal which indicates which engine torque mode is currently generating, limiting, or controlling the torque.";
CM_ SG_ 2566835710 WheelBasedVehicleSpeed "Speed of the vehicle as calculated from wheel or tailshaft speed.";
CM_ SG_ 2566835710 EngPercentLoadAtCurrentSpeed "The ratio of actual engine percent torque (indicated) to maximum indicated torque available at the current engine speed,";
CM_ SG_ 2566835710 DTC1 "Diagnostic Trouble Code";
CM_ BO_ 2566835454 "Diagnostic data clear/reset of previously active DTCs.";
CM_ BO_ 2566764542 "Expanded freeze frame.";
CM_ SG_ 2566764542 DTC1 "Diagnostic Trouble Code";
CM_ BO_ 2566764286 "SPN Support. This message is used to identify those SPNs supported by the product for freeze frames and data stream messages.";
CM_ SG_ 2566764286 SPNSupported1High "This parameter defines the SPN(s) that is/are supported for the freeze frame and/or data stream information.";
CM_ SG_ 2566764286 SPNSupportTypeSTR3 "This parameter defines whether the applicable parameter (that is the SPN) is supported in the freeze frame, the data stream or both the freeze frame and data stream.";
CM_ SG_ 2566764286 SPNSupportTypeSTR2 "This parameter defines whether the applicable parameter (that is the SPN) is supported in the freeze frame, the data stream or both the freeze frame and data stream.";
CM_ SG_ 2566764286 SPNSupportTypeEFF3 "This parameter defines whether the applicable parameter (that is the SPN) is supported in the freeze frame, the data stream or both the freeze frame and data stream.";
CM_ SG_ 2566764286 SPNSupportTypeEFF2 "This parameter defines whether the applicable parameter (that is the SPN) is supported in the freeze frame, the data stream or both the freeze frame and data stream.";
CM_ SG_ 2566764286 SPNSupportTypeDS3 "This parameter defines whether the applicable parameter (that is the SPN) is supported in the freeze frame, the data stream or both the freeze frame and data stream.";
CM_ SG_ 2566764286 SPNSupportTypeDS2 "This parameter defines whether the applicable parameter (that is the SPN) is supported in the freeze frame, the data stream or both the freeze frame and data stream.";
CM_ SG_ 2566764286 SPNSupported3High "This parameter defines the SPN(s) that is/are supported for the freeze frame and/or data stream information.";
CM_ SG_ 2566764286 SPNSupported2High "This parameter defines the SPN(s) that is/are supported for the freeze frame and/or data stream information.";
CM_ SG_ 2566764286 SPNSupported3 "This parameter defines the SPN(s) that is/are supported for the freeze frame and/or data stream information.";
CM_ SG_ 2566764286 SPNSupported2 "This parameter defines the SPN(s) that is/are supported for the freeze frame and/or data stream information.";
CM_ SG_ 2566764286 SPNDataLength3 "The number of data bytes associated with the SPN in the Freeze Frame.";
CM_ SG_ 2566764286 SPNSupportTypeSTR1 "This parameter defines whether the applicable parameter (that is the SPN) is supported in the freeze frame, the data stream or both the freeze frame and data stream.";
CM_ SG_ 2566764286 SPNSupportTypeDS1 "This parameter defines whether the applicable parameter (that is the SPN) is supported in the freeze frame, the data stream or both the freeze frame and data stream.";
CM_ SG_ 2566764286 SPNSupportTypeEFF1 "This parameter defines whether the applicable parameter (that is the SPN) is supported in the freeze frame, the data stream or both the freeze frame and data stream.";
CM_ SG_ 2566764286 SPNDataLength2 "The number of data bytes associated with the SPN in the Freeze Frame.";
CM_ SG_ 2566764286 SPNDataLength1 "The number of data bytes associated with the SPN in the Freeze Frame.";
CM_ SG_ 2566764286 SPNSupported1 "This parameter defines the SPN(s) that is/are supported for the freeze frame and/or data stream information.";
CM_ BO_ 2566764030 "Previously active emission related faults.";
CM_ SG_ 2566764030 FlashRedStopLamp "This parameter provides the capability to flash the RSL (SPN 3039).";
CM_ SG_ 2566764030 FlashProtectLamp "This parameter provides the capability to flash the engine protect lamp (SPN 3041).";
CM_ SG_ 2566764030 FlashMalfuncIndicatorLamp "This parameter provides the capability to flash the MIL (SPN 3038).";
CM_ SG_ 2566764030 FlashAmberWarningLamp "This parameter provides the capability to flash the AWL (SPN 3040). ";
CM_ SG_ 2566764030 MalfunctionIndicatorLampStatus "A lamp used to relay only emissions-related trouble code information.";
CM_ SG_ 2566764030 RedStopLampState "This lamp is uesed to relay trouble code information that is of a severe enought condition that it warrants stopping the vehicle.";
CM_ SG_ 2566764030 DTC5 "Diagnostic Trouble Code";
CM_ SG_ 2566764030 DTC4 "Diagnostic Trouble Code";
CM_ SG_ 2566764030 DTC3 "Diagnostic Trouble Code";
CM_ SG_ 2566764030 DTC2 "Diagnostic Trouble Code";
CM_ SG_ 2566764030 DTC1 "Diagnostic Trouble Code";
CM_ BO_ 2562981630 "Individual Clear/Reset of active and previously active DTC.";
CM_ SG_ 2562981630 SPN1 "SPN #1 (Conversion Version 4)";
CM_ SG_ 2562981630 SPN1High "SPN #1 (Conversion Version 4)";
CM_ SG_ 2562981630 FailureModeIdentifier1 "The FMI defines the type of failure detected in the subsystem identified by an SPN.";
CM_ BO_ 2562850558 "Diagnostic readiness 2";
CM_ SG_ 2562850558 TimeSinceDTCsCleared "Time accumulated since DTCs were cleared (via an external test equipment or possibly, a battery disconnect) (SPN=?).";
CM_ SG_ 2562850558 MinutesRunByEngineMILActivated "Accumulated count (in minutes) while the MIL is activated (on) (SPN=?).";
CM_ SG_ 2562850558 DistanceSinceDTCsCleared "Distance accumulated since DTCs were cleared (SPN=?).";
CM_ SG_ 2562850558 DistanceWhileMILisActivated "The kilometers accumulated while the MIL is activated (SPN 3060).";
CM_ BO_ 2562916094 "Monitor Performance Ratio";
CM_ SG_ 2562916094 ApplSysMonitorDenominator "The number of times a vehicle has been operated that constitutes a driving cycle where this Applicable System Monitor could be operated per regulatory requirements (SPN 3068).";
CM_ SG_ 2562916094 ApplSysMonitorNumerator "The number of times a vehicle has been operated such that all conditions necessary for the Applicable System Monitor to detect a malfunction have been encountered (SPN 3067).";
CM_ SG_ 2562916094 SPNofApplSysMonitor "Contain the SPN of the system monitor for which Monitor ratio is being reported (SPN 3066).";
CM_ SG_ 2562916094 OBDMonitoringCondEncountered "Displays the number of times that the vehicle has been operated in the specified OBD monitoring conditions (SPN 3049).";
CM_ SG_ 2562916094 IgnitionCycleCounter "A single counter that defines the number of ignition cycles (SPN 3048).";
CM_ BO_ 2566835198 "Previously active diagnostic trouble codes";
CM_ SG_ 2566835198 MalfunctionIndicatorLampStatus "A lamp used to relay only emissions-related trouble code information.";
CM_ SG_ 2566835198 RedStopLampState "This lamp is uesed to relay trouble code information that is of a severe enought condition that it warrants stopping the vehicle.";
CM_ SG_ 2566835198 FlashRedStopLamp "This parameter provides the capability to flash the RSL (SPN 3039).";
CM_ SG_ 2566835198 FlashProtectLamp "This parameter provides the capability to flash the engine protect lamp (SPN 3041).";
CM_ SG_ 2566835198 FlashMalfuncIndicatorLamp "This parameter provides the capability to flash the MIL (SPN 3038).";
CM_ SG_ 2566835198 FlashAmberWarningLamp "This parameter provides the capability to flash the AWL (SPN 3040). ";
CM_ SG_ 2566835198 DTC5 "Diagnostic Trouble Code";
CM_ SG_ 2566835198 DTC4 "Diagnostic Trouble Code";
CM_ SG_ 2566835198 DTC3 "Diagnostic Trouble Code";
CM_ SG_ 2566835198 DTC2 "Diagnostic Trouble Code";
CM_ SG_ 2566835198 DTC1 "Diagnostic Trouble Code";
CM_ BO_ 2564030206 "Calibration Information";
CM_ BO_ 2564226814 "Boot Load Data";
CM_ BO_ 2564292350 "Binary Data Transfer";
CM_ SG_ 2564292350 NumberOfOccurance "Number of occurance of raw binary data";
CM_ BO_ 2564357886 "Memory Access Response";
CM_ SG_ 2564357886 ErrorIndicator "Error Indicator/EDC Parameter";
CM_ BO_ 2564423422 "Memory Access Request";
CM_ SG_ 2564423422 KeyOrUserLevel "Key/User Level";
CM_ SG_ 2564423422 NumberRequested "Length/Number Requested";
CM_ SG_ 2564423422 NumberRequestedHigh "Length/Number Requested";
CM_ BO_ 2564816638 "Stop start broadcast";
CM_ SG_ 2564816638 J1939Network3 "Identifies the action to be performed on the SAE J1939 Network #3.";
CM_ SG_ 2564816638 J1939Network2 "Identifies the action to be performed on the SAE J1939 Network #2.";
CM_ SG_ 2564816638 ISO9141 "Identifies the action to be performed on the ISO9141 communications port.";
CM_ SG_ 2564816638 SAE_J1850 "Identifies the action to be performed on the SAE J1850 communications port.";
CM_ SG_ 2564816638 ManufacturerSpecificPort "Identifies the action to be performed on 'Other, manufacturer specific port' communications port.";
CM_ SG_ 2564816638 CurrentDataLink "Identifies the action to be performed on the communications port that this parameter was received.";
CM_ SG_ 2564816638 SAE_J1587 "Identifies the action to be performed on the SAE J1587 communications port.";
CM_ SG_ 2564816638 SAE_J1922 "Identifies the action to be performed on the SAE J1922 communications port.";
CM_ SG_ 2564816638 J1939Network1 "Identifies the action to be performed on the SAE J1939 Network #1, Primary vehicle communications port.";
CM_ BO_ 2566837502 "Emissions-related active diagnostic trouble codes.";
CM_ SG_ 2566837502 FlashRedStopLamp "This parameter provides the capability to flash the RSL (SPN 3039).";
CM_ SG_ 2566837502 FlashProtectLamp "This parameter provides the capability to flash the engine protect lamp (SPN 3041).";
CM_ SG_ 2566837502 MalfunctionIndicatorLampStatus "A lamp used to relay only emissions-related trouble code information.";
CM_ SG_ 2566837502 RedStopLampState "This lamp is uesed to relay trouble code information that is of a severe enought condition that it warrants stopping the vehicle.";
CM_ SG_ 2566837502 FlashMalfuncIndicatorLamp "This parameter provides the capability to flash the MIL (SPN 3038).";
CM_ SG_ 2566837502 FlashAmberWarningLamp "This parameter provides the capability to flash the AWL (SPN 3040). ";
CM_ SG_ 2566837502 DTC5 "Diagnostic Trouble Code";
CM_ SG_ 2566837502 DTC4 "Diagnostic Trouble Code";
CM_ SG_ 2566837502 DTC3 "Diagnostic Trouble Code";
CM_ SG_ 2566837502 DTC2 "Diagnostic Trouble Code";
CM_ SG_ 2566837502 DTC1 "Diagnostic Trouble Code";
CM_ BO_ 2566837246 "Diagnostic data clear/Reset for active DTCs";
CM_ BO_ 2566836990 "Non-continously monitored systems test identifiers support";
CM_ SG_ 2566836990 TestIdentifierSupported "Indicates the test identifiers that the controller supports.";
CM_ BO_ 2566834942 "Active diagnostic trouble codes";
CM_ SG_ 2566834942 FlashRedStopLamp "This parameter provides the capability to flash the RSL (SPN 3039).";
CM_ SG_ 2566834942 FlashProtectLamp "This parameter provides the capability to flash the engine protect lamp (SPN 3041).";
CM_ SG_ 2566834942 FlashMalfuncIndicatorLamp "This parameter provides the capability to flash the MIL (SPN 3038).";
CM_ SG_ 2566834942 FlashAmberWarningLamp "This parameter provides the capability to flash the AWL (SPN 3040). ";
CM_ SG_ 2566834942 MalfunctionIndicatorLampStatus "A lamp used to relay only emissions-related trouble code information.";
CM_ SG_ 2566834942 RedStopLampState "This lamp is uesed to relay trouble code information that is of a severe enought condition that it warrants stopping the vehicle.";
CM_ SG_ 2566834942 DTC5 "Diagnostic Trouble Code";
CM_ SG_ 2566834942 DTC4 "Diagnostic Trouble Code";
CM_ SG_ 2566834942 DTC3 "Diagnostic Trouble Code";
CM_ SG_ 2566834942 DTC2 "Diagnostic Trouble Code";
CM_ SG_ 2566834942 DTC1 "Diagnostic Trouble Code";
CM_ BO_ 2566780926 "Utility Total AC Reactive Power";
CM_ SG_ 2566780926 UtlityOverallPowerFactorLagging "Lead/lag status for utility incomer average power factor.";
CM_ SG_ 2566780926 UtilityOverallPowerFactor "The average power factor of the utility incomer.";
CM_ SG_ 2566780926 UtilityTotalReactivePower "The total reactive power delivered by the utility incomer";
CM_ BO_ 2566781182 "Utility Total AC Power";
CM_ SG_ 2566781182 UtilityTotalApparentPower "The total apparent power delivered by the utility incomer.";
CM_ SG_ 2566781182 UtilityTotalRealPower "Total real power delivered by the utility incomer.";
CM_ BO_ 2566778366 "Utility Total AC Energy";
CM_ SG_ 2566778366 UtilityTotalKWHoursImport "The total kilowatt-hours that have been imported by the utility incomer.";
CM_ SG_ 2566778366 UtilityTotalKWHoursExport "The total kilowatt-hours that have been exported by the utility incomer.";
CM_ BO_ 2566778622 "Utility Phase C AC Reactive Power";
CM_ SG_ 2566778622 UtilityPhaseCPowerFactorLagging "Lead/lag status for utility incomer phase C power factor.";
CM_ SG_ 2566778622 UtilityPhaseCPowerFactor "The power factor of phases C of the utility incomer.";
CM_ SG_ 2566778622 UtilityPhaseCReactivePower "The reactive power delivered by phase C of the utility incomer";
CM_ BO_ 2566778878 "Utility Phase C AC Power";
CM_ SG_ 2566778878 UtilityPhaseCApparentPower "The apparent power delivered by phase C of the utility incomer.";
CM_ SG_ 2566778878 UtilityPhaseCRealPower "The real power delivered by phase C of the utility incomer.";
CM_ BO_ 2566779134 "Utility Phase C AC Basic Quantities";
CM_ SG_ 2566779134 UtilityPhaseCACRMSCurrent "RMS current measured at the utility incomer phase C.";
CM_ SG_ 2566779134 UtilityPhaseCACFrequency "AC frequency measured at the utility incomer phase C.";
CM_ SG_ 2566779134 UtltyPhsCLneNeutralACRMSVoltage "Line to Neutral RMS voltage measured at the utility incomer phase C.";
CM_ SG_ 2566779134 UtltyPhseCALineLineACRMSVoltage "Line to Line RMS voltage measured at the utility incomer phase CA.";
CM_ BO_ 2566779390 "Utility Phase B AC Reactive Power";
CM_ SG_ 2566779390 UtilityPhaseBPowerFactorLagging "Lead/lag status for utility incomer phase B power factor.";
CM_ SG_ 2566779390 UtilityPhaseBPowerFactor "The power factor of phases B of the utility incomer.";
CM_ SG_ 2566779390 UtilityPhaseBReactivePower "The reactive power delivered by phase B of the utility incomer";
CM_ BO_ 2566779646 "Utility Phase B AC Power";
CM_ SG_ 2566779646 UtilityPhaseBApparentPower "The apparent power delivered by phase B of the utility incomer.";
CM_ SG_ 2566779646 UtilityPhaseBRealPower "The real power delivered by phase B of the utility incomer.";
CM_ BO_ 2566779902 "Utility Phase B AC Basic Quantities";
CM_ SG_ 2566779902 UtilityPhaseBACRMSCurrent "RMS current measured at the utility incomer phase B.";
CM_ SG_ 2566779902 UtilityPhaseBACFrequency "AC frequency measured at the utility incomer phase B.";
CM_ SG_ 2566779902 UtltyPhsBLneNeutralACRMSVoltage "Line to Neutral RMS voltage measured at the utility incomer phase B.";
CM_ SG_ 2566779902 UtltyPhseBCLineLineACRMSVoltage "Line to Line RMS voltage measured at the utility incomer phase BC.";
CM_ BO_ 2566780158 "Utility Phase A AC Reactive Power";
CM_ SG_ 2566780158 UtilityPhaseAPowerFactorLagging "Lead/lag status for utility incomer phase A power factor.";
CM_ SG_ 2566780158 UtilityPhaseAPowerFactor "The power factor of phase A of the utility incomer.";
CM_ SG_ 2566780158 UtilityPhaseAReactivePower "The reactive power delivered by phase A of the utility incomer";
CM_ BO_ 2566780414 "Utility Phase A AC Power";
CM_ SG_ 2566780414 UtilityPhaseAApparentPower "The apparent power delivered by phase A of the utility incomer.";
CM_ SG_ 2566780414 UtilityPhaseARealPower "The real power delivered by phase A of the utility incomer.";
CM_ BO_ 2566780670 "Utility Phase A Basic AC Quantities";
CM_ SG_ 2566780670 UtilityPhaseAACRMSCurrent "RMS current measured at the utility incomer phase A.";
CM_ SG_ 2566780670 UtilityPhaseAACFrequency "AC frequency measured at the utility incomer phase A.";
CM_ SG_ 2566780670 UtltyPhsALneNeutralACRMSVoltage "Line to Neutral RMS voltage measured at the utility incomer phase A.";
CM_ SG_ 2566780670 UtltyPhseABLineLineACRMSVoltage "Line to Line RMS voltage measured at the utility incomer phase AB.";
CM_ BO_ 2566781438 "Utility Average Basic AC Quantities";
CM_ SG_ 2566781438 UtilityAverageACRMSCurrent "Average RMS current measured at the utility incomer.";
CM_ SG_ 2566781438 UtilityAverageACFrequency "Average AC frequency measured at the utility incomer.";
CM_ SG_ 2566781438 UtltyAvrgLneNeutralACRMSVoltage "The average Line to Neutral AC RMS voltage measured at the utility incomer .";
CM_ SG_ 2566781438 UtltyAvrageLineLineACRMSVoltage "Average Line to Line RMS voltage measured at the utility incomer .";
CM_ BO_ 2566784254 "Generator Total AC Reactive Power";
CM_ SG_ 2566784254 GnrtorOverallPowerFactorLagging "Lead/lag status for generator average power factor.";
CM_ SG_ 2566784254 GeneratorOverallPowerFactor "The average power factor of the generator.";
CM_ SG_ 2566784254 GeneratorTotalReactivePower "The total reactive power delivered by the generator";
CM_ BO_ 2566784510 "Generator Total AC Power";
CM_ SG_ 2566784510 GeneratorTotalApparentPower "The total apparent power delivered by the generator.";
CM_ SG_ 2566784510 GeneratorTotalRealPower "Total real power delivered by the generator.";
CM_ BO_ 2566781694 "Generator Total AC Energy";
CM_ SG_ 2566781694 GeneratorTotalKWHoursImport "The total kilowatt-hours that have been imported by the generator.";
CM_ SG_ 2566781694 GeneratorTotalKWHoursExport "The total kilowatt-hours that have been exported by the generator.";
CM_ BO_ 2566781950 "Generator Phase C AC Reactive Power";
CM_ SG_ 2566781950 GnratorPhaseCPowerFactorLagging "Lead/lag status for generator phase C power factor.";
CM_ SG_ 2566781950 GeneratorPhaseCPowerFactor "The power factor of phases C of the generator.";
CM_ SG_ 2566781950 GeneratorPhaseCReactivePower "The reactive power delivered by phase C of the generator";
CM_ BO_ 2566782206 "Generator Phase C AC Power";
CM_ SG_ 2566782206 GeneratorPhaseCApparentPower "The apparent power delivered by phase C of the generator.";
CM_ SG_ 2566782206 GeneratorPhaseCRealPower "The real power delivered by phase C of the generator.";
CM_ BO_ 2566782462 "Generator Phase C Basic AC Quantities";
CM_ SG_ 2566782462 GeneratorPhaseCACRMSCurrent "RMS current measured at the generator phase C output.";
CM_ SG_ 2566782462 GeneratorPhaseCACFrequency "AC frequency measured at the generator phase C output.";
CM_ SG_ 2566782462 GnrtrPhsCLneNeutralACRMSVoltage "Line to Neutral RMS voltage measured at the generator phase C output.";
CM_ SG_ 2566782462 GnrtrPhseCALineLineACRMSVoltage "Line to Line RMS voltage measured at the generator phase CA output.";
CM_ BO_ 2566782718 "Generator Phase B AC Reactive Power";
CM_ SG_ 2566782718 GnratorPhaseBPowerFactorLagging "Lead/lag status for generator phase B power factor.";
CM_ SG_ 2566782718 GeneratorPhaseBPowerFactor "The power factor of phases B of the generator.";
CM_ SG_ 2566782718 GeneratorPhaseBReactivePower "The reactive power delivered by phase B of the generator";
CM_ BO_ 2566782974 "Generator Phase B AC Power";
CM_ SG_ 2566782974 GeneratorPhaseBApparentPower "The apparent power delivered by phase B of the generator.";
CM_ SG_ 2566782974 GeneratorPhaseBRealPower "The real power delivered by phase B of the generator.";
CM_ BO_ 2566783230 "Generator Phase B Basic AC Quantities";
CM_ SG_ 2566783230 GeneratorPhaseBACRMSCurrent "RMS current measured at the generator phase B output.";
CM_ SG_ 2566783230 GeneratorPhaseBACFrequency "AC frequency measured at the generator phase B output.";
CM_ SG_ 2566783230 GnrtrPhsBLneNeutralACRMSVoltage "Line to Neutral RMS voltage measured at the generator phase B output.";
CM_ SG_ 2566783230 GnrtrPhseBCLineLineACRMSVoltage "Line to Line RMS voltage measured at the generator phase BC output.";
BA_DEF_ SG_ "SigType" ENUM "Default","Range","RangeSigned","ASCII","Discrete","Control","ReferencePGN","DTC","StringDelimiter","StringLength","StringLengthControl";
BA_DEF_ SG_ "GenSigStartValue" INT 0 10000;
BA_DEF_ SG_ "GenSigSendType" ENUM "Default","Range","RangeSigned","ASCII","Discrete","Control","ReferencePGN","DTC","StringDelimiter","StringLength","StringLengthControl","Cyclic","OnWrite","reserved","OnChange","reserved","reserved","reserved","NoSigSendType";
BA_DEF_ SG_ "GenSigILSupport" ENUM "Default","Range","RangeSigned","ASCII","Discrete","Control","ReferencePGN","DTC","StringDelimiter","StringLength","StringLengthControl","Cyclic","OnWrite","reserved","OnChange","reserved","reserved","reserved","NoSigSendType","Yes","No";
BA_DEF_ SG_ "GenSigEVName" STRING ;
BA_DEF_ SG_ "SPN" INT 0 524287;
BA_DEF_ BO_ "GenMsgStartDelayTime" INT 0 100000;
BA_DEF_ BO_ "GenMsgILSupport" ENUM "Default","Range","RangeSigned","ASCII","Discrete","Control","ReferencePGN","DTC","StringDelimiter","StringLength","StringLengthControl","Cyclic","OnWrite","reserved","OnChange","reserved","reserved","reserved","NoSigSendType","Yes","No","Yes","No";
BA_DEF_ BO_ "GenMsgRequestable" INT 0 1;
BA_DEF_ BO_ "GenMsgSendType" ENUM "Default","Range","RangeSigned","ASCII","Discrete","Control","ReferencePGN","DTC","StringDelimiter","StringLength","StringLengthControl","Cyclic","OnWrite","reserved","OnChange","reserved","reserved","reserved","NoSigSendType","Yes","No","Yes","No","cyclic","reserved","cyclicIfActive","reserved","reserved","reserved","reserved","reserved","noMsgSendType";
BA_DEF_ BO_ "VFrameFormat" ENUM "Default","Range","RangeSigned","ASCII","Discrete","Control","ReferencePGN","DTC","StringDelimiter","StringLength","StringLengthControl","Cyclic","OnWrite","reserved","OnChange","reserved","reserved","reserved","NoSigSendType","Yes","No","Yes","No","cyclic","reserved","cyclicIfActive","reserved","reserved","reserved","reserved","reserved","noMsgSendType","StandardCAN","ExtendedCAN","reserved","J1939PG";
BA_DEF_ BO_ "GenMsgCycleTime" INT 0 3.6e+06;
BA_DEF_ SG_ "SystemSignalLongSymbol" STRING ;
BA_DEF_ BO_ "GenMsgBackgroundColor" STRING ;
BA_DEF_ BO_ "GenMsgForegroundColor" STRING ;
BA_DEF_ BO_ "matchingcriteria" INT 0 0;
BA_DEF_ BO_ "filterlabeling" INT 0 0;
BA_DEF_DEF_ "SigType" "Default";
BA_DEF_DEF_ "GenSigStartValue" 0;
BA_DEF_DEF_ "GenSigSendType" "NoSigSendType";
BA_DEF_DEF_ "GenSigILSupport" "Yes";
BA_DEF_DEF_ "GenSigEVName" "Env";
BA_DEF_DEF_ "SPN" 0;
BA_DEF_DEF_ "GenMsgStartDelayTime" 0;
BA_DEF_DEF_ "GenMsgILSupport" "Yes";
BA_DEF_DEF_ "GenMsgRequestable" 1;
BA_DEF_DEF_ "GenMsgSendType" "noMsgSendType";
BA_DEF_DEF_ "VFrameFormat" "J1939PG";
BA_DEF_DEF_ "GenMsgCycleTime" 0;
BA_DEF_DEF_ "SystemSignalLongSymbol" "";
BA_DEF_DEF_ "GenMsgBackgroundColor" "#ffffff";
BA_DEF_DEF_ "GenMsgForegroundColor" "#000000";
BA_DEF_DEF_ "matchingcriteria" 1;
BA_DEF_DEF_ "filterlabeling" 1;
BA_ "VFrameFormat" BO_ 2566742270 3;
BA_ "VFrameFormat" BO_ 2566742526 3;
BA_ "VFrameFormat" BO_ 2566742782 3;
BA_ "VFrameFormat" BO_ 2566743038 3;
BA_ "VFrameFormat" BO_ 2566743294 3;
BA_ "VFrameFormat" BO_ 2560687870 3;
BA_ "VFrameFormat" BO_ 2292317950 3;
BA_ "GenMsgCycleTime" BO_ 2566809342 1000;
BA_ "GenMsgSendType" BO_ 2566809342 0;
BA_ "VFrameFormat" BO_ 2566809342 3;
BA_ "GenMsgCycleTime" BO_ 2365446910 100;
BA_ "GenMsgSendType" BO_ 2365446910 0;
BA_ "VFrameFormat" BO_ 2365446910 3;
BA_ "GenMsgCycleTime" BO_ 2365446398 100;
BA_ "GenMsgSendType" BO_ 2365446398 0;
BA_ "VFrameFormat" BO_ 2365446398 3;
BA_ "GenMsgCycleTime" BO_ 2365445886 100;
BA_ "GenMsgSendType" BO_ 2365445886 0;
BA_ "VFrameFormat" BO_ 2365445886 3;
BA_ "GenMsgCycleTime" BO_ 2566847230 1000;
BA_ "GenMsgSendType" BO_ 2566847230 0;
BA_ "VFrameFormat" BO_ 2566847230 3;
BA_ "GenMsgCycleTime" BO_ 2566848254 1000;
BA_ "GenMsgSendType" BO_ 2566848254 0;
BA_ "VFrameFormat" BO_ 2566848254 3;
BA_ "GenMsgCycleTime" BO_ 2566725886 500;
BA_ "GenMsgSendType" BO_ 2566725886 0;
BA_ "VFrameFormat" BO_ 2566725886 3;
BA_ "SystemSignalLongSymbol" SG_ 2566725886 Aftrtrtmnt1DslOxdtnCtlystDf_0000 "Aftrtrtmnt1DslOxdtnCtlystDf_0000";
BA_ "SystemSignalLongSymbol" SG_ 2566725886 Aftrtrtmnt1DslOxdtnCtlystOtltGsT "Aftrtrtmnt1DslOxdtnCtlystOtltGsT";
BA_ "SystemSignalLongSymbol" SG_ 2566725886 Aftrtrtmnt1DslOxdtnCtlystIntkGsT "Aftrtrtmnt1DslOxdtnCtlystIntkGsT";
BA_ "SystemSignalLongSymbol" SG_ 2566725886 Aftrtrtmnt1DslOxdtnCtlystOt_0000 "Aftrtrtmnt1DslOxdtnCtlystOt_0000";
BA_ "SystemSignalLongSymbol" SG_ 2566725886 Aftrtrtmnt1DslOxdtnCtlystIn_0000 "Aftrtrtmnt1DslOxdtnCtlystIn_0000";
BA_ "VFrameFormat" BO_ 2560884478 3;
BA_ "VFrameFormat" BO_ 2633844734 3;
BA_ "VFrameFormat" BO_ 2560360190 3;
BA_ "VFrameFormat" BO_ 2566736126 3;
BA_ "SystemSignalLongSymbol" SG_ 2566736126 EngExhstGsOxygnSnsrClsdLpOprtnBn "EngExhstGsOxygnSnsrClsdLpOprtnBn";
BA_ "VFrameFormat" BO_ 2566736382 3;
BA_ "SystemSignalLongSymbol" SG_ 2566736382 EngExhstGsOxygnSnsrClsdLpOp_0000 "EngExhstGsOxygnSnsrClsdLpOp_0000";
BA_ "VFrameFormat" BO_ 2565874174 3;
BA_ "GenMsgCycleTime" BO_ 2432520958 1000;
BA_ "VFrameFormat" BO_ 2432520958 3;
BA_ "VFrameFormat" BO_ 2560425726 3;
BA_ "VFrameFormat" BO_ 2560491262 3;
BA_ "VFrameFormat" BO_ 2349399806 3;
BA_ "GenMsgCycleTime" BO_ 2566758398 500;
BA_ "GenMsgSendType" BO_ 2566758398 0;
BA_ "VFrameFormat" BO_ 2566758398 3;
BA_ "GenMsgCycleTime" BO_ 2566745598 500;
BA_ "GenMsgSendType" BO_ 2566745598 0;
BA_ "VFrameFormat" BO_ 2566745598 3;
BA_ "GenMsgCycleTime" BO_ 2566758910 500;
BA_ "GenMsgSendType" BO_ 2566758910 0;
BA_ "VFrameFormat" BO_ 2566758910 3;
BA_ "GenMsgCycleTime" BO_ 2566743550 500;
BA_ "GenMsgSendType" BO_ 2566743550 0;
BA_ "VFrameFormat" BO_ 2566743550 3;
BA_ "GenMsgCycleTime" BO_ 2566753534 500;
BA_ "GenMsgSendType" BO_ 2566753534 0;
BA_ "VFrameFormat" BO_ 2566753534 3;
BA_ "VFrameFormat" BO_ 2566756606 3;
BA_ "SystemSignalLongSymbol" SG_ 2566756606 Aftrtrtmnt1TtlNmbrOfActvRgnrtnMn "Aftrtrtmnt1TtlNmbrOfActvRgnrtnMn";
BA_ "SystemSignalLongSymbol" SG_ 2566756606 Aftrtrtmnt1TtlNmbrOfActvRgnrtnIn "Aftrtrtmnt1TtlNmbrOfActvRgnrtnIn";
BA_ "GenMsgCycleTime" BO_ 2565869310 50;
BA_ "GenMsgSendType" BO_ 2565869310 0;
BA_ "VFrameFormat" BO_ 2565869310 3;
BA_ "SystemSignalLongSymbol" SG_ 2565869310 Aftrtrtmnt1IntkOxygnSnsrPrlmnryF "Aftrtrtmnt1IntkOxygnSnsrPrlmnryF";
BA_ "SystemSignalLongSymbol" SG_ 2565869310 Aftrtrtmnt1IntkGsSnsrHtrPrlmnryF "Aftrtrtmnt1IntkGsSnsrHtrPrlmnryF";
BA_ "GenMsgCycleTime" BO_ 2566763774 500;
BA_ "GenMsgSendType" BO_ 2566763774 0;
BA_ "VFrameFormat" BO_ 2566763774 3;
BA_ "SystemSignalLongSymbol" SG_ 2566763774 Aftrtrtmnt1DslPrtcltFltrIntkGsTm "Aftrtrtmnt1DslPrtcltFltrIntkGsTm";
BA_ "SystemSignalLongSymbol" SG_ 2566763774 Aftrtrtmnt1DslPrtcltFltrInt_0000 "Aftrtrtmnt1DslPrtcltFltrInt_0000";
BA_ "GenMsgSendType" BO_ 2631728894 8;
BA_ "VFrameFormat" BO_ 2631728894 3;
BA_ "GenMsgSendType" BO_ 2631794430 8;
BA_ "VFrameFormat" BO_ 2631794430 3;
BA_ "GenMsgCycleTime" BO_ 2633934846 1000;
BA_ "GenMsgSendType" BO_ 2633934846 0;
BA_ "VFrameFormat" BO_ 2633934846 3;
BA_ "GenMsgCycleTime" BO_ 2362572542 100;
BA_ "GenMsgSendType" BO_ 2362572542 2;
BA_ "VFrameFormat" BO_ 2362572542 3;
BA_ "GenMsgCycleTime" BO_ 2365478910 100;
BA_ "GenMsgSendType" BO_ 2365478910 0;
BA_ "VFrameFormat" BO_ 2365478910 3;
BA_ "VFrameFormat" BO_ 2560950014 3;
BA_ "GenMsgCycleTime" BO_ 2566763262 500;
BA_ "GenMsgSendType" BO_ 2566763262 0;
BA_ "VFrameFormat" BO_ 2566763262 3;
BA_ "SystemSignalLongSymbol" SG_ 2566763262 Aftrtrtmnt1DslPrtcltFltrIntrmdtG "Aftrtrtmnt1DslPrtcltFltrIntrmdtG";
BA_ "SystemSignalLongSymbol" SG_ 2566763262 Aftrtrtmnt1DslPrtcltFltrInt_0001 "Aftrtrtmnt1DslPrtcltFltrInt_0001";
BA_ "SystemSignalLongSymbol" SG_ 2566763262 Aftrtrtmnt1DslPrtcltFltrDltPrssP "Aftrtrtmnt1DslPrtcltFltrDltPrssP";
BA_ "GenMsgCycleTime" BO_ 2565869566 50;
BA_ "GenMsgSendType" BO_ 2565869566 0;
BA_ "VFrameFormat" BO_ 2565869566 3;
BA_ "SystemSignalLongSymbol" SG_ 2565869566 Aftrtrtmnt1OtltOxygnSnsrPrlmnryF "Aftrtrtmnt1OtltOxygnSnsrPrlmnryF";
BA_ "SystemSignalLongSymbol" SG_ 2565869566 Aftrtrtmnt1OtltGsSnsrHtrPrlmnryF "Aftrtrtmnt1OtltGsSnsrHtrPrlmnryF";
BA_ "GenMsgCycleTime" BO_ 2566763518 500;
BA_ "GenMsgSendType" BO_ 2566763518 0;
BA_ "VFrameFormat" BO_ 2566763518 3;
BA_ "SystemSignalLongSymbol" SG_ 2566763518 Aftrtrtmnt1DslPrtcltFltrOtltGsTm "Aftrtrtmnt1DslPrtcltFltrOtltGsTm";
BA_ "SystemSignalLongSymbol" SG_ 2566763518 Aftrtrtmnt1DslPrtcltFltrOtltExhs "Aftrtrtmnt1DslPrtcltFltrOtltExhs";
BA_ "VFrameFormat" BO_ 2566749182 3;
BA_ "SystemSignalLongSymbol" SG_ 2566749182 Aftrtrtmnt1DslPrtcltFltrStLdRgnr "Aftrtrtmnt1DslPrtcltFltrStLdRgnr";
BA_ "VFrameFormat" BO_ 2566748670 3;
BA_ "SystemSignalLongSymbol" SG_ 2566748670 Aftrtrtmnt1TrpNmbrOfActvRgnrtnMn "Aftrtrtmnt1TrpNmbrOfActvRgnrtnMn";
BA_ "SystemSignalLongSymbol" SG_ 2566748670 Aftrtrtmnt1TrpNmbrOfActvRgnrtnIn "Aftrtrtmnt1TrpNmbrOfActvRgnrtnIn";
BA_ "GenMsgCycleTime" BO_ 2566758142 500;
BA_ "GenMsgSendType" BO_ 2566758142 0;
BA_ "VFrameFormat" BO_ 2566758142 3;
BA_ "GenMsgCycleTime" BO_ 2566745342 500;
BA_ "GenMsgSendType" BO_ 2566745342 0;
BA_ "VFrameFormat" BO_ 2566745342 3;
BA_ "GenMsgCycleTime" BO_ 2566758654 500;
BA_ "GenMsgSendType" BO_ 2566758654 0;
BA_ "VFrameFormat" BO_ 2566758654 3;
BA_ "GenMsgCycleTime" BO_ 2566753278 500;
BA_ "GenMsgSendType" BO_ 2566753278 0;
BA_ "VFrameFormat" BO_ 2566753278 3;
BA_ "VFrameFormat" BO_ 2566756862 3;
BA_ "SystemSignalLongSymbol" SG_ 2566756862 Aftrtrtmnt2TtlNmbrOfActvRgnrtnMn "Aftrtrtmnt2TtlNmbrOfActvRgnrtnMn";
BA_ "SystemSignalLongSymbol" SG_ 2566756862 Aftrtrtmnt2TtlNmbrOfActvRgnrtnIn "Aftrtrtmnt2TtlNmbrOfActvRgnrtnIn";
BA_ "GenMsgCycleTime" BO_ 2565869822 50;
BA_ "GenMsgSendType" BO_ 2565869822 0;
BA_ "VFrameFormat" BO_ 2565869822 3;
BA_ "SystemSignalLongSymbol" SG_ 2565869822 Aftrtrtmnt2IntkOxygnSnsrPrlmnryF "Aftrtrtmnt2IntkOxygnSnsrPrlmnryF";
BA_ "SystemSignalLongSymbol" SG_ 2565869822 Aftrtrtmnt2IntkGsSnsrHtrPrlmnryF "Aftrtrtmnt2IntkGsSnsrHtrPrlmnryF";
BA_ "GenMsgCycleTime" BO_ 2566763006 500;
BA_ "GenMsgSendType" BO_ 2566763006 0;
BA_ "VFrameFormat" BO_ 2566763006 3;
BA_ "SystemSignalLongSymbol" SG_ 2566763006 Aftrtrtmnt2DslPrtcltFltrIntkGsTm "Aftrtrtmnt2DslPrtcltFltrIntkGsTm";
BA_ "SystemSignalLongSymbol" SG_ 2566763006 Aftrtrtmnt2DslPrtcltFltrInt_0000 "Aftrtrtmnt2DslPrtcltFltrInt_0000";
BA_ "GenMsgCycleTime" BO_ 2566762494 500;
BA_ "GenMsgSendType" BO_ 2566762494 0;
BA_ "VFrameFormat" BO_ 2566762494 3;
BA_ "SystemSignalLongSymbol" SG_ 2566762494 Aftrtrtmnt2DslPrtcltFltrIntrmdtG "Aftrtrtmnt2DslPrtcltFltrIntrmdtG";
BA_ "SystemSignalLongSymbol" SG_ 2566762494 Aftrtrtmnt2DslPrtcltFltrInt_0001 "Aftrtrtmnt2DslPrtcltFltrInt_0001";
BA_ "SystemSignalLongSymbol" SG_ 2566762494 Aftrtrtmnt2DslPrtcltFltrDltPrssP "Aftrtrtmnt2DslPrtcltFltrDltPrssP";
BA_ "GenMsgCycleTime" BO_ 2565870078 50;
BA_ "GenMsgSendType" BO_ 2565870078 0;
BA_ "VFrameFormat" BO_ 2565870078 3;
BA_ "SystemSignalLongSymbol" SG_ 2565870078 Aftrtrtmnt2OtltOxygnSnsrPrlmnryF "Aftrtrtmnt2OtltOxygnSnsrPrlmnryF";
BA_ "SystemSignalLongSymbol" SG_ 2565870078 Aftrtrtmnt2OtltGsSnsrHtrPrlmnryF "Aftrtrtmnt2OtltGsSnsrHtrPrlmnryF";
BA_ "GenMsgCycleTime" BO_ 2566762750 500;
BA_ "GenMsgSendType" BO_ 2566762750 0;
BA_ "VFrameFormat" BO_ 2566762750 3;
BA_ "SystemSignalLongSymbol" SG_ 2566762750 Aftrtrtmnt2DslPrtcltFltrOtltGsTm "Aftrtrtmnt2DslPrtcltFltrOtltGsTm";
BA_ "SystemSignalLongSymbol" SG_ 2566762750 Aftrtrtmnt2DslPrtcltFltrExhstGsT "Aftrtrtmnt2DslPrtcltFltrExhstGsT";
BA_ "VFrameFormat" BO_ 2566748926 3;
BA_ "SystemSignalLongSymbol" SG_ 2566748926 Aftrtrtmnt2DslPrtcltFltrStLdRgnr "Aftrtrtmnt2DslPrtcltFltrStLdRgnr";
BA_ "VFrameFormat" BO_ 2566748414 3;
BA_ "SystemSignalLongSymbol" SG_ 2566748414 Aftrtrtmnt2TrpNmbrOfActvRgnrtnMn "Aftrtrtmnt2TrpNmbrOfActvRgnrtnMn";
BA_ "SystemSignalLongSymbol" SG_ 2566748414 Aftrtrtmnt2TrpNmbrOfActvRgnrtnIn "Aftrtrtmnt2TrpNmbrOfActvRgnrtnIn";
BA_ "GenMsgCycleTime" BO_ 2365428478 250;
BA_ "VFrameFormat" BO_ 2365428478 3;
BA_ "GenMsgCycleTime" BO_ 2566743806 1000;
BA_ "GenMsgSendType" BO_ 2566743806 0;
BA_ "VFrameFormat" BO_ 2566743806 3;
BA_ "VFrameFormat" BO_ 2499635454 3;
BA_ "GenMsgCycleTime" BO_ 2550660862 100;
BA_ "VFrameFormat" BO_ 2550660862 3;
BA_ "GenMsgCycleTime" BO_ 2566805758 100;
BA_ "GenMsgSendType" BO_ 2566805758 0;
BA_ "VFrameFormat" BO_ 2566805758 3;
BA_ "GenMsgCycleTime" BO_ 2566806014 100;
BA_ "GenMsgSendType" BO_ 2566806014 0;
BA_ "VFrameFormat" BO_ 2566806014 3;
BA_ "GenMsgCycleTime" BO_ 2362638078 100;
BA_ "GenMsgSendType" BO_ 2362638078 0;
BA_ "VFrameFormat" BO_ 2362638078 3;
BA_ "GenMsgCycleTime" BO_ 2365479678 100;
BA_ "GenMsgSendType" BO_ 2365479678 0;
BA_ "VFrameFormat" BO_ 2365479678 3;
BA_ "GenMsgCycleTime" BO_ 2566837758 1000;
BA_ "GenMsgSendType" BO_ 2566837758 0;
BA_ "VFrameFormat" BO_ 2566837758 3;
BA_ "GenMsgSendType" BO_ 2633922558 8;
BA_ "VFrameFormat" BO_ 2633922558 3;
BA_ "GenMsgCycleTime" BO_ 2566775038 1000;
BA_ "GenMsgSendType" BO_ 2566775038 0;
BA_ "VFrameFormat" BO_ 2566775038 3;
BA_ "GenMsgSendType" BO_ 2566836478 8;
BA_ "VFrameFormat" BO_ 2566836478 3;
BA_ "GenMsgSendType" BO_ 2565078782 8;
BA_ "VFrameFormat" BO_ 2565078782 3;
BA_ "GenMsgSendType" BO_ 2566836222 8;
BA_ "VFrameFormat" BO_ 2566836222 3;
BA_ "GenMsgSendType" BO_ 2566835966 8;
BA_ "VFrameFormat" BO_ 2566835966 3;
BA_ "SystemSignalLongSymbol" SG_ 2566835966 NOxConvertingCatalystAdsorberSta "NOxConvertingCatalystAdsorberSta";
BA_ "SystemSignalLongSymbol" SG_ 2566835966 BoostPressureControlSystemSuppor "BoostPressureControlSystemSuppor";
BA_ "SystemSignalLongSymbol" SG_ 2566835966 NOxConvertingCatalystAdsorberSup "NOxConvertingCatalystAdsorberSup";
BA_ "GenMsgSendType" BO_ 2566835710 8;
BA_ "VFrameFormat" BO_ 2566835710 3;
BA_ "GenMsgSendType" BO_ 2566835454 8;
BA_ "VFrameFormat" BO_ 2566835454 3;
BA_ "GenMsgSendType" BO_ 2566764542 8;
BA_ "VFrameFormat" BO_ 2566764542 3;
BA_ "GenMsgSendType" BO_ 2566764286 8;
BA_ "VFrameFormat" BO_ 2566764286 3;
BA_ "GenMsgSendType" BO_ 2566764030 8;
BA_ "VFrameFormat" BO_ 2566764030 3;
BA_ "GenMsgSendType" BO_ 2562981630 8;
BA_ "VFrameFormat" BO_ 2562981630 3;
BA_ "GenMsgSendType" BO_ 2562850558 8;
BA_ "VFrameFormat" BO_ 2562850558 3;
BA_ "GenMsgSendType" BO_ 2562916094 8;
BA_ "VFrameFormat" BO_ 2562916094 3;
BA_ "GenMsgSendType" BO_ 2566835198 8;
BA_ "VFrameFormat" BO_ 2566835198 3;
BA_ "GenMsgSendType" BO_ 2564030206 8;
BA_ "VFrameFormat" BO_ 2564030206 3;
BA_ "GenMsgSendType" BO_ 2564226814 8;
BA_ "VFrameFormat" BO_ 2564226814 3;
BA_ "GenMsgSendType" BO_ 2564292350 8;
BA_ "VFrameFormat" BO_ 2564292350 3;
BA_ "GenMsgSendType" BO_ 2564357886 8;
BA_ "VFrameFormat" BO_ 2564357886 3;
BA_ "GenMsgSendType" BO_ 2564423422 8;
BA_ "VFrameFormat" BO_ 2564423422 3;
BA_ "GenMsgSendType" BO_ 2564816638 8;
BA_ "VFrameFormat" BO_ 2564816638 3;
BA_ "GenMsgSendType" BO_ 2566837502 8;
BA_ "VFrameFormat" BO_ 2566837502 3;
BA_ "GenMsgSendType" BO_ 2566837246 8;
BA_ "VFrameFormat" BO_ 2566837246 3;
BA_ "GenMsgSendType" BO_ 2566836990 8;
BA_ "VFrameFormat" BO_ 2566836990 3;
BA_ "GenMsgSendType" BO_ 2566834942 8;
BA_ "VFrameFormat" BO_ 2566834942 3;
BA_ "GenMsgSendType" BO_ 2566780926 8;
BA_ "VFrameFormat" BO_ 2566780926 3;
BA_ "GenMsgSendType" BO_ 2566781182 8;
BA_ "VFrameFormat" BO_ 2566781182 3;
BA_ "GenMsgSendType" BO_ 2566778366 8;
BA_ "VFrameFormat" BO_ 2566778366 3;
BA_ "GenMsgSendType" BO_ 2566778622 8;
BA_ "VFrameFormat" BO_ 2566778622 3;
BA_ "GenMsgSendType" BO_ 2566778878 8;
BA_ "VFrameFormat" BO_ 2566778878 3;
BA_ "GenMsgSendType" BO_ 2566779134 8;
BA_ "VFrameFormat" BO_ 2566779134 3;
BA_ "GenMsgSendType" BO_ 2566779390 8;
BA_ "VFrameFormat" BO_ 2566779390 3;
BA_ "GenMsgSendType" BO_ 2566779646 8;
BA_ "VFrameFormat" BO_ 2566779646 3;
BA_ "GenMsgSendType" BO_ 2566779902 8;
BA_ "VFrameFormat" BO_ 2566779902 3;
BA_ "GenMsgSendType" BO_ 2566780158 8;
BA_ "VFrameFormat" BO_ 2566780158 3;
BA_ "GenMsgSendType" BO_ 2566780414 8;
BA_ "VFrameFormat" BO_ 2566780414 3;
BA_ "GenMsgSendType" BO_ 2566780670 8;
BA_ "VFrameFormat" BO_ 2566780670 3;
BA_ "GenMsgSendType" BO_ 2566781438 8;
BA_ "VFrameFormat" BO_ 2566781438 3;
BA_ "GenMsgSendType" BO_ 2566784254 8;
BA_ "VFrameFormat" BO_ 2566784254 3;
BA_ "GenMsgSendType" BO_ 2566784510 8;
BA_ "VFrameFormat" BO_ 2566784510 3;
BA_ "GenMsgSendType" BO_ 2566781694 8;
BA_ "VFrameFormat" BO_ 2566781694 3;
BA_ "GenMsgSendType" BO_ 2566781950 8;
BA_ "VFrameFormat" BO_ 2566781950 3;
BA_ "GenMsgSendType" BO_ 2566782206 8;
BA_ "VFrameFormat" BO_ 2566782206 3;
BA_ "GenMsgSendType" BO_ 2566782462 8;
BA_ "VFrameFormat" BO_ 2566782462 3;
BA_ "GenMsgSendType" BO_ 2566782718 8;
BA_ "VFrameFormat" BO_ 2566782718 3;
BA_ "GenMsgSendType" BO_ 2566782974 8;
BA_ "VFrameFormat" BO_ 2566782974 3;
BA_ "GenMsgSendType" BO_ 2566783230 8;
BA_ "VFrameFormat" BO_ 2566783230 3;
VAL_ 2566742270 FailureModeIdentifier1 31 "Not available" 19 "Received network data in error" 18 "Below normal (moderately severe)" 17 "Below normal (least severe)" 16 "Above normal (moderately severe)" 15 "Above normal (least severe)" 14 "Special intstructions" 13 "Out of calibration" 12 "Bad intelligent device" 11 "Root cause not known" 10 "Abnormal rate of change" 9 "Abnormal update rate" 8 "Abnormal frequency" 7 "Mechanical system not responding" 6 "Current above normal" 5 "Current below normal" 4 "Voltage below normal" 3 "Voltage above normal" 2 "Data erratic" 1 "Below normal (most severe)" 0 "Above normal (most severe)";
VAL_ 2560687870 PMNTEDeficiencyAreaStatus 3 "NotAvailable" 2 "Reserved" 1 "InsideControlArea" 0 "OutsideControlArea";
VAL_ 2560687870 MnfcPMNTECarveOutAreaStatus 3 "NotAvailable" 2 "Reserved" 1 "InsideControlArea" 0 "OutsideControlArea";
VAL_ 2560687870 PMNTEControlAreaStatus 3 "NotAvailable" 2 "Reserved" 1 "InsideControlArea" 0 "OutsideControlArea";
VAL_ 2560687870 NOxNTEDeficiencyAreaStatus 3 "NotAvailable" 2 "Reserved" 1 "InsideControlArea" 0 "OutsideControlArea";
VAL_ 2560687870 MnfcNOxNTECarveOutAreaStatus 3 "NotAvailable" 2 "Reserved" 1 "InsideControlArea" 0 "OutsideControlArea";
VAL_ 2560687870 NOxNTEControlAreaStatus 3 "NotAvailable" 2 "Reserved" 1 "InsideControlArea" 0 "OutsideControlArea";
VAL_ 2566809342 BatteryMainSwitchHoldState 3 "DontCare_TakeNoAction" 2 "Reserved" 1 "BatteryMainSwitchHeld" 0 "BatteryMainSwitchNotHeld";
VAL_ 2365446910 Joystick3XAxisDetentPosStatus 3 "NotAvailable" 2 "ErrorIndicator" 1 "InDetentPos" 0 "NotInDetentPos";
VAL_ 2365446910 Joystick3Button9PressedStatus 3 "NotAvailable" 2 "ErrorIndicator" 1 "ButtonPressed" 0 "ButtonNotPressed";
VAL_ 2365446910 Joystick3Button10PressedStatus 3 "NotAvailable" 2 "ErrorIndicator" 1 "ButtonPressed" 0 "ButtonNotPressed";
VAL_ 2365446910 Joystick3Button11PressedStatus 3 "NotAvailable" 2 "ErrorIndicator" 1 "ButtonPressed" 0 "ButtonNotPressed";
VAL_ 2365446910 Joystick3Button12PressedStatus 3 "NotAvailable" 2 "ErrorIndicator" 1 "ButtonPressed" 0 "ButtonNotPressed";
VAL_ 2365446910 Joystick3YAxisDetentPosStatus 3 "NotAvailable" 2 "ErrorIndicator" 1 "InDetentPos" 0 "NotInDetentPos";
VAL_ 2365446910 Jystck3YAxsLvrFrwrdPstvPsStatus 3 "NotAvailable" 2 "ErrorIndicator" 1 "OnPositiveSideOfNeutral" 0 "NotOnPositiveSideOfNeutral";
VAL_ 2365446910 Jystck3YAxsLvrBckNgtvePosStatus 3 "NotAvailable" 2 "ErrorIndicator" 1 "OnNegativeSideOfNeutral" 0 "NotOnNegativeSideOfNeutral";
VAL_ 2365446910 Joystick3YAxisNeutralPosStatus 3 "NotAvailable" 2 "ErrorIndicator" 1 "InNeutralPos" 0 "NotInNeutralPos";
VAL_ 2365446910 Jystck3XAxsLvrRghtPstvPosStatus 3 "NotAvailable" 2 "ErrorIndicator" 1 "OnPositiveSideOfNeutral" 0 "NotOnPositiveSideOfNeutral";
VAL_ 2365446910 Jystck3XAxsLvrLftNgtvePosStatus 3 "NotAvailable" 2 "ErrorIndicator" 1 "OnNegativeSideOfNeutral" 0 "NotOnNegativeSideOfNeutral";
VAL_ 2365446910 Joystick3XAxisNeutralPosStatus 3 "NotAvailable" 2 "ErrorIndicator" 1 "InNeutralPos" 0 "NotInNeutralPos";
VAL_ 2365446910 Joystick3Button5PressedStatus 3 "NotAvailable" 2 "ErrorIndicator" 1 "ButtonPressed" 0 "ButtonNotPressed";
VAL_ 2365446910 Joystick3Button6PressedStatus 3 "NotAvailable" 2 "ErrorIndicator" 1 "ButtonPressed" 0 "ButtonNotPressed";
VAL_ 2365446910 Joystick3Button7PressedStatus 3 "NotAvailable" 2 "ErrorIndicator" 1 "ButtonPressed" 0 "ButtonNotPressed";
VAL_ 2365446910 Joystick3Button8PressedStatus 3 "NotAvailable" 2 "ErrorIndicator" 1 "ButtonPressed" 0 "ButtonNotPressed";
VAL_ 2365446910 Joystick3Button1PressedStatus 3 "NotAvailable" 2 "ErrorIndicator" 1 "ButtonPressed" 0 "ButtonNotPressed";
VAL_ 2365446910 Joystick3Button2PressedStatus 3 "NotAvailable" 2 "ErrorIndicator" 1 "ButtonPressed" 0 "ButtonNotPressed";
VAL_ 2365446910 Joystick3Button3PressedStatus 3 "NotAvailable" 2 "ErrorIndicator" 1 "ButtonPressed" 0 "ButtonNotPressed";
VAL_ 2365446910 Joystick3Button4PressedStatus 3 "NotAvailable" 2 "ErrorIndicator" 1 "ButtonPressed" 0 "ButtonNotPressed";
VAL_ 2365446398 Joystick2XAxisDetentPosStatus 3 "NotAvailable" 2 "ErrorIndicator" 1 "InDetentPos" 0 "NotInDetentPos";
VAL_ 2365446398 Joystick2YAxisDetentPosStatus 3 "NotAvailable" 2 "ErrorIndicator" 1 "InDetentPos" 0 "NotInDetentPos";
VAL_ 2365446398 Jystck2YAxsLvrFrwrdPstvPsStatus 3 "NotAvailable" 2 "ErrorIndicator" 1 "OnPositiveSideOfNeutral" 0 "NotOnPositiveSideOfNeutral";
VAL_ 2365446398 Jystck2YAxsLvrBckNgtvePosStatus 3 "NotAvailable" 2 "ErrorIndicator" 1 "OnNegativeSideOfNeutral" 0 "NotOnNegativeSideOfNeutral";
VAL_ 2365446398 Joystick2YAxisNeutralPosStatus 3 "NotAvailable" 2 "ErrorIndicator" 1 "InNeutralPos" 0 "NotInNeutralPos";
VAL_ 2365446398 Jystck2XAxsLvrRghtPstvPosStatus 3 "NotAvailable" 2 "ErrorIndicator" 1 "OnPositiveSideOfNeutral" 0 "NotOnPositiveSideOfNeutral";
VAL_ 2365446398 Jystck2XAxsLvrLftNgtvePosStatus 3 "NotAvailable" 2 "ErrorIndicator" 1 "OnNegativeSideOfNeutral" 0 "NotOnNegativeSideOfNeutral";
VAL_ 2365446398 Joystick2XAxisNeutralPosStatus 3 "NotAvailable" 2 "ErrorIndicator" 1 "InNeutralPos" 0 "NotInNeutralPos";
VAL_ 2365446398 Joystick2Button9PressedStatus 3 "NotAvailable" 2 "ErrorIndicator" 1 "ButtonPressed" 0 "ButtonNotPressed";
VAL_ 2365446398 Joystick2Button10PressedStatus 3 "NotAvailable" 2 "ErrorIndicator" 1 "ButtonPressed" 0 "ButtonNotPressed";
VAL_ 2365446398 Joystick2Button11PressedStatus 3 "NotAvailable" 2 "ErrorIndicator" 1 "ButtonPressed" 0 "ButtonNotPressed";
VAL_ 2365446398 Joystick2Button12PressedStatus 3 "NotAvailable" 2 "ErrorIndicator" 1 "ButtonPressed" 0 "ButtonNotPressed";
VAL_ 2365446398 Joystick2Button5PressedStatus 3 "NotAvailable" 2 "ErrorIndicator" 1 "ButtonPressed" 0 "ButtonNotPressed";
VAL_ 2365446398 Joystick2Button6PressedStatus 3 "NotAvailable" 2 "ErrorIndicator" 1 "ButtonPressed" 0 "ButtonNotPressed";
VAL_ 2365446398 Joystick2Button7PressedStatus 3 "NotAvailable" 2 "ErrorIndicator" 1 "ButtonPressed" 0 "ButtonNotPressed";
VAL_ 2365446398 Joystick2Button8PressedStatus 3 "NotAvailable" 2 "ErrorIndicator" 1 "ButtonPressed" 0 "ButtonNotPressed";
VAL_ 2365446398 Joystick2Button1PressedStatus 3 "NotAvailable" 2 "ErrorIndicator" 1 "ButtonPressed" 0 "ButtonNotPressed";
VAL_ 2365446398 Joystick2Button2PressedStatus 3 "NotAvailable" 2 "ErrorIndicator" 1 "ButtonPressed" 0 "ButtonNotPressed";
VAL_ 2365446398 Joystick2Button3PressedStatus 3 "NotAvailable" 2 "ErrorIndicator" 1 "ButtonPressed" 0 "ButtonNotPressed";
VAL_ 2365446398 Joystick2Button4PressedStatus 3 "NotAvailable" 2 "ErrorIndicator" 1 "ButtonPressed" 0 "ButtonNotPressed";
VAL_ 2365445886 Joystick1XAxisDetentPosStatus 3 "NotAvailable" 2 "ErrorIndicator" 1 "InDetentPos" 0 "NotInDetentPos";
VAL_ 2365445886 Joystick1YAxisDetentPosStatus 3 "NotAvailable" 2 "ErrorIndicator" 1 "InDetentPos" 0 "NotInDetentPos";
VAL_ 2365445886 Jystck1YAxsLvrFrwrdPstvPsStatus 3 "NotAvailable" 2 "ErrorIndicator" 1 "OnPositiveSideOfNeutral" 0 "NotOnPositiveSideOfNeutral";
VAL_ 2365445886 Jystck1YAxsLvrBckNgtvePosStatus 3 "NotAvailable" 2 "ErrorIndicator" 1 "OnNegativeSideOfNeutral" 0 "NotOnNegativeSideOfNeutral";
VAL_ 2365445886 Joystick1YAxisNeutralPosStatus 3 "NotAvailable" 2 "ErrorIndicator" 1 "InNeutralPos" 0 "NotInNeutralPos";
VAL_ 2365445886 Joystick1Button9PressedStatus 3 "NotAvailable" 2 "ErrorIndicator" 1 "ButtonPressed" 0 "ButtonNotPressed";
VAL_ 2365445886 Joystick1Button10PressedStatus 3 "NotAvailable" 2 "ErrorIndicator" 1 "ButtonPressed" 0 "ButtonNotPressed";
VAL_ 2365445886 Joystick1Button11PressedStatus 3 "NotAvailable" 2 "ErrorIndicator" 1 "ButtonPressed" 0 "ButtonNotPressed";
VAL_ 2365445886 Joystick1Button12PressedStatus 3 "NotAvailable" 2 "ErrorIndicator" 1 "ButtonPressed" 0 "ButtonNotPressed";
VAL_ 2365445886 Joystick1Button5PressedStatus 3 "NotAvailable" 2 "ErrorIndicator" 1 "ButtonPressed" 0 "ButtonNotPressed";
VAL_ 2365445886 Joystick1Button6PressedStatus 3 "NotAvailable" 2 "ErrorIndicator" 1 "ButtonPressed" 0 "ButtonNotPressed";
VAL_ 2365445886 Joystick1Button7PressedStatus 3 "NotAvailable" 2 "ErrorIndicator" 1 "ButtonPressed" 0 "ButtonNotPressed";
VAL_ 2365445886 Joystick1Button8PressedStatus 3 "NotAvailable" 2 "ErrorIndicator" 1 "ButtonPressed" 0 "ButtonNotPressed";
VAL_ 2365445886 Joystick1Button1PressedStatus 3 "NotAvailable" 2 "ErrorIndicator" 1 "ButtonPressed" 0 "ButtonNotPressed";
VAL_ 2365445886 Joystick1Button2PressedStatus 3 "NotAvailable" 2 "ErrorIndicator" 1 "ButtonPressed" 0 "ButtonNotPressed";
VAL_ 2365445886 Joystick1Button3PressedStatus 3 "NotAvailable" 2 "ErrorIndicator" 1 "ButtonPressed" 0 "ButtonNotPressed";
VAL_ 2365445886 Joystick1Button4PressedStatus 3 "NotAvailable" 2 "ErrorIndicator" 1 "ButtonPressed" 0 "ButtonNotPressed";
VAL_ 2365445886 Jystck1XAxsLvrRghtPstvPosStatus 3 "NotAvailable" 2 "ErrorIndicator" 1 "OnPositiveSideOfNeutral" 0 "NotOnPositiveSideOfNeutral";
VAL_ 2365445886 Jystck1XAxsLvrLftNgtvePosStatus 3 "NotAvailable" 2 "ErrorIndicator" 1 "OnNegativeSideOfNeutral" 0 "NotOnNegativeSideOfNeutral";
VAL_ 2365445886 Joystick1XAxisNeutralPosStatus 3 "NotAvailable" 2 "ErrorIndicator" 1 "InNeutralPos" 0 "NotInNeutralPos";
VAL_ 2566847230 ParkingBrakeRedWarningSignal 3 "TakeNoAction" 2 "Reserved" 1 "On" 0 "Off";
VAL_ 2566847230 ParkBrakeReleaseInhibitStatus 3 "Unavailable" 2 "Error" 1 "ParkBrakeReleaseIsInhibited" 0 "ParkBrakeReleaseIsNotInhibited";
VAL_ 2566847230 ParkingBrakeActuator 3 "NotAvailable" 2 "Error" 1 "ParkingBrakeActuatorActive" 0 "ParkingBrakeActuatorInactive";
VAL_ 2560884478 DTCWarnLampSupportStatus 3 "Unavailable" 2 "Reserved" 1 "LampOn" 0 "LampOff";
VAL_ 2560884478 DTCWarnLampSupportFlash 3 "Unavailable" 2 "Reserved" 1 "FastFlash" 0 "SlowFlash";
VAL_ 2560884478 DTCStopLampSupportStatus 3 "Unavailable" 2 "Reserved" 1 "LampOn" 0 "LampOff";
VAL_ 2560884478 DTCStopLampSupportFlash 3 "Unavailable" 2 "Reserved" 1 "FastFlash" 0 "SlowFlash";
VAL_ 2560884478 DTCProtectLampSupportStatus 3 "Unavailable" 2 "Reserved" 1 "LampOn" 0 "LampOff";
VAL_ 2560884478 DTCProtectLampSupportFlash 3 "Unavailable" 2 "Reserved" 1 "FastFlash" 0 "SlowFlash";
VAL_ 2560884478 DTCMilSupportStatus 3 "Unavailable" 2 "ShortMI" 1 "LampOn" 0 "LampOff";
VAL_ 2560884478 DTCMilSupportFlash 3 "Unavailable" 2 "Class_C_DTC" 1 "FastFlash" 0 "SlowFlash";
VAL_ 2566736126 EngExhstGsOxygnSnsrClsdLpOprtnBn 15 "NotSupported" 5 "1110Reserved" 4 "ClsdLpBtFltWthAtLstOnOxygnSnsrM" 3 "OpnLoopDueToDetectedSystemFault" 2 "OpenLoopDueToDrivingConditions" 1 "ClsdLpUsngOxygnSnsrAsFdbckFrFlC" 0 "OpnLpHsNtYtStsfdCndtnsTGClsdLop";
VAL_ 2566736382 EngExhstGsOxygnSnsrClsdLpOp_0000 15 "NotSupported" 5 "1110Reserved" 4 "ClsdLpBtFltWthAtLstOnOxygnSnsrM" 3 "OpnLoopDueToDetectedSystemFault" 2 "OpenLoopDueToDrivingConditions" 1 "ClsdLpUsngOxygnSnsrAsFdbckFrFlC" 0 "OpnLpHsNtYtStsfdCndtnsTGClsdLop";
VAL_ 2565874174 EngSpdSnsor1TimingPatternStatus 3 "NotAvailable" 2 "Error" 1 "OK" 0 "NotOK";
VAL_ 2565874174 EngSpdSnsor2TimingPatternStatus 3 "NotAvailable" 2 "Error" 1 "OK" 0 "NotOK";
VAL_ 2565874174 EngSpdSnsor3TimingPatternStatus 3 "NotAvailable" 2 "Error" 1 "OK" 0 "NotOK";
VAL_ 2432520958 EngCoolantThermostatMode 3 "DontCare_Reserved" 2 "Reserved" 1 "PosCtrlMode" 0 "TempCtrlMode";
VAL_ 2566758398 Aftrtreatment1AirEnableActuator 3 "notAvailable" 2 "reservedForSAEAssignment" 1 "active" 0 "notActive";
VAL_ 2566758398 Aftertreatment1PurgeAirActuator 3 "notAvailable" 2 "reservedForSAEAssignment" 1 "active" 0 "notActive";
VAL_ 2566758398 Aftrtrtmnt1AtmzationAirActuator 3 "notAvailable" 2 "reservedForSAEAssignment" 1 "active" 0 "notActive";
VAL_ 2566758398 Aftertreatment1AirSystemRelay 3 "notAvailable" 2 "reservedForSAEAssignment" 1 "active" 0 "notActive";
VAL_ 2566758910 Aftrtrtmnt1FlInjctor1HeaterCtrl 4 "Max";
VAL_ 2566758910 Aftrtratment1FuelEnableActuator 3 "notAvailable" 2 "reservedForSAEAssignment" 1 "active" 0 "notActive";
VAL_ 2566758910 Aftrtratment1RegenerationStatus 3 "notAvailable" 2 "reservedForSAEAssignment" 1 "active" 0 "notActive";
VAL_ 2566758910 Aftertreatment1Ignt 3 "notAvailable" 2 "reservedForSAEAssignment" 1 "active" 0 "notActive";
VAL_ 2566758910 Aftrtreatment1FuelDrainActuator 3 "notAvailable" 2 "reservedForSAEAssignment" 1 "active" 0 "notActive";
VAL_ 2566743550 Aftrtrtmnt1FlPress2ActuatorCtrl 4 "fullyOpen";
VAL_ 2566743550 Aftrtrtmnt1FlFlwDvrterValveCtrl 3 "notAvailable" 2 "reservedForSAEAssignment" 1 "on" 0 "off";
VAL_ 2566743550 Aftrtreatment1FuelPumpRelayCtrl 3 "notAvailable" 2 "reservedForSAEAssignment" 1 "on" 0 "off";
VAL_ 2565869310 Aftrtrtmnt1IntkGsSnsrPwerStatus 3 "NotAvailable" 2 "Error" 1 "InRange" 0 "NotInRange";
VAL_ 2565869310 Aftrtrtmnt1IntkGsSnsrHeaterCtrl 3 "HeaterOff" 2 "Preheat1" 1 "Preheat2" 0 "Automatic";
VAL_ 2565869310 Aftrtrtmnt1IntkWdRngO2RdngStble 3 "NotAvailable" 2 "Error" 1 "Stable" 0 "NotStable";
VAL_ 2565869310 Aftrtrtmnt1IntkNOxReadingStable 3 "NotAvailable" 2 "Error" 1 "Stable" 0 "NotStable";
VAL_ 2631728894 AntitheftComponentStatusStates 3 "NotDefined" 2 "BlckdThsSttIndctsThtALckUnlckCm" 1 "LckdThsSttIndctsThtCmpnntCnNOTB" 0 "UnlckdThsSttIndctsThtCmpnntCnBS";
VAL_ 2631728894 AntthftEncryptnSdPrsntIndicator 3 "NotAvailable" 2 "Error" 1 "RandomNumberIsPresent" 0 "RandomNumberIsNotPresent";
VAL_ 2631728894 AntitheftModifyPwdStates 3 "Notvalid" 2 "EmptyOfPwdsThsSttIndctsThtCmpnn" 1 "FullofPwds" 0 "OkThsSttIndctsThtRqWsSccssfllyP";
VAL_ 2631728894 AntitheftPwdValidIndicator 3 "NotAvailable" 2 "Error" 1 "PwdIsAValidatedPassword" 0 "PwdIsNotAValidatedPassword";
VAL_ 2631794430 AntitheftCmdStates 6 "111NotDefined" 5 "Login" 4 "ChckSttsThsSttRprsntsARqTChckTS" 3 "LockorUnlock" 2 "ChngPwdThsSttRprsntsARqTCmpnntT" 1 "DeletePwd" 0 "AddPwdThsSttRprsntsARqTCmpnntTA";
VAL_ 2631794430 AntitheftDesiredExitModeStates 3 "NtAvlblThsSttIsIndctsThtOptnIsN" 2 "NotDefined" 1 "LckWhnKyffThsSttIsUsdTIndctThtC" 0 "LckUpnOprtrRqThsSttIsUsdTIndctT";
VAL_ 2631794430 AntthftEncryptonIndicatorStates 3 "NtAvlblThsSttIsUsdTIndctThtARnd" 2 "NotDefined" 1 "EncryptdCdPrsntThsSttIsUsdTIndc" 0 "EncryptnSdRqThsSttRprsntsARqstT";
VAL_ 2365478910 ElctrncShckAbsrbrCtrlMdLft_TgAxl 3 "NotAvailable" 2 "Error" 1 "NormalOperationDampersActive" 0 "NormalOperationDampersPassive";
VAL_ 2365478910 ElctrncShckAbsrbrCtrlMdRearAxle 3 "NotAvailable" 2 "Error" 1 "NormalOperationDampersActive" 0 "NormalOperationDampersPassive";
VAL_ 2365478910 ElctrncShckAbsrbrCtrlMdFrntAxle 3 "NotAvailable" 2 "Error" 1 "NormalOperationDampersActive" 0 "NormalOperationDampersPassive";
VAL_ 2560950014 FailureModeIdentifier1 31 "Not available" 19 "Received network data in error" 18 "Below normal (moderately severe)" 17 "Below normal (least severe)" 16 "Above normal (moderately severe)" 15 "Above normal (least severe)" 14 "Special intstructions" 13 "Out of calibration" 12 "Bad intelligent device" 11 "Root cause not known" 10 "Abnormal rate of change" 9 "Abnormal update rate" 8 "Abnormal frequency" 7 "Mechanical system not responding" 6 "Current above normal" 5 "Current below normal" 4 "Voltage below normal" 3 "Voltage above normal" 2 "Data erratic" 1 "Below normal (most severe)" 0 "Above normal (most severe)";
VAL_ 2565869566 Aftrtrtmnt1OtltGsSnsrPwerStatus 3 "NotAvailable" 2 "Error" 1 "InRange" 0 "NotInRange";
VAL_ 2565869566 Aftrtrtmnt1OtltGsSnsrHeaterCtrl 3 "HeaterOff" 2 "Preheat1" 1 "Preheat2" 0 "Automatic";
VAL_ 2565869566 Aftrtrtmnt1OtltWdRngO2RdngStble 3 "NotAvailable" 2 "Error" 1 "Stable" 0 "NotStable";
VAL_ 2565869566 Aftrtrtmnt1OtltNOxReadingStable 3 "NotAvailable" 2 "Error" 1 "Stable" 0 "NotStable";
VAL_ 2565869566 Aftrtrtmnt1OtletGasSensorAtTemp 3 "NotAvailable" 2 "Error" 1 "InRange" 0 "NotInRange";
VAL_ 2566749182 DslPrtclteFilter1AshLoadPercent 4 "LevelIsTargetAshServiceInterval";
VAL_ 2566749182 DslPrtcltFilter1SootLoadPercent 4 "LvlIsActvRgnerationTriggerLevel";
VAL_ 2566749182 Aftrtrtmnt1DslPrtcltFltrStLdRgnr 4 "IsLvlAtWhchActvDslPrtcltFltrRgn";
VAL_ 2566758142 Aftrtreatment2AirEnableActuator 3 "notAvailable" 2 "reservedForSAEAssignment" 1 "active" 0 "notActive";
VAL_ 2566758142 Aftertreatment2PurgeAirActuator 3 "notAvailable" 2 "reservedForSAEAssignment" 1 "active" 0 "notActive";
VAL_ 2566758142 Aftrtrtmnt2AtmzationAirActuator 3 "notAvailable" 2 "reservedForSAEAssignment" 1 "active" 0 "notActive";
VAL_ 2566758142 Aftertreatment2AirSystemRelay 3 "notAvailable" 2 "reservedForSAEAssignment" 1 "active" 0 "notActive";
VAL_ 2566758654 Aftrtrtmnt2FlInjctor1HeaterCtrl 4 "Max";
VAL_ 2566758654 Aftrtratment2FuelEnableActuator 3 "notAvailable" 2 "reservedForSAEAssignment" 1 "active" 0 "notActive";
VAL_ 2566758654 Aftrtratment2RegenerationStatus 3 "notAvailable" 2 "reservedForSAEAssignment" 1 "active" 0 "notActive";
VAL_ 2566758654 Aftertreatment2Ignt 3 "notAvailable" 2 "reservedForSAEAssignment" 1 "active" 0 "notActive";
VAL_ 2566758654 Aftrtreatment2FuelDrainActuator 3 "notAvailable" 2 "reservedForSAEAssignment" 1 "active" 0 "notActive";
VAL_ 2565869822 Aftrtrtmnt2IntkGsSnsrPwerStatus 3 "NotAvailable" 2 "Error" 1 "InRange" 0 "NotInRange";
VAL_ 2565869822 Aftrtrtmnt2IntkGsSnsrHeaterCtrl 3 "HeaterOff" 2 "Preheat1" 1 "Preheat2" 0 "Automatic";
VAL_ 2565869822 Aftrtrtmnt2IntkWdRngO2RdngStble 3 "NotAvailable" 2 "Error" 1 "Stable" 0 "NotStable";
VAL_ 2565869822 Aftrtrtmnt2IntkNOxReadingStable 3 "NotAvailable" 2 "Error" 1 "Stable" 0 "NotStable";
VAL_ 2565869822 Aftrtrtmnt2IntkeGasSensorAtTemp 3 "NotAvailable" 2 "Error" 1 "InRange" 0 "NotInRange";
VAL_ 2565870078 Aftrtrtmnt2OtltGsSnsrPwerStatus 3 "NotAvailable" 2 "Error" 1 "InRange" 0 "NotInRange";
VAL_ 2565870078 Aftrtrtmnt2OtltGsSnsrHeaterCtrl 3 "HeaterOff" 2 "Preheat1" 1 "Preheat2" 0 "Automatic";
VAL_ 2565870078 Aftrtrtmnt2OtltWdRngO2RdngStble 3 "NotAvailable" 2 "Error" 1 "Stable" 0 "NotStable";
VAL_ 2565870078 Aftrtrtmnt2OtltNOxReadingStable 3 "NotAvailable" 2 "Error" 1 "Stable" 0 "NotStable";
VAL_ 2565870078 Aftrtrtmnt2OtletGasSensorAtTemp 3 "NotAvailable" 2 "Error" 1 "InRange" 0 "NotInRange";
VAL_ 2566748926 DslPrtclteFilter2AshLoadPercent 4 "LevelIsTargetAshServiceInterval";
VAL_ 2566748926 DslPrtcltFilter2SootLoadPercent 4 "LvlIsActvRgnerationTriggerLevel";
VAL_ 2566748926 Aftrtrtmnt2DslPrtcltFltrStLdRgnr 4 "IsLvlAtWhchActvDslPrtcltFltrRgn";
VAL_ 2365428478 EngEmergencyShutdownIndication 3 "DontCare_TakeNoAction" 2 "Reserved" 1 "On" 0 "Off";
VAL_ 2365428478 EngCtrlledShutdownRq 3 "DontCare_TakeNoAction" 2 "Reserved" 1 "On" 0 "Off";
VAL_ 2365428478 EngCoolantCirculatingPumpCtrl 3 "DontCare_TakeNoAction" 2 "Reserved" 1 "On" 0 "Off";
VAL_ 2365428478 EngBlock_CoolantPreheaterCtrl 3 "Unavailable" 2 "Reserved" 1 "On" 0 "Off";
VAL_ 2365428478 EngElctrclSystmPwrCnsrvtionCtrl 3 "Unavailable" 2 "Reserved" 1 "On" 0 "Off";
VAL_ 2365428478 EngOilPreheaterCtrl 3 "DontCare_TakeNoAction" 2 "Reserved" 1 "On" 0 "Off";
VAL_ 2365428478 EngOilPrimingPumpCtrl 3 "Unavailable" 2 "Reserved" 1 "On" 0 "Off";
VAL_ 2365428478 EngFuelShutoffValveLeakTestCtrl 3 "DontCare_TakeNoAction" 2 "Reserved" 1 "On" 0 "Off";
VAL_ 2365428478 EngFuelShutoff2Ctrl 3 "DontCare_TakeNoAction" 2 "Reserved" 1 "Closed" 0 "Open";
VAL_ 2365428478 EngFuelShutoff1Ctrl 3 "DontCare_TakeNoAction" 2 "Reserved" 1 "Closed" 0 "Open";
VAL_ 2365428478 EngFuelShutoffVentCtrl 3 "DontCare_TakeNoAction" 2 "Reserved" 1 "Open" 0 "Closed";
VAL_ 2365428478 FuelPumpPrimerCtrl 3 "Unavailable" 2 "Reserved" 1 "Activate" 0 "Deactivate";
VAL_ 2362638078 SpeedDependentLevelCtrlRq 3 "DonTCare_TakeNoAction" 2 "Reserved" 1 "Activate" 0 "Deactivate";
VAL_ 2362638078 PrhbtAutomaticAirSuspensionCtrl 3 "NotAvailable" 2 "ErrorIndicator" 1 "RqPrhbtAtmaticAirSuspensionCtrl" 0 "NRq01RqstPrhbtdAtmtcArSspnsnCtr";
VAL_ 2362638078 MemoryLevelRq 15 "DontCare" 13 "StoreMemoryLevel5" 12 "StoreMemoryLevel4" 11 "StoreMemoryLevel3" 10 "StoreMemoryLevel2" 9 "StoreMemoryLevel1" 14 "Reserved" 5 "MemoryLevel5Rq" 4 "MemoryLevel4Rq" 3 "MemoryLevel3Rq" 2 "MemoryLevel2Rq" 1 "MemoryLevel1Rq" 0 "NoMemoryLevelRq";
VAL_ 2362638078 AllowLevelCtrlDuringBrakingCmd 3 "DonTCare_TakeNoAction" 2 "Reserved" 1 "AllowLevelCtrlDuringBraking" 0 "DisallowLevelCtrlDuringBraking";
VAL_ 2362638078 ProhibitAirSuspensionCtrl 3 "NotAvailable" 2 "ErrorIndicator" 1 "RqProhibitAirSuspensionCtrl" 0 "NoRq";
VAL_ 2362638078 KneelingCmdRearAxle 3 "DontCare_TakeNoAction" 2 "Reserved" 1 "ActivateKneeling" 0 "DeactivateKneeling";
VAL_ 2362638078 KneelingCmdFrontAxle 3 "DontCare_TakeNoAction" 2 "Reserved" 1 "ActivateKneeling" 0 "DeactivateKneeling";
VAL_ 2362638078 LevelCtrlModeRq 15 "DontCare_TakeNoAction" 14 "Reserved" 9 "1101NotDefined" 8 "ExhaustBellows" 7 "TractionHelpLoadReduce" 6 "OptmmTrctn2IPrssAtThDrvnAxlIsCt" 5 "OptmmTrctn1IPrssAtThDrvnAxlIsCt" 4 "PrssRt2IRtBtwnThPrssrsAtThDrvnA" 3 "PrssRt1IRtBtwnThPrssrsAtThDrvnA" 2 "LdFxngIDrvnAxlIsLddTAVlDfndByTh" 1 "TrctnHlpIDrvnAxlIsLddTAMxVlGvnB" 0 "NrmlOprtnISystmPrfrmsAPrCtrlOfT";
VAL_ 2362638078 NominalLevelRqRearAxle 11 "1101NotDefined" 10 "LowerRq" 15 "DontCare_TakeNoAction" 14 "Reserved" 9 "RaiseRq" 8 "StopLevelChange" 7 "LowerLevel" 6 "UpperLevel" 5 "CustomerLevel" 4 "PresetLevel" 3 "NormalLevel3" 2 "NormalLevel2" 1 "NormalLevel1" 0 "NoLevelRq";
VAL_ 2362638078 NominalLevelRqFrontAxle 11 "1101NotDefined" 10 "LowerRq" 15 "DontCare_TakeNoAction" 14 "Reserved" 9 "RaiseRq" 8 "StopLevelChange" 7 "LowerLevel" 6 "UpperLevel" 5 "CustomerLevel" 4 "PresetLevel" 3 "NormalLevel3" 2 "NormalLevel2" 1 "NormalLevel1" 0 "NoLevelRq";
VAL_ 2362638078 KneelingCtrlModeRq 3 "DontCare_TakeNoAction" 2 "Reserved" 1 "ManuallyActuated" 0 "AutomaticallyActuated";
VAL_ 2362638078 KneelingRqRightSide 3 "DontCare_TakeNoAction" 2 "Reserved" 1 "KneelingRq" 0 "NoKneelingRq";
VAL_ 2362638078 KneelingRqLeftSide 3 "DontCare_TakeNoAction" 2 "Reserved" 1 "KneelingRq" 0 "NoKneelingRq";
VAL_ 2362638078 AutomaticTractionHelp 3 "DontCare" 2 "Reserved" 1 "EnableAutomaticTractionHelp" 0 "DisableAutomaticTractionHelp";
VAL_ 2362638078 LiftAxle2PosCmd 3 "DontCare_TakeNoAction" 2 "Reserved" 1 "LiftAxlePosUp_TagAxleUnladen" 0 "LiftAxlePosDown_TagAxleLaden";
VAL_ 2362638078 LiftAxle1PosCmd 3 "DontCare_TakeNoAction" 2 "Reserved" 1 "LiftAxlePosUp_TagAxleUnladen" 0 "LiftAxlePosDown_TagAxleLaden";
VAL_ 2365479678 SpeedDependantLevelCtrlStatus 3 "DonTCare_TakeNoAction" 2 "Reserved" 1 "Active" 0 "Inactive";
VAL_ 2365479678 MemoryLevel 15 "NotAvailable" 14 "ErrorIndicator" 13 "MemoryLevel5Stored" 12 "MemoryLevel4Stored" 11 "MemoryLevel3Stored" 10 "MemoryLevel2Stored" 9 "MemoryLevel1Stored" 8 "Reserved" 5 "MemoryLevel5Selected" 4 "MemoryLevel4Selected" 3 "MemoryLevel3Selected" 2 "MemoryLevel2Selected" 1 "MemoryLevel1Selected" 0 "NoMemoryLevel";
VAL_ 2365479678 AllwLvelCtrlDuringBrakingStatus 3 "DonTCare_TakeNoAction" 2 "Reserved" 1 "Activate" 0 "Deactivate";
VAL_ 2365479678 SspensionCtrlRefusalInformation 15 "NotAvailable" 14 "Error" 8 "1101NotDefined" 7 "RqedLevelNotAvailable" 6 "GnrlRjctINSpcifiedReasonApplies" 5 "BelowSpeedLimit" 4 "AboveSpeedLimit" 3 "BogieDiffNotLocked" 2 "WouldExceedAxleLoadLimit" 1 "AxleLoadLimitReached" 0 "ActualRqNotRefused";
VAL_ 2365479678 SuspensionRemoteCtrl2 3 "NotAvailable" 2 "Error" 1 "Active" 0 "NotActive";
VAL_ 2365479678 SuspensionRemoteCtrl1 3 "NotAvailable" 2 "Error" 1 "Active" 0 "NotActive";
VAL_ 2365479678 RearAxleInBumperRange 3 "NotAvailable" 2 "Error" 1 "ActualLevelWithinBumperRange" 0 "ActualLevelOutOfBumperRange";
VAL_ 2365479678 FrontAxleInBumperRange 3 "NotAvailable" 2 "Error" 1 "ActualLevelWithinBumperRange" 0 "ActualLevelOutOfBumperRange";
VAL_ 2365479678 DoorRelease 3 "NotAvailable" 2 "Error" 1 "DoorsMayBeOpened" 0 "DoorsMayNotBeOpened";
VAL_ 2365479678 VehicleMotionInhibit 3 "NotAvailable" 2 "Error" 1 "VehicleMotionIsInhibited" 0 "VehicleMayBeMoved";
VAL_ 2365479678 SecurityDevice 3 "NotAvailable" 2 "Error" 1 "Active" 0 "NotActive";
VAL_ 2365479678 LevelCtrlMode 11 "1101NotDefined" 10 "AtmtcArSuspensionCtrlProhibited" 15 "NotAvailable" 14 "Error" 9 "AirSuspensionCtrlProhibited" 8 "ExhstngBllwFnctnIBllwsArExhstdT" 7 "TractionHelpLoadReduce" 6 "OptmmTrctn2IPrssAtThDrvnAxlIsCt" 5 "OptmmTrctn1IPrssAtThDrvnAxlIsCt" 4 "PrssRt2IRtBtwnThPrssrsAtThDrvnA" 3 "PrssRt1IRtBtwnThPrssrsAtThDrvnA" 2 "LdFxngIDrvnAxlnIsLddTAVlDfndByT" 1 "TrctnHlpIDrvnAxlIsLddTAMxVlGvnB" 0 "NrmlOprtnISystmPrfrmsAPrCtrlOfT";
VAL_ 2365479678 KneelingInformation 15 "NotAvailable" 14 "Error" 5 "1101NotDefined" 4 "KneelingAborted" 3 "LiftingActive" 2 "KneelingLevelReached" 0 "NotActive";
VAL_ 2365479678 LiftingCtrlModeRearAxle 3 "NotAvailable" 2 "Error" 1 "LiftingActive" 0 "LiftingNotActive";
VAL_ 2365479678 LiftingCtrlModeFrontAxle 3 "NotAvailable" 2 "Error" 1 "LiftingActive" 0 "LiftingNotActive";
VAL_ 2365479678 LoweringCtrlModeRearAxle 3 "NotAvailable" 2 "Error" 1 "LoweringActive" 0 "LoweringNotActive";
VAL_ 2365479678 LoweringCtrlModeFrontAxle 3 "NotAvailable" 2 "Error" 1 "LoweringActive" 0 "LoweringNotActive";
VAL_ 2365479678 AboveNominalLevelRearAxle 3 "NotAvailable" 2 "Error" 1 "Above" 0 "NotAbove";
VAL_ 2365479678 AboveNominalLevelFrontAxle 3 "NotAvailable" 2 "Error" 1 "Above" 0 "NotAbove";
VAL_ 2365479678 BelowNominalLevelRearAxle 3 "NotAvailable" 2 "Error" 1 "Below" 0 "NotBelow";
VAL_ 2365479678 BelowNominalLevelFrontAxle 3 "NotAvailable" 2 "Error" 1 "Below" 0 "NotBelow";
VAL_ 2365479678 NominalLevelRearAxle 9 "Raising" 11 "1101NotDefined" 10 "Lowering" 15 "NotAvailable" 14 "Error" 8 "NotDefined" 7 "LowerLevel" 6 "UpperLevel" 5 "CustomerLevel" 4 "PresetLevel" 3 "NormalLevel3" 2 "NormalLevel2" 1 "NormalLevel1" 0 "LevelNotSpecified";
VAL_ 2365479678 NominalLevelFrontAxle 9 "Raising" 11 "1101NotDefined" 10 "Lowering" 15 "NotAvailable" 14 "Error" 8 "NotDefined" 7 "LowerLevel" 6 "UpperLevel" 5 "CustomerLevel" 4 "PresetLevel" 3 "NormalLevel3" 2 "NormalLevel2" 1 "NormalLevel1" 0 "LevelNotSpecified";
VAL_ 2365479678 LiftAxle2Pos 3 "NotAvailable" 2 "Error" 1 "LiftAxlePosUp_TagAxleUnladen" 0 "LiftAxlePosDown_TagAxleLaden";
VAL_ 2365479678 LiftAxle1Pos 3 "NotAvailable" 2 "Error" 1 "LiftAxlePosUp_TagAxleUnladen" 0 "LiftAxlePosDown_TagAxleLaden";
VAL_ 2566837758 Alt4Status 3 "notAvailable" 2 "error" 1 "Alt4Charging" 0 "Alt4NotCharging";
VAL_ 2566837758 Alt3Status 3 "notAvailable" 2 "error" 1 "Alt3Charging" 0 "Alt3NotCharging";
VAL_ 2566837758 Alt2Status 3 "notAvailable" 2 "error" 1 "Alt2Charging" 0 "Alt2NotCharging";
VAL_ 2566837758 Alt1Status 3 "notAvailable" 2 "error" 1 "Alt1Charging" 0 "Alt1NotCharging";
VAL_ 2566836478 TestIdentifier 250 "Last Measured Scaled Results" 249 "Command Standard Test" 247 "All scaled test results";
VAL_ 2565078782 TestIdentifier 250 "Last Measured Scaled Results" 249 "Command Standard Test" 247 "All scaled test results";
VAL_ 2565078782 FailureModeIdentifier1 31 "Not available" 19 "Received network data in error" 18 "Below normal (moderately severe)" 17 "Below normal (least severe)" 16 "Above normal (moderately severe)" 15 "Above normal (least severe)" 14 "Special intstructions" 13 "Out of calibration" 12 "Bad intelligent device" 11 "Root cause not known" 10 "Abnormal rate of change" 9 "Abnormal update rate" 8 "Abnormal frequency" 7 "Mechanical system not responding" 6 "Current above normal" 5 "Current below normal" 4 "Voltage below normal" 3 "Voltage above normal" 2 "Data erratic" 1 "Below normal (most severe)" 0 "Above normal (most severe)";
VAL_ 2566836222 FlashRedStopLamp 3 "Unavailable / Do Not Flash" 2 "Reserved" 1 "Fast Flash" 0 "Slow Flash";
VAL_ 2566836222 FlashProtectLamp 3 "Unavailable / Do Not Flash" 2 "Reserved" 1 "Fast Flash" 0 "Slow Flash";
VAL_ 2566836222 FlashMalfuncIndicatorLamp 3 "Unavailable / Do Not Flash" 2 "Reserved" 1 "Fast Flash" 0 "Slow Flash";
VAL_ 2566836222 FlashAmberWarningLamp 3 "Unavailable / Do Not Flash" 2 "Reserved" 1 "Fast Flash" 0 "Slow Flash";
VAL_ 2566836222 MalfunctionIndicatorLampStatus 3 "Not available" 2 "Reserved" 1 "Lamp on" 0 "Lamp off";
VAL_ 2566836222 RedStopLampState 3 "Not available" 2 "Reserved" 1 "Lamp on" 0 "Lamp off";
VAL_ 2566836222 AmberWarningLampStatus 3 "Not available" 2 "Reserved" 1 "Lamp on" 0 "Lamp off";
VAL_ 2566836222 ProtectLampStatus 3 "Not available" 2 "Reserved" 1 "Lamp on" 0 "Lamp off";
VAL_ 2566835966 MisfireMonitoringSupport 3 "Not available" 2 "Reserved" 1 "test supported" 0 "test not supported";
VAL_ 2566835966 OBDCompliance 25 "OBD-M (SI-SD/I)" 23 "HD EOBD" 22 "OBD II (California, ARB 07/08)" 21 "WWH OBD" 20 "HD OBD" 19 "HD OBD P" 18 "EMD+" 17 "EMD" 16 "Heavy Duty Vehicles (EURO EEC) C" 15 "Heavy Duty Vehicles (EURO V) B2" 14 "Heavy Duty Vehicles (EURO IV) B1" 13 "JOBD, EOBD and OBD II" 12 "JOBD and EOBD" 11 "JOBD and OBD II" 10 "JOBD" 9 "EOBD, OBD and OBD II" 8 "EOBD and OBD" 7 "EOBD and OBD II" 6 "EOBD" 5 "Not intended to meet OBD II req." 4 "OBD I" 3 "OBD and OBD II" 2 "OBD (Federal, EPA)" 1 "OBD II (California, ARB)" 0 "Reserver for assignment by SAE";
VAL_ 2566835966 SecondAirSystemMonStatus 1 "TestNotComplete" 0 "TestComplete";
VAL_ 2566835966 EvaporativeSystemMonStatus 1 "TestNotComplete" 0 "TestComplete";
VAL_ 2566835966 ACSystemRefrigerantMonStatus 1 "TestNotComplete" 0 "TestComplete";
VAL_ 2566835966 OxygenSensorHeaterMonStatus 1 "TestNotComplete" 0 "TestComplete";
VAL_ 2566835966 OxygenSensorMonStatus 1 "test not complete" 0 "test complete";
VAL_ 2566835966 EGRSystemMonitoringStatus 1 "TestNotComplete" 0 "TestComplete";
VAL_ 2566835966 CatalystMonStatus 0 "TestComplete" 1 "TestNotComplete";
VAL_ 2566835966 ColdStartAidSystemMonStatus 1 "TestNotComplete" 0 "TestComplete";
VAL_ 2566835966 HeatedCatalystMonStatus 1 "TestNotComplete" 0 "TestComplete";
VAL_ 2566835966 CatalystMonSupp 1 "TestSupported" 0 "TestNotSupported";
VAL_ 2566835966 ColdStartAidSystemMonSupp 1 "TestSupported" 0 "TestNotSupported";
VAL_ 2566835966 HeatedCatalystMonSupp 1 "TestSupported" 0 "TestNotSupported";
VAL_ 2566835966 EvaporativeSystemMonSupp 1 "TestSupported" 0 "TestNotSupported";
VAL_ 2566835966 SecondAirSystemMonSupp 1 "TestSupported" 0 "TestNotSupported";
VAL_ 2566835966 ACSystemRefrigerantMonSupp 1 "TestSupported" 0 "TestNotSupported";
VAL_ 2566835966 OxygenSensorMonSupp 1 "TestSupported" 0 "TestNotSupported";
VAL_ 2566835966 OxygenSensorHeaterMonSupp 1 "TestSupported" 0 "TestNotSupported";
VAL_ 2566835966 EGRSystemMonitoringSupp 1 "TestSupported" 0 "TestNotSupported";
VAL_ 2566835966 MisfireMonitoringStatus 1 "test not complete" 0 "test complete";
VAL_ 2566835966 ComprehensiveCompMonStatus 1 "test not complete" 0 "test complete";
VAL_ 2566835966 FuelSystemMonitoringStatus 1 "test not complete" 0 "test complete";
VAL_ 2566835966 ComprehensiveComponentMonSupp 3 "Not available" 2 "Reserved" 1 "test supported" 0 "test not supported";
VAL_ 2566835966 FuelSystemMonitoringSupport 1 "test supported" 0 "test not supported";
VAL_ 2566835710 EngTorqueMode 15 "Not available" 11 "Remote accelerator" 10 "Braking system" 9 "High speed governor" 8 "Torque limiting" 7 "ABS control" 6 "Transmission control" 5 "ASR control" 4 "Road speed governor" 3 "PTO governor" 2 "Cruise control" 1 "Accelerator pedal/operator selec" 0 "Low idle governor/no request (de";
VAL_ 2566764286 SPNSupportTypeSTR3 1 "SupportedInScaledTestResults" 0 "NotSupportedInScaledTestResults";
VAL_ 2566764286 SPNSupportTypeSTR2 1 "SupportedInScaledTestResults" 0 "NotSupportedInScaledTestResults";
VAL_ 2566764286 SPNSupportTypeEFF3 1 "SupportedInExFreezeFrame" 0 "NotSupportedInExFreezeFrame";
VAL_ 2566764286 SPNSupportTypeEFF2 1 "SupportedInExFreezeFrame" 0 "NotSupportedInExFreezeFrame";
VAL_ 2566764286 SPNSupportTypeDS3 1 "SupportedInDataStream" 0 "NotSupportedInDataStream";
VAL_ 2566764286 SPNSupportTypeDS2 1 "SupportedInDataStream" 0 "NotSupportedInDataStream";
VAL_ 2566764286 SPNSupportTypeSTR1 1 "SupportedInScaledTestResults" 0 "NotSupportedInScaledTestResults";
VAL_ 2566764286 SPNSupportTypeDS1 1 "SupportedInDataStream" 0 "NotSupportedInDataStream";
VAL_ 2566764286 SPNSupportTypeEFF1 1 "SupportedInExFreezeFrame" 0 "NotSupportedInExFreezeFrame";
VAL_ 2566764030 FlashRedStopLamp 3 "Unavailable / Do Not Flash" 2 "Reserved" 1 "Fast Flash" 0 "Slow Flash";
VAL_ 2566764030 FlashProtectLamp 3 "Unavailable / Do Not Flash" 2 "Reserved" 1 "Fast Flash" 0 "Slow Flash";
VAL_ 2566764030 FlashMalfuncIndicatorLamp 3 "Unavailable / Do Not Flash" 2 "Reserved" 1 "Fast Flash" 0 "Slow Flash";
VAL_ 2566764030 FlashAmberWarningLamp 3 "Unavailable / Do Not Flash" 2 "Reserved" 1 "Fast Flash" 0 "Slow Flash";
VAL_ 2566764030 MalfunctionIndicatorLampStatus 3 "Not available" 2 "Reserved" 1 "Lamp on" 0 "Lamp off";
VAL_ 2566764030 RedStopLampState 3 "Not available" 2 "Reserved" 1 "Lamp on" 0 "Lamp off";
VAL_ 2566764030 AmberWarningLampStatus 3 "Not available" 2 "Reserved" 1 "Lamp on" 0 "Lamp off";
VAL_ 2566764030 ProtectLampStatus 3 "Not available" 2 "Reserved" 1 "Lamp on" 0 "Lamp off";
VAL_ 2562981630 FailureModeIdentifier1 31 "Not available" 19 "Received network data in error" 18 "Below normal (moderately severe)" 17 "Below normal (least severe)" 16 "Above normal (moderately severe)" 15 "Above normal (least severe)" 14 "Special intstructions" 13 "Out of calibration" 12 "Bad intelligent device" 11 "Root cause not known" 10 "Abnormal rate of change" 9 "Abnormal update rate" 8 "Abnormal frequency" 7 "Mechanical system not responding" 6 "Current above normal" 5 "Current below normal" 4 "Voltage below normal" 3 "Voltage above normal" 2 "Data erratic" 1 "Below normal (most severe)" 0 "Above normal (most severe)";
VAL_ 2566835198 MalfunctionIndicatorLampStatus 3 "Not available" 2 "Reserved" 1 "Lamp on" 0 "Lamp off";
VAL_ 2566835198 RedStopLampState 3 "Not available" 2 "Reserved" 1 "Lamp on" 0 "Lamp off";
VAL_ 2566835198 AmberWarningLampStatus 3 "Not available" 2 "Reserved" 1 "Lamp on" 0 "Lamp off";
VAL_ 2566835198 ProtectLampStatus 3 "Not available" 2 "Reserved" 1 "Lamp on" 0 "Lamp off";
VAL_ 2566835198 FlashRedStopLamp 3 "Unavailable / Do Not Flash" 2 "Reserved" 1 "Fast Flash" 0 "Slow Flash";
VAL_ 2566835198 FlashProtectLamp 3 "Unavailable / Do Not Flash" 2 "Reserved" 1 "Fast Flash" 0 "Slow Flash";
VAL_ 2566835198 FlashMalfuncIndicatorLamp 3 "Unavailable / Do Not Flash" 2 "Reserved" 1 "Fast Flash" 0 "Slow Flash";
VAL_ 2566835198 FlashAmberWarningLamp 3 "Unavailable / Do Not Flash" 2 "Reserved" 1 "Fast Flash" 0 "Slow Flash";
VAL_ 2564357886 Seed 255 "NoFurtherKeyRequiredOfTool" 1 "UseLongSeedOrKeyFromDataSecMsg" 0 "SeedCompleted_BeginSendingKey";
VAL_ 2564357886 EDCP_Extension 9 "DataInErrIndAndDataInSeedIsTime" 6 "DataInErrorIndicator" 3 "ConcatenateDataAsLowerEDCParam" 2 "ConcatenateDataAsHigherEDCParam" 0 "Completed" 255 "NoErrIndicator/EDCParamAvailable";
VAL_ 2564357886 ErrorIndicator 16777215 "NoErrorIndicatorAvailable" 65540 "TransprtNotComplWithinTimeAllowd" 65539 "TransportNotInitWithinTimeAllowd" 65538 "NoResponseInTheTimeAllowed" 65537 "ModuleExceedingNumberOfRetries" 65536 "AbortFromExtToNormalSoftwareProc" 4103 "VehicleNotInParkOrNotStationary" 4102 "EngineRunning" 4101 "NotInEngineeringOrDevelopmentMode" 4100 "NotInDiagnosticMode" 4099 "InvalidKey" 4098 "InvalidUserLevel" 4097 "InvalidPassword" 4096 "SecurityErrorGeneral" 266 "NameDoesNotConformToExpectdValue" 265 "DataDoesNotConformToValueRanges" 264 "AddrForBootLoadExeInvalidBoundary" 263 "AddrForBootLoadExeOutsideExeMem" 262 "OpReqExeTransfAndEraseOfProgMem" 261 "OpRequiresPriorEraseOfProgramMem" 260 "OpRequiresPriorEraseOfDataMem" 259 "ReqMemoryExceededAvailableMemory" 258 "LengthNotValidForMemStructAndOp" 257 "AddressNotOnValidBoundary" 256 "AddressingOrDataGeneralError" 36 "InternalFailurePreventingReq" 35 "PROMDidNotVerifyOnWrite" 34 "FLASHDidNotVerifyOnWrite" 33 "RAMDidNotVerifyOnWrite" 32 "EDCParaNotCorrectForDataStream" 31 "ProcessUnspecReqFromThisAddress" 23 "ProcessingEDCPGenerationReq" 22 "ProcessingBootLoadReq" 19 "ProcessingStatusReq" 18 "ProcessingWriteReq" 17 "ProcessingReadReq" 16 "ProcessingEraseReq" 2 "ProcessingForSomeoneElse" 1 "ErrorNotIdentified" 0 "NoError";
VAL_ 2564357886 Status 7 "Reserved" 6 "Reserved" 5 "OperationFailed" 4 "OperationCompleted" 3 "Reserved" 2 "Reserved" 1 "Busy" 0 "Proceed";
VAL_ 2564423422 KeyOrUserLevel 65535 "NoKeyAvailable" 0 "UseLongSeedOrKey";
VAL_ 2564423422 PointerExtension 0 "SPN_SPACE";
VAL_ 2564423422 Command 7 "EDCP_Generation" 6 "BootLoad" 5 "OperationFailed" 4 "OperationCompleted" 3 "StatusRequest" 2 "Write" 1 "Read" 0 "Erase";
VAL_ 2564423422 PointerType 1 "DirectedSpatialAddressing" 0 "DirectMemoryAddressing";
VAL_ 2564816638 HoldSignal 15 "Not available" 1 "Devices whose broadcast state ha" 0 "All devices";
VAL_ 2564816638 J1939Network3 3 "Don't care" 2 "Reserved" 1 "Start broadcast" 0 "Stop broadcast";
VAL_ 2564816638 J1939Network2 3 "Don't care" 2 "Reserved" 1 "Start broadcast" 0 "Stop broadcast";
VAL_ 2564816638 ISO9141 3 "Don't care" 2 "Reserved" 1 "Start broadcast" 0 "Stop broadcast";
VAL_ 2564816638 SAE_J1850 3 "Don't care" 2 "Reserved" 1 "Start broadcast" 0 "Stop broadcast";
VAL_ 2564816638 ManufacturerSpecificPort 3 "Don't care" 2 "Reserved" 1 "Start broadcast" 0 "Stop broadcast";
VAL_ 2564816638 CurrentDataLink 3 "Don't care" 2 "Reserved" 1 "Start broadcast" 0 "Stop broadcast";
VAL_ 2564816638 SAE_J1587 3 "Don't care" 2 "Reserved" 1 "Start broadcast" 0 "Stop broadcast";
VAL_ 2564816638 SAE_J1922 3 "Don't care" 2 "Reserved" 1 "Start broadcast" 0 "Stop broadcast";
VAL_ 2564816638 J1939Network1 3 "Don't care" 2 "Reserved" 1 "Start broadcast" 0 "Stop broadcast";
VAL_ 2564816638 SuspendSignal 15 "NotAvailable" 14 "ResumingNormalBroadcastPattern" 3 "TemporarySuspensionOfSomeMessages" 2 "TemporarySuspensionOfAllBroadcasts" 1 "IndefiniteSuspensionOfSomeMessages" 0 "IndefiniteSuspensionOfAllBroadcasts";
VAL_ 2566837502 FlashRedStopLamp 3 "Unavailable / Do Not Flash" 2 "Reserved" 1 "Fast Flash" 0 "Slow Flash";
VAL_ 2566837502 FlashProtectLamp 3 "Unavailable / Do Not Flash" 2 "Reserved" 1 "Fast Flash" 0 "Slow Flash";
VAL_ 2566837502 MalfunctionIndicatorLampStatus 3 "Not available" 2 "Reserved" 1 "Lamp on" 0 "Lamp off";
VAL_ 2566837502 RedStopLampState 3 "Not available" 2 "Reserved" 1 "Lamp on" 0 "Lamp off";
VAL_ 2566837502 AmberWarningLampStatus 3 "Not available" 2 "Reserved" 1 "Lamp on" 0 "Lamp off";
VAL_ 2566837502 ProtectLampStatus 3 "Not available" 2 "Reserved" 1 "Lamp on" 0 "Lamp off";
VAL_ 2566837502 FlashMalfuncIndicatorLamp 3 "Unavailable / Do Not Flash" 2 "Reserved" 1 "Fast Flash" 0 "Slow Flash";
VAL_ 2566837502 FlashAmberWarningLamp 3 "Unavailable / Do Not Flash" 2 "Reserved" 1 "Fast Flash" 0 "Slow Flash";
VAL_ 2566834942 FlashRedStopLamp 3 "Unavailable / Do Not Flash" 2 "Reserved" 1 "Fast Flash" 0 "Slow Flash";
VAL_ 2566834942 FlashProtectLamp 3 "Unavailable / Do Not Flash" 2 "Reserved" 1 "Fast Flash" 0 "Slow Flash";
VAL_ 2566834942 FlashMalfuncIndicatorLamp 3 "Unavailable / Do Not Flash" 2 "Reserved" 1 "Fast Flash" 0 "Slow Flash";
VAL_ 2566834942 FlashAmberWarningLamp 3 "Unavailable / Do Not Flash" 2 "Reserved" 1 "Fast Flash" 0 "Slow Flash";
VAL_ 2566834942 MalfunctionIndicatorLampStatus 3 "Not available" 2 "Reserved" 1 "Lamp on" 0 "Lamp off";
VAL_ 2566834942 AmberWarningLampStatus 3 "Not available" 2 "Reserved" 1 "Lamp on" 0 "Lamp off";
VAL_ 2566834942 RedStopLampState 3 "Not available" 2 "Reserved" 1 "Lamp on" 0 "Lamp off";
VAL_ 2566834942 ProtectLampStatus 3 "Not available" 2 "Reserved" 1 "Lamp on" 0 "Lamp off";
VAL_ 2566784254 GnrtorOverallPowerFactorLagging 3 "NotAvailable_NotInstalled" 2 "Error" 1 "Lagging" 0 "Leading";
VAL_ 2566781950 GnratorPhaseCPowerFactorLagging 3 "NotAvailable_NotInstalled" 2 "Error" 1 "Lagging" 0 "Leading";
VAL_ 2566782718 GnratorPhaseBPowerFactorLagging 3 "NotAvailable_NotInstalled" 2 "Error" 1 "Lagging" 0 "Leading";
